VERSION ""

NS_ :

BS_:

BU_: PowertrainControlModule AtmosphericSensor SafetyRestraintSystem2 Aftertreatment_2_GasOutlet Aftertreatment_2_GasIntake DieselParticulateFilterControl Turbocharger SafetyRestraintSystem1 CabDisplay2 Aftertreatment_1_GasOutlet Aftertreatment_1_GasIntake OnBoardDataLogger OffBoardDiagnosticTool2 OffBoardDiagnosticTool1 FileServer ParkingBrakeController SeatController2 FanDriveController SteeringColumnUnit CommunicationUnitRadio CommunicationUnitSatellite CommunicationUnitCellular PropulsionBatteryCharger ChassisController2 ChassisController1 EngineValveControl AuxiliaryHeater2 AuxiliaryHeater1 ClutchUnit RampControl InformationSystem1 SuspensionSystemController2 OilSensor VehicleDynamicStability ExhaustEmissionController TransmissionDisplay2 TransmissionDisplay1 ClimateControl2 WaterPumpController RearAxleSteeringController LightingOperatorControl SeatController1 IgnitionController2 IgnitionController1 TirePressureController CabController2 CabController1 PneumaticSystemController SuspensionSystemController1 HydraulicPumpController EnduranceBrakingSystem RetarderExhaustEngine2 OnBoardDiagnosticUnit HeadwayController RetarderExhaustEngine1 CabDisplay1 ManagementComputer VirtualTerminal OffVehicleGateway PowerTakeOffFront HitchControl AuxiliaryValveControl BodyController TractorTrailerBridge1 StarterSystem ElectricalSystem VehicleSecurity VehicleNavigation AerodynamicControl ElectricalChargingSystem ClimateControl1 TripRecorder InstrumentCluster SuspensionDriveAxle2 SuspensionDriveAxle1 SuspensionSteerAxle SteeringController FuelSystem CruiseControl RetarderDriveline RetarderEngine BrakesDriveAxle2 BrakesDriveAxle1 BrakesSystemController BrakesSteerAxle AxleDrive2 AxleDrive1 AxleSteering PowerTakeOff ShiftConsoleSecondary ShiftConsolePrimary Transmission2 Transmission1 Engine2 Engine1

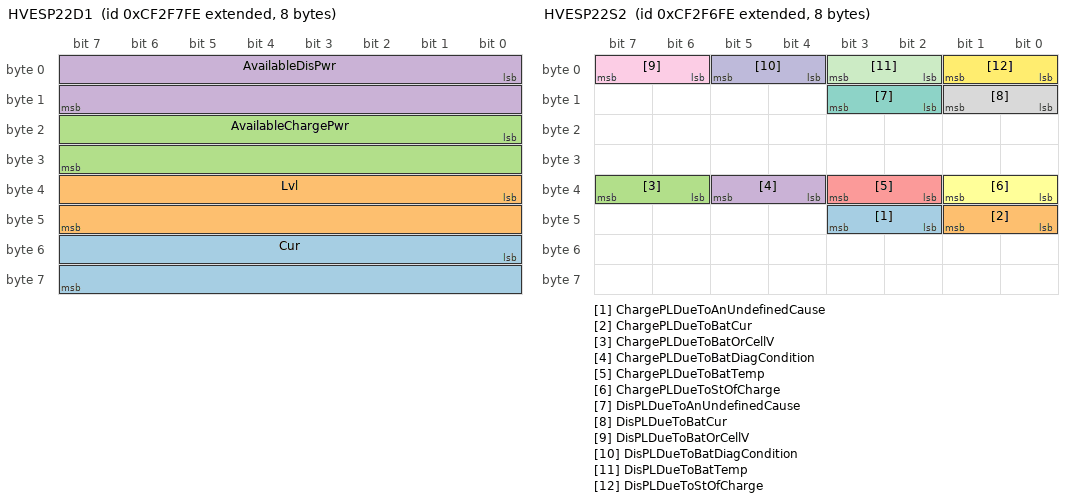
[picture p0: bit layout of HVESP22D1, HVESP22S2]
BO_ 2364733438 HVESP22D1: 8 Vector__XXX
 SG_ Cur : 48|16@1+ (0.05,-1600) [-1600|1612.75] "A" Vector__XXX
 SG_ Lvl : 32|16@1+ (0.05,0) [0|3212.75] "V" Vector__XXX
 SG_ AvailableChargePwr : 16|16@1+ (0.05,0) [0|3212.75] "kW" Vector__XXX
 SG_ AvailableDisPwr : 0|16@1+ (0.05,0) [0|3212.75] "kW" Vector__XXX

BO_ 2364733182 HVESP22S2: 8 Vector__XXX
 SG_ ChargePLDueToAnUndefinedCause : 42|2@1+ (1,0) [0|3] "" Vector__XXX
 SG_ ChargePLDueToBatCur : 40|2@1+ (1,0) [0|3] "" Vector__XXX
 SG_ ChargePLDueToBatOrCellV : 38|2@1+ (1,0) [0|3] "" Vector__XXX
 SG_ ChargePLDueToBatDiagCondition : 36|2@1+ (1,0) [0|3] "" Vector__XXX
 SG_ ChargePLDueToBatTemp : 34|2@1+ (1,0) [0|3] "" Vector__XXX
 SG_ ChargePLDueToStOfCharge : 32|2@1+ (1,0) [0|3] "" Vector__XXX
 SG_ DisPLDueToAnUndefinedCause : 10|2@1+ (1,0) [0|3] "" Vector__XXX
 SG_ DisPLDueToBatCur : 8|2@1+ (1,0) [0|3] "" Vector__XXX
 SG_ DisPLDueToBatOrCellV : 6|2@1+ (1,0) [0|3] "" Vector__XXX
 SG_ DisPLDueToBatDiagCondition : 4|2@1+ (1,0) [0|3] "" Vector__XXX
 SG_ DisPLDueToBatTemp : 2|2@1+ (1,0) [0|3] "" Vector__XXX
 SG_ DisPLDueToStOfCharge : 0|2@1+ (1,0) [0|3] "" Vector__XXX

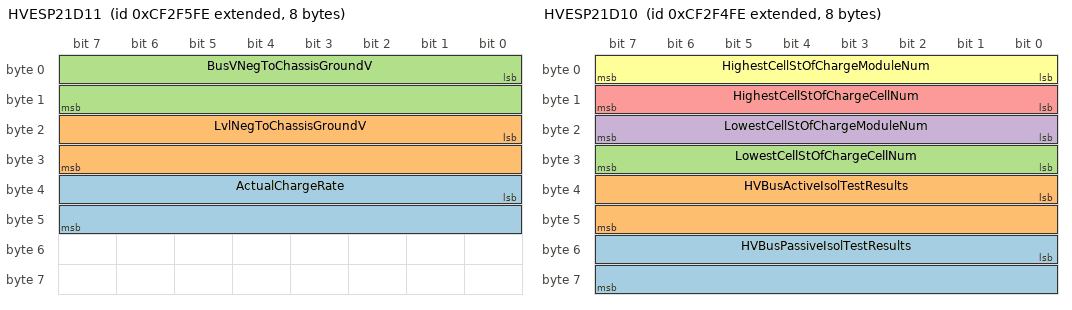
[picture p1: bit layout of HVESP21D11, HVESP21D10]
BO_ 2364732926 HVESP21D11: 8 Vector__XXX
 SG_ ActualChargeRate : 32|16@1+ (0.05,0) [0|3212.75] "kW" Vector__XXX
 SG_ LvlNegToChassisGroundV : 16|16@1+ (0.05,0) [0|3212.75] "V" Vector__XXX
 SG_ BusVNegToChassisGroundV : 0|16@1+ (0.05,0) [0|3212.75] "V" Vector__XXX

BO_ 2364732670 HVESP21D10: 8 Vector__XXX
 SG_ HVBusPassiveIsolTestResults : 48|16@1+ (0.1,0) [0|6425.5] "Ohm/V" Vector__XXX
 SG_ HVBusActiveIsolTestResults : 32|16@1+ (0.1,0) [0|6425.5] "Ohm/V" Vector__XXX
 SG_ LowestCellStOfChargeCellNum : 24|8@1+ (1,0) [0|250] "" Vector__XXX
 SG_ LowestCellStOfChargeModuleNum : 16|8@1+ (1,0) [0|250] "" Vector__XXX
 SG_ HighestCellStOfChargeCellNum : 8|8@1+ (1,0) [0|250] "" Vector__XXX
 SG_ HighestCellStOfChargeModuleNum : 0|8@1+ (1,0) [0|250] "" Vector__XXX

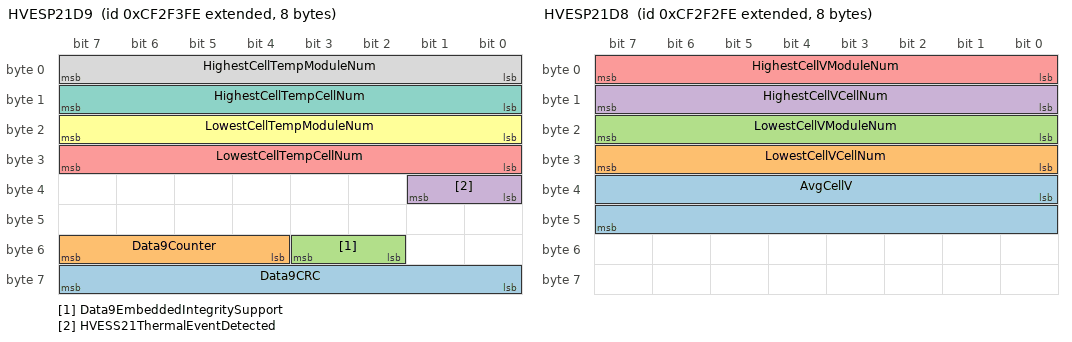
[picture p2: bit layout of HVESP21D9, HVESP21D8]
BO_ 2364732414 HVESP21D9: 8 Vector__XXX
 SG_ Data9CRC : 56|8@1+ (1,0) [0|255] "" Vector__XXX
 SG_ Data9Counter : 52|4@1+ (1,0) [0|15] "" Vector__XXX
 SG_ Data9EmbeddedIntegritySupport : 50|2@1+ (1,0) [0|3] "" Vector__XXX
 SG_ HVESS21ThermalEventDetected : 32|2@1+ (1,0) [0|3] "" Vector__XXX
 SG_ LowestCellTempCellNum : 24|8@1+ (1,0) [0|250] "" Vector__XXX
 SG_ LowestCellTempModuleNum : 16|8@1+ (1,0) [0|250] "" Vector__XXX
 SG_ HighestCellTempCellNum : 8|8@1+ (1,0) [0|250] "" Vector__XXX
 SG_ HighestCellTempModuleNum : 0|8@1+ (1,0) [0|250] "" Vector__XXX

BO_ 2364732158 HVESP21D8: 8 Vector__XXX
 SG_ AvgCellV : 32|16@1+ (0.001,0) [0|64.255] "V" Vector__XXX
 SG_ LowestCellVCellNum : 24|8@1+ (1,0) [0|250] "" Vector__XXX
 SG_ LowestCellVModuleNum : 16|8@1+ (1,0) [0|250] "" Vector__XXX
 SG_ HighestCellVCellNum : 8|8@1+ (1,0) [0|250] "" Vector__XXX
 SG_ HighestCellVModuleNum : 0|8@1+ (1,0) [0|250] "" Vector__XXX

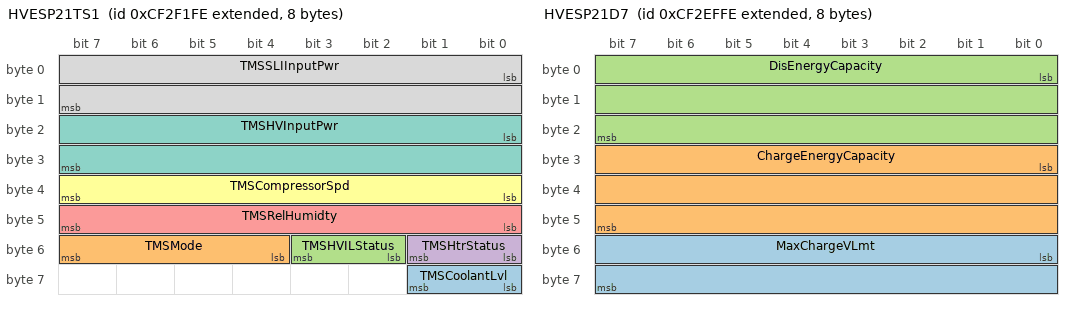
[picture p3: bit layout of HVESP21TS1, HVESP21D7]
BO_ 2364731902 HVESP21TS1: 8 Vector__XXX
 SG_ TMSCoolantLvl : 56|2@1+ (1,0) [0|3] "" Vector__XXX
 SG_ TMSMode : 52|4@1+ (1,0) [0|15] "" Vector__XXX
 SG_ TMSHVILStatus : 50|2@1+ (1,0) [0|3] "" Vector__XXX
 SG_ TMSHtrStatus : 48|2@1+ (1,0) [0|3] "" Vector__XXX
 SG_ TMSRelHumidty : 40|8@1+ (0.4,0) [0|100] "%" Vector__XXX
 SG_ TMSCompressorSpd : 32|8@1+ (32,0) [0|8000] "rpm" Vector__XXX
 SG_ TMSHVInputPwr : 16|16@1+ (0.5,0) [0|32127.5] "W" Vector__XXX
 SG_ TMSSLIInputPwr : 0|16@1+ (0.5,0) [0|32127.5] "W" Vector__XXX

BO_ 2364731646 HVESP21MS1: 8 Vector__XXX
 SG_ Module32OperationalStatus : 62|2@1+ (1,0) [0|3] "" Vector__XXX
 SG_ Module31OperationalStatus : 60|2@1+ (1,0) [0|3] "" Vector__XXX
 SG_ Module30OperationalStatus : 58|2@1+ (1,0) [0|3] "" Vector__XXX
 SG_ Module29OperationalStatus : 56|2@1+ (1,0) [0|3] "" Vector__XXX
 SG_ Module28OperationalStatus : 54|2@1+ (1,0) [0|3] "" Vector__XXX
 SG_ Module27OperationalStatus : 52|2@1+ (1,0) [0|3] "" Vector__XXX
 SG_ Module26OperationalStatus : 50|2@1+ (1,0) [0|3] "" Vector__XXX
 SG_ Module25OperationalStatus : 48|2@1+ (1,0) [0|3] "" Vector__XXX
 SG_ Module24OperationalStatus : 46|2@1+ (1,0) [0|3] "" Vector__XXX
 SG_ Module23OperationalStatus : 44|2@1+ (1,0) [0|3] "" Vector__XXX
 SG_ Module22OperationalStatus : 42|2@1+ (1,0) [0|3] "" Vector__XXX
 SG_ Module21OperationalStatus : 40|2@1+ (1,0) [0|3] "" Vector__XXX
 SG_ Module20OperationalStatus : 38|2@1+ (1,0) [0|3] "" Vector__XXX
 SG_ Module19OperationalStatus : 36|2@1+ (1,0) [0|3] "" Vector__XXX
 SG_ Module18OperationalStatus : 34|2@1+ (1,0) [0|3] "" Vector__XXX
 SG_ Module17OperationalStatus : 32|2@1+ (1,0) [0|3] "" Vector__XXX
 SG_ Module16OperationalStatus : 30|2@1+ (1,0) [0|3] "" Vector__XXX
 SG_ Module15OperationalStatus : 28|2@1+ (1,0) [0|3] "" Vector__XXX
 SG_ Module14OperationalStatus : 26|2@1+ (1,0) [0|3] "" Vector__XXX
 SG_ Module13OperationalStatus : 24|2@1+ (1,0) [0|3] "" Vector__XXX
 SG_ Module12OperationalStatus : 22|2@1+ (1,0) [0|3] "" Vector__XXX
 SG_ Module11OperationalStatus : 20|2@1+ (1,0) [0|3] "" Vector__XXX
 SG_ Module10OperationalStatus : 18|2@1+ (1,0) [0|3] "" Vector__XXX
 SG_ Module9OperationalStatus : 16|2@1+ (1,0) [0|3] "" Vector__XXX
 SG_ Module8OperationalStatus : 14|2@1+ (1,0) [0|3] "" Vector__XXX
 SG_ Module7OperationalStatus : 12|2@1+ (1,0) [0|3] "" Vector__XXX
 SG_ Module6OperationalStatus : 10|2@1+ (1,0) [0|3] "" Vector__XXX
 SG_ Module5OperationalStatus : 8|2@1+ (1,0) [0|3] "" Vector__XXX
 SG_ Module4OperationalStatus : 6|2@1+ (1,0) [0|3] "" Vector__XXX
 SG_ Module3OperationalStatus : 4|2@1+ (1,0) [0|3] "" Vector__XXX
 SG_ Module2OperationalStatus : 2|2@1+ (1,0) [0|3] "" Vector__XXX
 SG_ Module1OperationalStatus : 0|2@1+ (1,0) [0|3] "" Vector__XXX

BO_ 2364731390 HVESP21D7: 8 Vector__XXX
 SG_ MaxChargeVLmt : 48|16@1+ (0.05,0) [0|3212.75] "V" Vector__XXX
 SG_ ChargeEnergyCapacity : 24|24@1+ (0.001,0) [0|16449.535] "kWh" Vector__XXX
 SG_ DisEnergyCapacity : 0|24@1+ (0.001,0) [0|16449.535] "kWh" Vector__XXX

BO_ 2364731134 HVESP21S1: 8 Vector__XXX
 SG_ Status1CRC : 56|8@1+ (1,0) [0|255] "" Vector__XXX
 SG_ Status1Counter : 52|4@1+ (1,0) [0|15] "" Vector__XXX
 SG_ OperationalStatus : 44|4@1+ (1,0) [0|15] "" Vector__XXX
 SG_ HVBusConnectionStatus : 40|4@1+ (1,0) [0|15] "" Vector__XXX
 SG_ InternalChargerStatus : 32|2@1+ (1,0) [0|3] "" Vector__XXX
 SG_ CellBalancingActive : 30|2@1+ (1,0) [0|3] "" Vector__XXX
 SG_ CellBalanceStatus : 28|2@1+ (1,0) [0|3] "" Vector__XXX
 SG_ StOfChargeStatus : 24|4@1+ (1,0) [0|15] "" Vector__XXX
 SG_ InertiaSwStatus : 22|2@1+ (1,0) [0|3] "" Vector__XXX
 SG_ HVILStatus : 20|2@1+ (1,0) [0|3] "" Vector__XXX
 SG_ HVBusPassiveIsolTestStatus : 16|4@1+ (1,0) [0|15] "" Vector__XXX
 SG_ HVBusActiveIsolTestStatus : 12|4@1+ (1,0) [0|15] "" Vector__XXX
 SG_ CenterOfPackContactorSt : 10|2@1+ (1,0) [0|3] "" Vector__XXX
 SG_ HVBusPreChargeRelaySt : 8|2@1+ (1,0) [0|3] "" Vector__XXX
 SG_ HVBusDisconnectForewarning : 4|4@1+ (1,0) [0|15] "" Vector__XXX
 SG_ HVBusContactorSt16738 : 2|2@1+ (1,0) [0|3] "" Vector__XXX
 SG_ HVBusContactorSt : 0|2@1+ (1,0) [0|3] "" Vector__XXX

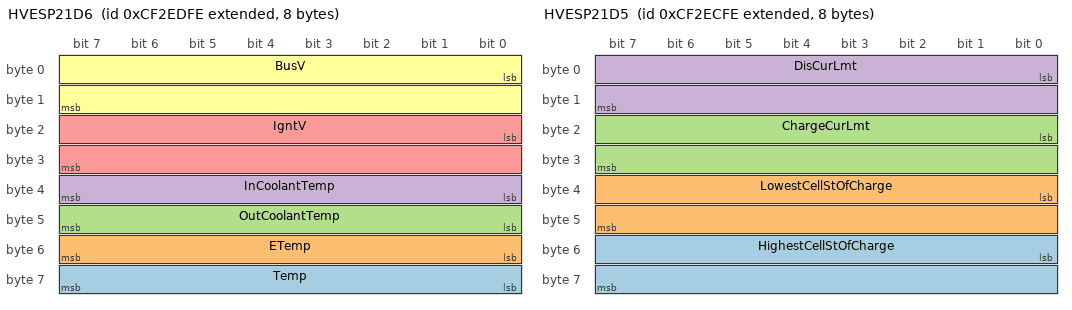
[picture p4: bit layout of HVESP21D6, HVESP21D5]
BO_ 2364730878 HVESP21D6: 8 Vector__XXX
 SG_ Temp : 56|8@1+ (1,-40) [-40|210] "°C" Vector__XXX
 SG_ ETemp : 48|8@1+ (1,-40) [-40|210] "°C" Vector__XXX
 SG_ OutCoolantTemp : 40|8@1+ (1,-40) [-40|210] "°C" Vector__XXX
 SG_ InCoolantTemp : 32|8@1+ (1,-40) [-40|210] "°C" Vector__XXX
 SG_ IgntV : 16|16@1+ (0.01,0) [0|642.55] "V" Vector__XXX
 SG_ BusV : 0|16@1+ (0.05,0) [0|3212.75] "V" Vector__XXX

BO_ 2364730622 HVESP21D5: 8 Vector__XXX
 SG_ HighestCellStOfCharge : 48|16@1+ (0.0015625,0) [0|100.3984375] "%" Vector__XXX
 SG_ LowestCellStOfCharge : 32|16@1+ (0.0015625,0) [0|100.3984375] "%" Vector__XXX
 SG_ ChargeCurLmt : 16|16@1+ (0.05,-1600) [0|1612.75] "A" Vector__XXX
 SG_ DisCurLmt : 0|16@1+ (0.05,-1600) [-1600|0] "A" Vector__XXX

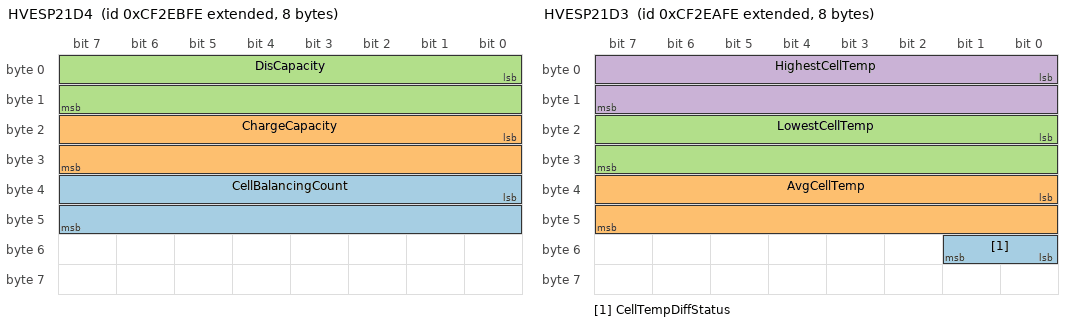
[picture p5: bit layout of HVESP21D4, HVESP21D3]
BO_ 2364730366 HVESP21D4: 8 Vector__XXX
 SG_ CellBalancingCount : 32|16@1+ (1,0) [0|64255] "" Vector__XXX
 SG_ ChargeCapacity : 16|16@1+ (0.01,0) [0|642.55] "Ah" Vector__XXX
 SG_ DisCapacity : 0|16@1+ (0.01,0) [0|642.55] "Ah" Vector__XXX

BO_ 2364730110 HVESP21D3: 8 Vector__XXX
 SG_ CellTempDiffStatus : 48|2@1+ (1,0) [0|3] "" Vector__XXX
 SG_ AvgCellTemp : 32|16@1+ (0.03125,-273) [-273|1734.96875] "°C" Vector__XXX
 SG_ LowestCellTemp : 16|16@1+ (0.03125,-273) [-273|1734.96875] "°C" Vector__XXX
 SG_ HighestCellTemp : 0|16@1+ (0.03125,-273) [-273|1734.96875] "°C" Vector__XXX

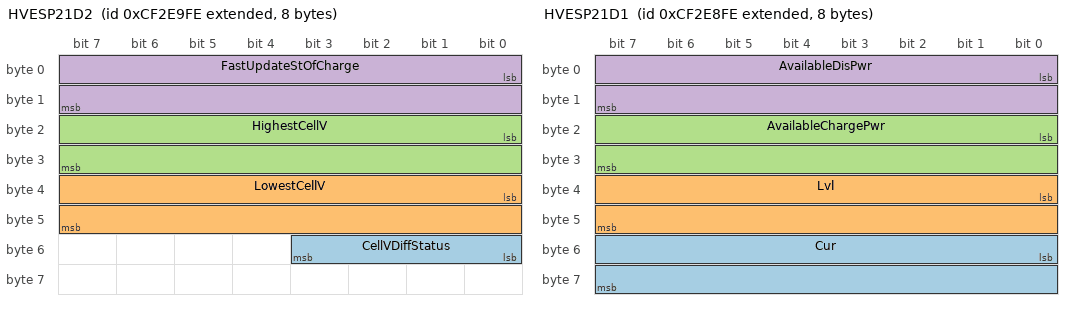
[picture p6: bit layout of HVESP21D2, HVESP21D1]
BO_ 2364729854 HVESP21D2: 8 Vector__XXX
 SG_ CellVDiffStatus : 48|4@1+ (1,0) [0|15] "" Vector__XXX
 SG_ LowestCellV : 32|16@1+ (0.001,0) [0|64.255] "V" Vector__XXX
 SG_ HighestCellV : 16|16@1+ (0.001,0) [0|64.255] "V" Vector__XXX
 SG_ FastUpdateStOfCharge : 0|16@1+ (0.0015625,0) [0|100.3984375] "%" Vector__XXX

BO_ 2364729598 HVESP21D1: 8 Vector__XXX
 SG_ Cur : 48|16@1+ (0.05,-1600) [-1600|1612.75] "A" Vector__XXX
 SG_ Lvl : 32|16@1+ (0.05,0) [0|3212.75] "V" Vector__XXX
 SG_ AvailableChargePwr : 16|16@1+ (0.05,0) [0|3212.75] "kW" Vector__XXX
 SG_ AvailableDisPwr : 0|16@1+ (0.05,0) [0|3212.75] "kW" Vector__XXX

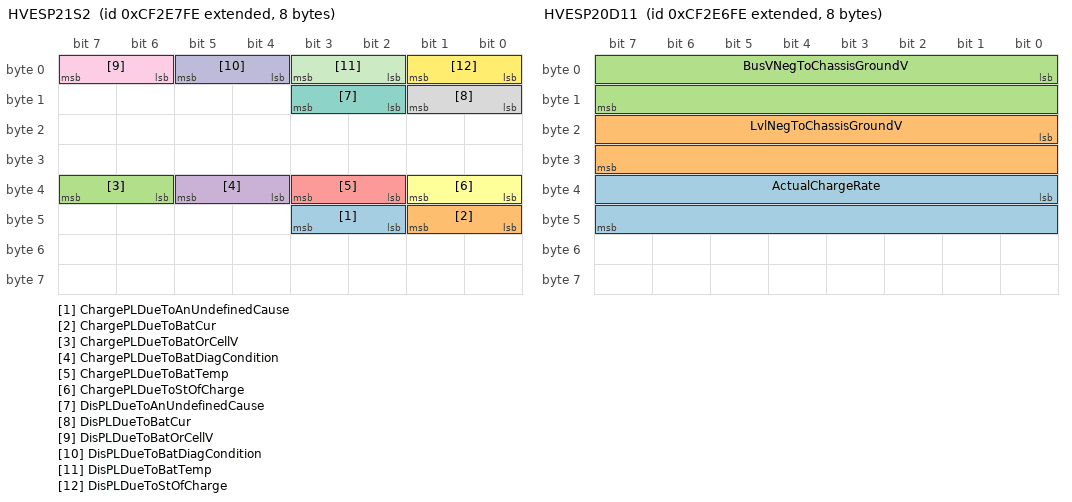
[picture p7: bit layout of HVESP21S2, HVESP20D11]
BO_ 2364729342 HVESP21S2: 8 Vector__XXX
 SG_ ChargePLDueToAnUndefinedCause : 42|2@1+ (1,0) [0|3] "" Vector__XXX
 SG_ ChargePLDueToBatCur : 40|2@1+ (1,0) [0|3] "" Vector__XXX
 SG_ ChargePLDueToBatOrCellV : 38|2@1+ (1,0) [0|3] "" Vector__XXX
 SG_ ChargePLDueToBatDiagCondition : 36|2@1+ (1,0) [0|3] "" Vector__XXX
 SG_ ChargePLDueToBatTemp : 34|2@1+ (1,0) [0|3] "" Vector__XXX
 SG_ ChargePLDueToStOfCharge : 32|2@1+ (1,0) [0|3] "" Vector__XXX
 SG_ DisPLDueToAnUndefinedCause : 10|2@1+ (1,0) [0|3] "" Vector__XXX
 SG_ DisPLDueToBatCur : 8|2@1+ (1,0) [0|3] "" Vector__XXX
 SG_ DisPLDueToBatOrCellV : 6|2@1+ (1,0) [0|3] "" Vector__XXX
 SG_ DisPLDueToBatDiagCondition : 4|2@1+ (1,0) [0|3] "" Vector__XXX
 SG_ DisPLDueToBatTemp : 2|2@1+ (1,0) [0|3] "" Vector__XXX
 SG_ DisPLDueToStOfCharge : 0|2@1+ (1,0) [0|3] "" Vector__XXX

BO_ 2364729086 HVESP20D11: 8 Vector__XXX
 SG_ ActualChargeRate : 32|16@1+ (0.05,0) [0|3212.75] "kW" Vector__XXX
 SG_ LvlNegToChassisGroundV : 16|16@1+ (0.05,0) [0|3212.75] "V" Vector__XXX
 SG_ BusVNegToChassisGroundV : 0|16@1+ (0.05,0) [0|3212.75] "V" Vector__XXX

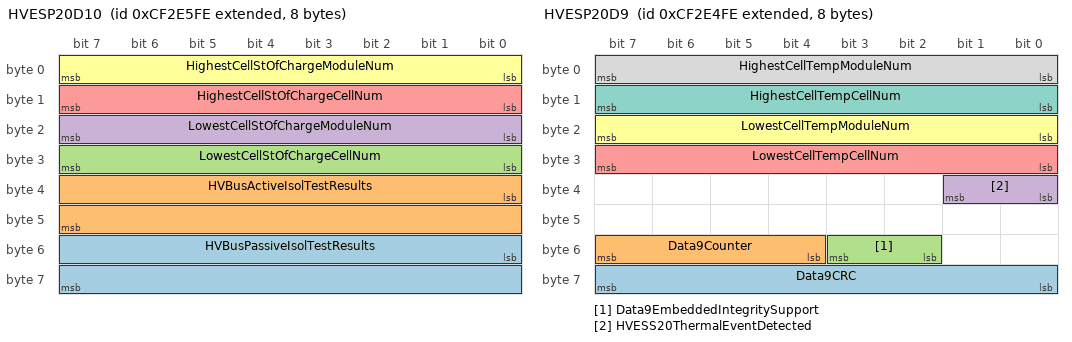
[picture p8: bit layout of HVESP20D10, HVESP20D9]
BO_ 2364728830 HVESP20D10: 8 Vector__XXX
 SG_ HVBusPassiveIsolTestResults : 48|16@1+ (0.1,0) [0|6425.5] "Ohm/V" Vector__XXX
 SG_ HVBusActiveIsolTestResults : 32|16@1+ (0.1,0) [0|6425.5] "Ohm/V" Vector__XXX
 SG_ LowestCellStOfChargeCellNum : 24|8@1+ (1,0) [0|250] "" Vector__XXX
 SG_ LowestCellStOfChargeModuleNum : 16|8@1+ (1,0) [0|250] "" Vector__XXX
 SG_ HighestCellStOfChargeCellNum : 8|8@1+ (1,0) [0|250] "" Vector__XXX
 SG_ HighestCellStOfChargeModuleNum : 0|8@1+ (1,0) [0|250] "" Vector__XXX

BO_ 2364728574 HVESP20D9: 8 Vector__XXX
 SG_ Data9CRC : 56|8@1+ (1,0) [0|255] "" Vector__XXX
 SG_ Data9Counter : 52|4@1+ (1,0) [0|15] "" Vector__XXX
 SG_ Data9EmbeddedIntegritySupport : 50|2@1+ (1,0) [0|3] "" Vector__XXX
 SG_ HVESS20ThermalEventDetected : 32|2@1+ (1,0) [0|3] "" Vector__XXX
 SG_ LowestCellTempCellNum : 24|8@1+ (1,0) [0|250] "" Vector__XXX
 SG_ LowestCellTempModuleNum : 16|8@1+ (1,0) [0|250] "" Vector__XXX
 SG_ HighestCellTempCellNum : 8|8@1+ (1,0) [0|250] "" Vector__XXX
 SG_ HighestCellTempModuleNum : 0|8@1+ (1,0) [0|250] "" Vector__XXX

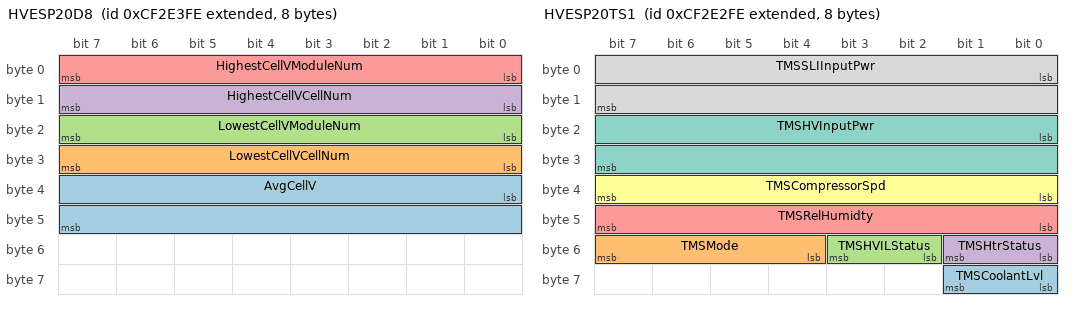
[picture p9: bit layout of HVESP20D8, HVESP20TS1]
BO_ 2364728318 HVESP20D8: 8 Vector__XXX
 SG_ AvgCellV : 32|16@1+ (0.001,0) [0|64.255] "V" Vector__XXX
 SG_ LowestCellVCellNum : 24|8@1+ (1,0) [0|250] "" Vector__XXX
 SG_ LowestCellVModuleNum : 16|8@1+ (1,0) [0|250] "" Vector__XXX
 SG_ HighestCellVCellNum : 8|8@1+ (1,0) [0|250] "" Vector__XXX
 SG_ HighestCellVModuleNum : 0|8@1+ (1,0) [0|250] "" Vector__XXX

BO_ 2364728062 HVESP20TS1: 8 Vector__XXX
 SG_ TMSCoolantLvl : 56|2@1+ (1,0) [0|3] "" Vector__XXX
 SG_ TMSMode : 52|4@1+ (1,0) [0|15] "" Vector__XXX
 SG_ TMSHVILStatus : 50|2@1+ (1,0) [0|3] "" Vector__XXX
 SG_ TMSHtrStatus : 48|2@1+ (1,0) [0|3] "" Vector__XXX
 SG_ TMSRelHumidty : 40|8@1+ (0.4,0) [0|100] "%" Vector__XXX
 SG_ TMSCompressorSpd : 32|8@1+ (32,0) [0|8000] "rpm" Vector__XXX
 SG_ TMSHVInputPwr : 16|16@1+ (0.5,0) [0|32127.5] "W" Vector__XXX
 SG_ TMSSLIInputPwr : 0|16@1+ (0.5,0) [0|32127.5] "W" Vector__XXX

BO_ 2364727806 HVESP20MS1: 8 Vector__XXX
 SG_ Module32OperationalStatus : 62|2@1+ (1,0) [0|3] "" Vector__XXX
 SG_ Module31OperationalStatus : 60|2@1+ (1,0) [0|3] "" Vector__XXX
 SG_ Module30OperationalStatus : 58|2@1+ (1,0) [0|3] "" Vector__XXX
 SG_ Module29OperationalStatus : 56|2@1+ (1,0) [0|3] "" Vector__XXX
 SG_ Module28OperationalStatus : 54|2@1+ (1,0) [0|3] "" Vector__XXX
 SG_ Module27OperationalStatus : 52|2@1+ (1,0) [0|3] "" Vector__XXX
 SG_ Module26OperationalStatus : 50|2@1+ (1,0) [0|3] "" Vector__XXX
 SG_ Module25OperationalStatus : 48|2@1+ (1,0) [0|3] "" Vector__XXX
 SG_ Module24OperationalStatus : 46|2@1+ (1,0) [0|3] "" Vector__XXX
 SG_ Module23OperationalStatus : 44|2@1+ (1,0) [0|3] "" Vector__XXX
 SG_ Module22OperationalStatus : 42|2@1+ (1,0) [0|3] "" Vector__XXX
 SG_ Module21OperationalStatus : 40|2@1+ (1,0) [0|3] "" Vector__XXX
 SG_ Module20OperationalStatus : 38|2@1+ (1,0) [0|3] "" Vector__XXX
 SG_ Module19OperationalStatus : 36|2@1+ (1,0) [0|3] "" Vector__XXX
 SG_ Module18OperationalStatus : 34|2@1+ (1,0) [0|3] "" Vector__XXX
 SG_ Module17OperationalStatus : 32|2@1+ (1,0) [0|3] "" Vector__XXX
 SG_ Module16OperationalStatus : 30|2@1+ (1,0) [0|3] "" Vector__XXX
 SG_ Module15OperationalStatus : 28|2@1+ (1,0) [0|3] "" Vector__XXX
 SG_ Module14OperationalStatus : 26|2@1+ (1,0) [0|3] "" Vector__XXX
 SG_ Module13OperationalStatus : 24|2@1+ (1,0) [0|3] "" Vector__XXX
 SG_ Module12OperationalStatus : 22|2@1+ (1,0) [0|3] "" Vector__XXX
 SG_ Module11OperationalStatus : 20|2@1+ (1,0) [0|3] "" Vector__XXX
 SG_ Module10OperationalStatus : 18|2@1+ (1,0) [0|3] "" Vector__XXX
 SG_ Module9OperationalStatus : 16|2@1+ (1,0) [0|3] "" Vector__XXX
 SG_ Module8OperationalStatus : 14|2@1+ (1,0) [0|3] "" Vector__XXX
 SG_ Module7OperationalStatus : 12|2@1+ (1,0) [0|3] "" Vector__XXX
 SG_ Module6OperationalStatus : 10|2@1+ (1,0) [0|3] "" Vector__XXX
 SG_ Module5OperationalStatus : 8|2@1+ (1,0) [0|3] "" Vector__XXX
 SG_ Module4OperationalStatus : 6|2@1+ (1,0) [0|3] "" Vector__XXX
 SG_ Module3OperationalStatus : 4|2@1+ (1,0) [0|3] "" Vector__XXX
 SG_ Module2OperationalStatus : 2|2@1+ (1,0) [0|3] "" Vector__XXX
 SG_ Module1OperationalStatus : 0|2@1+ (1,0) [0|3] "" Vector__XXX

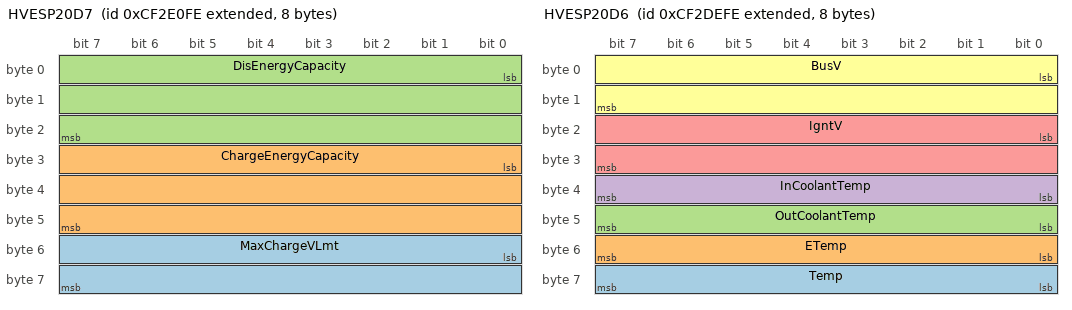
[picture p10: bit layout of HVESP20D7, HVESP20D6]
BO_ 2364727550 HVESP20D7: 8 Vector__XXX
 SG_ MaxChargeVLmt : 48|16@1+ (0.05,0) [0|3212.75] "V" Vector__XXX
 SG_ ChargeEnergyCapacity : 24|24@1+ (0.001,0) [0|16449.535] "kWh" Vector__XXX
 SG_ DisEnergyCapacity : 0|24@1+ (0.001,0) [0|16449.535] "kWh" Vector__XXX

BO_ 2364727294 HVESP20S1: 8 Vector__XXX
 SG_ Status1CRC : 56|8@1+ (1,0) [0|255] "" Vector__XXX
 SG_ Status1Counter : 52|4@1+ (1,0) [0|15] "" Vector__XXX
 SG_ OperationalStatus : 44|4@1+ (1,0) [0|15] "" Vector__XXX
 SG_ HVBusConnectionStatus : 40|4@1+ (1,0) [0|15] "" Vector__XXX
 SG_ InternalChargerStatus : 32|2@1+ (1,0) [0|3] "" Vector__XXX
 SG_ CellBalancingActive : 30|2@1+ (1,0) [0|3] "" Vector__XXX
 SG_ CellBalanceStatus : 28|2@1+ (1,0) [0|3] "" Vector__XXX
 SG_ StOfChargeStatus : 24|4@1+ (1,0) [0|15] "" Vector__XXX
 SG_ InertiaSwStatus : 22|2@1+ (1,0) [0|3] "" Vector__XXX
 SG_ HVILStatus : 20|2@1+ (1,0) [0|3] "" Vector__XXX
 SG_ HVBusPassiveIsolTestStatus : 16|4@1+ (1,0) [0|15] "" Vector__XXX
 SG_ HVBusActiveIsolTestStatus : 12|4@1+ (1,0) [0|15] "" Vector__XXX
 SG_ CenterOfPackContactorSt : 10|2@1+ (1,0) [0|3] "" Vector__XXX
 SG_ HVBusPreChargeRelaySt : 8|2@1+ (1,0) [0|3] "" Vector__XXX
 SG_ HVBusDisconnectForewarning : 4|4@1+ (1,0) [0|15] "" Vector__XXX
 SG_ HVBusContactorSt16596 : 2|2@1+ (1,0) [0|3] "" Vector__XXX
 SG_ HVBusContactorSt : 0|2@1+ (1,0) [0|3] "" Vector__XXX

BO_ 2364727038 HVESP20D6: 8 Vector__XXX
 SG_ Temp : 56|8@1+ (1,-40) [-40|210] "°C" Vector__XXX
 SG_ ETemp : 48|8@1+ (1,-40) [-40|210] "°C" Vector__XXX
 SG_ OutCoolantTemp : 40|8@1+ (1,-40) [-40|210] "°C" Vector__XXX
 SG_ InCoolantTemp : 32|8@1+ (1,-40) [-40|210] "°C" Vector__XXX
 SG_ IgntV : 16|16@1+ (0.01,0) [0|642.55] "V" Vector__XXX
 SG_ BusV : 0|16@1+ (0.05,0) [0|3212.75] "V" Vector__XXX

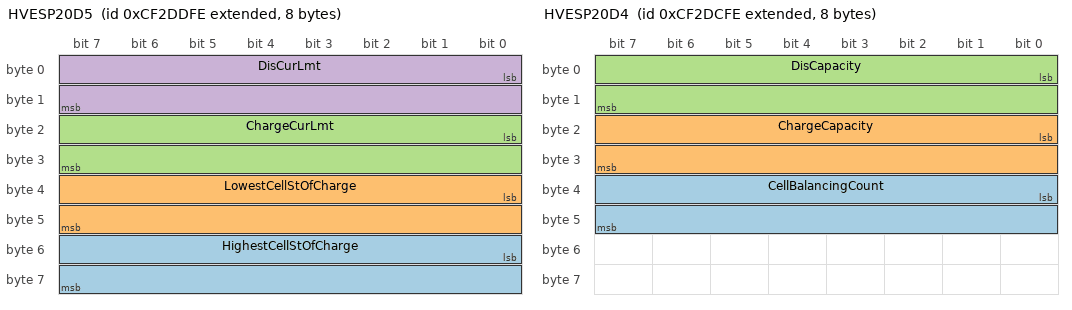
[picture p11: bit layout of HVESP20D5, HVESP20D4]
BO_ 2364726782 HVESP20D5: 8 Vector__XXX
 SG_ HighestCellStOfCharge : 48|16@1+ (0.0015625,0) [0|100.3984375] "%" Vector__XXX
 SG_ LowestCellStOfCharge : 32|16@1+ (0.0015625,0) [0|100.3984375] "%" Vector__XXX
 SG_ ChargeCurLmt : 16|16@1+ (0.05,-1600) [0|1612.75] "A" Vector__XXX
 SG_ DisCurLmt : 0|16@1+ (0.05,-1600) [-1600|0] "A" Vector__XXX

BO_ 2364726526 HVESP20D4: 8 Vector__XXX
 SG_ CellBalancingCount : 32|16@1+ (1,0) [0|64255] "" Vector__XXX
 SG_ ChargeCapacity : 16|16@1+ (0.01,0) [0|642.55] "Ah" Vector__XXX
 SG_ DisCapacity : 0|16@1+ (0.01,0) [0|642.55] "Ah" Vector__XXX

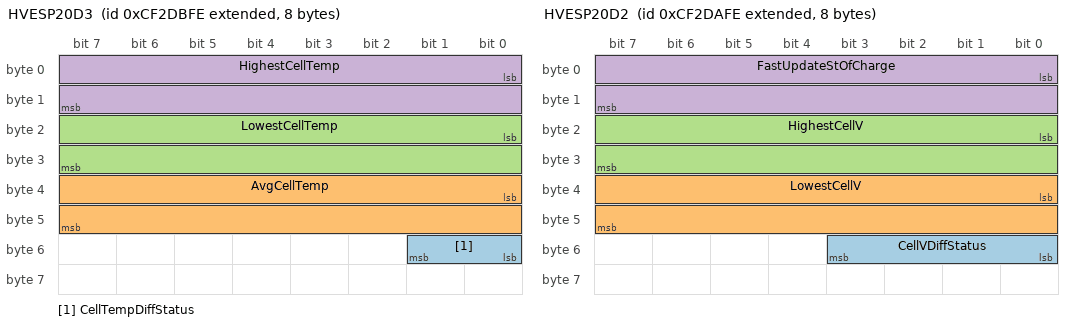
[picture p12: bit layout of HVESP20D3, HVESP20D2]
BO_ 2364726270 HVESP20D3: 8 Vector__XXX
 SG_ CellTempDiffStatus : 48|2@1+ (1,0) [0|3] "" Vector__XXX
 SG_ AvgCellTemp : 32|16@1+ (0.03125,-273) [-273|1734.96875] "°C" Vector__XXX
 SG_ LowestCellTemp : 16|16@1+ (0.03125,-273) [-273|1734.96875] "°C" Vector__XXX
 SG_ HighestCellTemp : 0|16@1+ (0.03125,-273) [-273|1734.96875] "°C" Vector__XXX

BO_ 2364726014 HVESP20D2: 8 Vector__XXX
 SG_ CellVDiffStatus : 48|4@1+ (1,0) [0|15] "" Vector__XXX
 SG_ LowestCellV : 32|16@1+ (0.001,0) [0|64.255] "V" Vector__XXX
 SG_ HighestCellV : 16|16@1+ (0.001,0) [0|64.255] "V" Vector__XXX
 SG_ FastUpdateStOfCharge : 0|16@1+ (0.0015625,0) [0|100.3984375] "%" Vector__XXX

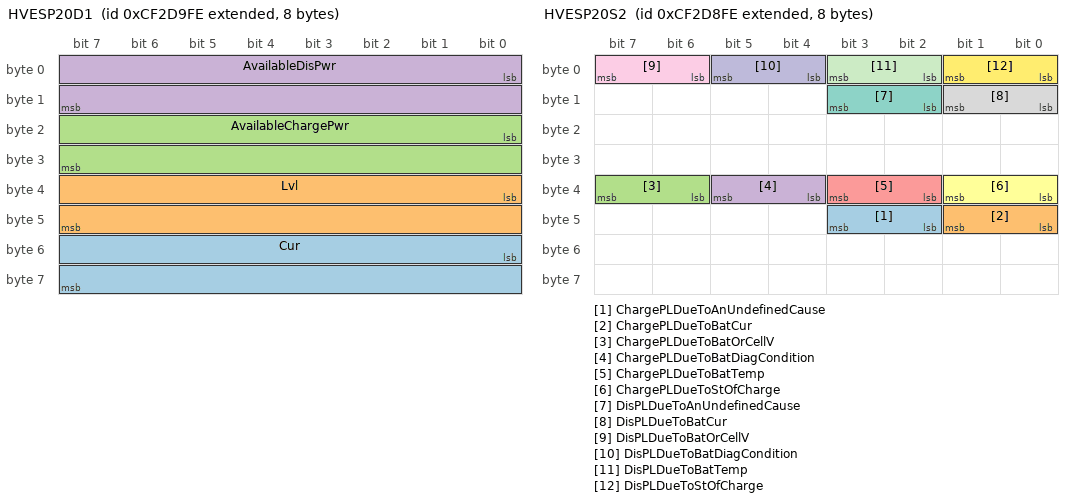
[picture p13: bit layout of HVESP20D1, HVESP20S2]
BO_ 2364725758 HVESP20D1: 8 Vector__XXX
 SG_ Cur : 48|16@1+ (0.05,-1600) [-1600|1612.75] "A" Vector__XXX
 SG_ Lvl : 32|16@1+ (0.05,0) [0|3212.75] "V" Vector__XXX
 SG_ AvailableChargePwr : 16|16@1+ (0.05,0) [0|3212.75] "kW" Vector__XXX
 SG_ AvailableDisPwr : 0|16@1+ (0.05,0) [0|3212.75] "kW" Vector__XXX

BO_ 2364725502 HVESP20S2: 8 Vector__XXX
 SG_ ChargePLDueToAnUndefinedCause : 42|2@1+ (1,0) [0|3] "" Vector__XXX
 SG_ ChargePLDueToBatCur : 40|2@1+ (1,0) [0|3] "" Vector__XXX
 SG_ ChargePLDueToBatOrCellV : 38|2@1+ (1,0) [0|3] "" Vector__XXX
 SG_ ChargePLDueToBatDiagCondition : 36|2@1+ (1,0) [0|3] "" Vector__XXX
 SG_ ChargePLDueToBatTemp : 34|2@1+ (1,0) [0|3] "" Vector__XXX
 SG_ ChargePLDueToStOfCharge : 32|2@1+ (1,0) [0|3] "" Vector__XXX
 SG_ DisPLDueToAnUndefinedCause : 10|2@1+ (1,0) [0|3] "" Vector__XXX
 SG_ DisPLDueToBatCur : 8|2@1+ (1,0) [0|3] "" Vector__XXX
 SG_ DisPLDueToBatOrCellV : 6|2@1+ (1,0) [0|3] "" Vector__XXX
 SG_ DisPLDueToBatDiagCondition : 4|2@1+ (1,0) [0|3] "" Vector__XXX
 SG_ DisPLDueToBatTemp : 2|2@1+ (1,0) [0|3] "" Vector__XXX
 SG_ DisPLDueToStOfCharge : 0|2@1+ (1,0) [0|3] "" Vector__XXX

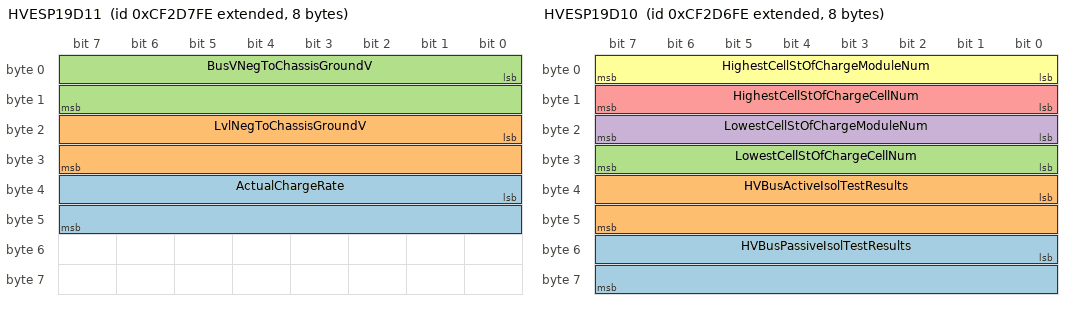
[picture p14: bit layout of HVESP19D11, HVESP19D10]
BO_ 2364725246 HVESP19D11: 8 Vector__XXX
 SG_ ActualChargeRate : 32|16@1+ (0.05,0) [0|3212.75] "kW" Vector__XXX
 SG_ LvlNegToChassisGroundV : 16|16@1+ (0.05,0) [0|3212.75] "V" Vector__XXX
 SG_ BusVNegToChassisGroundV : 0|16@1+ (0.05,0) [0|3212.75] "V" Vector__XXX

BO_ 2364724990 HVESP19D10: 8 Vector__XXX
 SG_ HVBusPassiveIsolTestResults : 48|16@1+ (0.1,0) [0|6425.5] "Ohm/V" Vector__XXX
 SG_ HVBusActiveIsolTestResults : 32|16@1+ (0.1,0) [0|6425.5] "Ohm/V" Vector__XXX
 SG_ LowestCellStOfChargeCellNum : 24|8@1+ (1,0) [0|250] "" Vector__XXX
 SG_ LowestCellStOfChargeModuleNum : 16|8@1+ (1,0) [0|250] "" Vector__XXX
 SG_ HighestCellStOfChargeCellNum : 8|8@1+ (1,0) [0|250] "" Vector__XXX
 SG_ HighestCellStOfChargeModuleNum : 0|8@1+ (1,0) [0|250] "" Vector__XXX

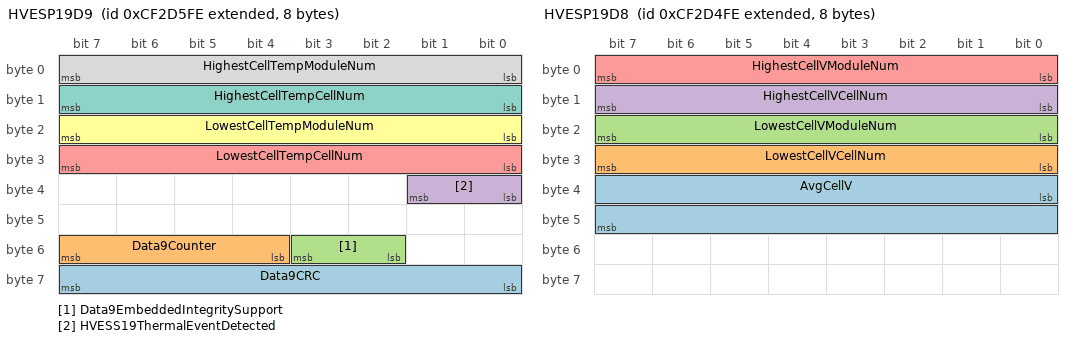
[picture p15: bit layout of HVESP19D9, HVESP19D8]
BO_ 2364724734 HVESP19D9: 8 Vector__XXX
 SG_ Data9CRC : 56|8@1+ (1,0) [0|255] "" Vector__XXX
 SG_ Data9Counter : 52|4@1+ (1,0) [0|15] "" Vector__XXX
 SG_ Data9EmbeddedIntegritySupport : 50|2@1+ (1,0) [0|3] "" Vector__XXX
 SG_ HVESS19ThermalEventDetected : 32|2@1+ (1,0) [0|3] "" Vector__XXX
 SG_ LowestCellTempCellNum : 24|8@1+ (1,0) [0|250] "" Vector__XXX
 SG_ LowestCellTempModuleNum : 16|8@1+ (1,0) [0|250] "" Vector__XXX
 SG_ HighestCellTempCellNum : 8|8@1+ (1,0) [0|250] "" Vector__XXX
 SG_ HighestCellTempModuleNum : 0|8@1+ (1,0) [0|250] "" Vector__XXX

BO_ 2364724478 HVESP19D8: 8 Vector__XXX
 SG_ AvgCellV : 32|16@1+ (0.001,0) [0|64.255] "V" Vector__XXX
 SG_ LowestCellVCellNum : 24|8@1+ (1,0) [0|250] "" Vector__XXX
 SG_ LowestCellVModuleNum : 16|8@1+ (1,0) [0|250] "" Vector__XXX
 SG_ HighestCellVCellNum : 8|8@1+ (1,0) [0|250] "" Vector__XXX
 SG_ HighestCellVModuleNum : 0|8@1+ (1,0) [0|250] "" Vector__XXX

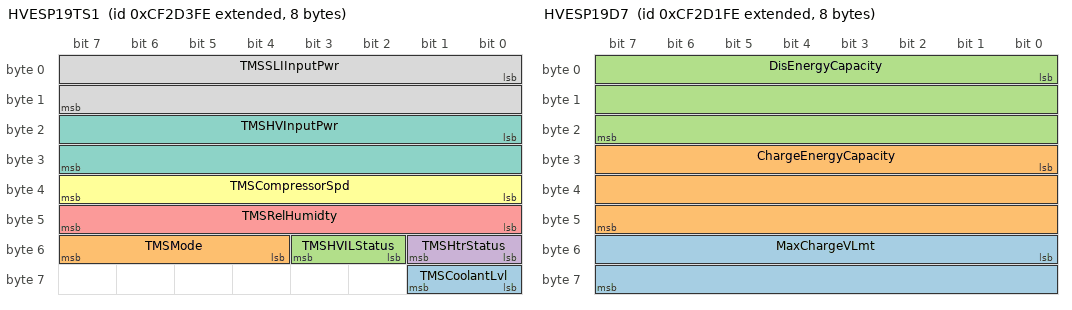
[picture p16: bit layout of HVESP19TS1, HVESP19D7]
BO_ 2364724222 HVESP19TS1: 8 Vector__XXX
 SG_ TMSCoolantLvl : 56|2@1+ (1,0) [0|3] "" Vector__XXX
 SG_ TMSMode : 52|4@1+ (1,0) [0|15] "" Vector__XXX
 SG_ TMSHVILStatus : 50|2@1+ (1,0) [0|3] "" Vector__XXX
 SG_ TMSHtrStatus : 48|2@1+ (1,0) [0|3] "" Vector__XXX
 SG_ TMSRelHumidty : 40|8@1+ (0.4,0) [0|100] "%" Vector__XXX
 SG_ TMSCompressorSpd : 32|8@1+ (32,0) [0|8000] "rpm" Vector__XXX
 SG_ TMSHVInputPwr : 16|16@1+ (0.5,0) [0|32127.5] "W" Vector__XXX
 SG_ TMSSLIInputPwr : 0|16@1+ (0.5,0) [0|32127.5] "W" Vector__XXX

BO_ 2364723966 HVESP19MS1: 8 Vector__XXX
 SG_ Module32OperationalStatus : 62|2@1+ (1,0) [0|3] "" Vector__XXX
 SG_ Module31OperationalStatus : 60|2@1+ (1,0) [0|3] "" Vector__XXX
 SG_ Module30OperationalStatus : 58|2@1+ (1,0) [0|3] "" Vector__XXX
 SG_ Module29OperationalStatus : 56|2@1+ (1,0) [0|3] "" Vector__XXX
 SG_ Module28OperationalStatus : 54|2@1+ (1,0) [0|3] "" Vector__XXX
 SG_ Module27OperationalStatus : 52|2@1+ (1,0) [0|3] "" Vector__XXX
 SG_ Module26OperationalStatus : 50|2@1+ (1,0) [0|3] "" Vector__XXX
 SG_ Module25OperationalStatus : 48|2@1+ (1,0) [0|3] "" Vector__XXX
 SG_ Module24OperationalStatus : 46|2@1+ (1,0) [0|3] "" Vector__XXX
 SG_ Module23OperationalStatus : 44|2@1+ (1,0) [0|3] "" Vector__XXX
 SG_ Module22OperationalStatus : 42|2@1+ (1,0) [0|3] "" Vector__XXX
 SG_ Module21OperationalStatus : 40|2@1+ (1,0) [0|3] "" Vector__XXX
 SG_ Module20OperationalStatus : 38|2@1+ (1,0) [0|3] "" Vector__XXX
 SG_ Module19OperationalStatus : 36|2@1+ (1,0) [0|3] "" Vector__XXX
 SG_ Module18OperationalStatus : 34|2@1+ (1,0) [0|3] "" Vector__XXX
 SG_ Module17OperationalStatus : 32|2@1+ (1,0) [0|3] "" Vector__XXX
 SG_ Module16OperationalStatus : 30|2@1+ (1,0) [0|3] "" Vector__XXX
 SG_ Module15OperationalStatus : 28|2@1+ (1,0) [0|3] "" Vector__XXX
 SG_ Module14OperationalStatus : 26|2@1+ (1,0) [0|3] "" Vector__XXX
 SG_ Module13OperationalStatus : 24|2@1+ (1,0) [0|3] "" Vector__XXX
 SG_ Module12OperationalStatus : 22|2@1+ (1,0) [0|3] "" Vector__XXX
 SG_ Module11OperationalStatus : 20|2@1+ (1,0) [0|3] "" Vector__XXX
 SG_ Module10OperationalStatus : 18|2@1+ (1,0) [0|3] "" Vector__XXX
 SG_ Module9OperationalStatus : 16|2@1+ (1,0) [0|3] "" Vector__XXX
 SG_ Module8OperationalStatus : 14|2@1+ (1,0) [0|3] "" Vector__XXX
 SG_ Module7OperationalStatus : 12|2@1+ (1,0) [0|3] "" Vector__XXX
 SG_ Module6OperationalStatus : 10|2@1+ (1,0) [0|3] "" Vector__XXX
 SG_ Module5OperationalStatus : 8|2@1+ (1,0) [0|3] "" Vector__XXX
 SG_ Module4OperationalStatus : 6|2@1+ (1,0) [0|3] "" Vector__XXX
 SG_ Module3OperationalStatus : 4|2@1+ (1,0) [0|3] "" Vector__XXX
 SG_ Module2OperationalStatus : 2|2@1+ (1,0) [0|3] "" Vector__XXX
 SG_ Module1OperationalStatus : 0|2@1+ (1,0) [0|3] "" Vector__XXX

BO_ 2364723710 HVESP19D7: 8 Vector__XXX
 SG_ MaxChargeVLmt : 48|16@1+ (0.05,0) [0|3212.75] "V" Vector__XXX
 SG_ ChargeEnergyCapacity : 24|24@1+ (0.001,0) [0|16449.535] "kWh" Vector__XXX
 SG_ DisEnergyCapacity : 0|24@1+ (0.001,0) [0|16449.535] "kWh" Vector__XXX

CM_ BO_ 2364733438 "High Voltage Energy Storage Pack 22 Data 1
Data set 1 (electrical data) for High Voltage Energy Storage Pack 22.";
CM_ SG_ 2364733438 Cur "The current in or out of this High Voltage Energy Storage Pack instance. This parameter should be synchronized with SPN 16856 (HVESP22 Voltage Level) such that a realized power value can be calculated. This parameter is defined from the high voltage ...";
CM_ SG_ 2364733438 Lvl "The voltage level of this High Voltage Energy Storage Pack instance. This parameter should be synchronized with SPN 16857 (HVESP22 Current) such that a realized power value can be calculated. If the HVES component physically contains the contactors ...";
CM_ SG_ 2364733438 AvailableChargePwr "The rate at which this High Voltage Energy Storage Pack instance can currently receive energy from a regenerative or recharging system.
This parameter is for one of multiple packs in an HVESS.  If there is only one pack in the system, the HVESS ...";
CM_ SG_ 2364733438 AvailableDisPwr "The rate at which this High Voltage Energy Storage Pack instance can currently provide energy for propulsion or other uses.
This parameter is for one of multiple packs in an HVESS.  If there is only one pack in the system, the HVESS parameters ...";
CM_ BO_ 2364733182 "High Voltage Energy Storage Pack 22 Status 2
Status data set 2 for High Voltage Energy Storage Pack 22.";
CM_ SG_ 2364733182 ChargePLDueToAnUndefinedCause "Indicates whether or not charge power of this HVES instance is being limited due to an undefined cause.
This parameter is for one of multiple packs in an HVESS.  If there is only one pack in the system, the HVESS parameters should be used. If there ...";
CM_ SG_ 2364733182 ChargePLDueToBatCur "Indicates whether or not charge power of this HVES instance is being limited due to battery current.
This parameter is for one of multiple packs in an HVESS.  If there is only one pack in the system, the HVESS parameters should be used. If there ...";
CM_ SG_ 2364733182 ChargePLDueToBatOrCellV "Indicates whether or not charge power of this HVES instance is being limited due to a battery or cell voltage level.
This parameter is for one of multiple packs in an HVESS.  If there is only one pack in the system, the HVESS parameters should be ...";
CM_ SG_ 2364733182 ChargePLDueToBatDiagCondition "Indicates whether or not charge power of this HVES instance is being limited due to a battery diagnostic condition.
This parameter is for one of multiple packs in an HVESS.  If there is only one pack in the system, the HVESS parameters should be ...";
CM_ SG_ 2364733182 ChargePLDueToBatTemp "Indicates whether or not charge power of this HVES instance is being limited due to battery temperature.
This parameter is for one of multiple packs in an HVESS.  If there is only one pack in the system, the HVESS parameters should be used. If ...";
CM_ SG_ 2364733182 ChargePLDueToStOfCharge "Indicates whether or not charge power of this HVES instance is being limited due to state of charge.
This parameter is for one of multiple packs in an HVESS.  If there is only one pack in the system, the HVESS parameters should be used. If there ...";
CM_ SG_ 2364733182 DisPLDueToAnUndefinedCause "Indicates whether or not discharge power of this HVES instance is being limited due to an undefined cause.
This parameter is for one of multiple packs in an HVESS.  If there is only one pack in the system, the HVESS parameters should be used. If ...";
CM_ SG_ 2364733182 DisPLDueToBatCur "Indicates whether or not discharge power of this HVES instance is being limited due to battery current.
This parameter is for one of multiple packs in an HVESS.  If there is only one pack in the system, the HVESS parameters should be used. If there ...";
CM_ SG_ 2364733182 DisPLDueToBatOrCellV "Indicates whether or not discharge power of this HVES instance is being limited due to a battery or cell voltage level.
This parameter is for one of multiple packs in an HVESS.  If there is only one pack in the system, the HVESS parameters should ...";
CM_ SG_ 2364733182 DisPLDueToBatDiagCondition "Indicates whether or not discharge power of this HVES instance is being limited due to a battery diagnostic condition.
This parameter is for one of multiple packs in an HVESS.  If there is only one pack in the system, the HVESS parameters should be ...";
CM_ SG_ 2364733182 DisPLDueToBatTemp "Indicates whether or not discharge power of this HVES instance is being limited due to battery temperature.
This parameter is for one of multiple packs in an HVESS.  If there is only one pack in the system, the HVESS parameters should be used. If ...";
CM_ SG_ 2364733182 DisPLDueToStOfCharge "Indicates whether or not discharge power of this HVES instance is being limited due to state of charge.
This parameter is for one of multiple packs in an HVESS.  If there is only one pack in the system, the HVESS parameters should be used. If there ...";
CM_ BO_ 2364732926 "High Voltage Energy Storage Pack 21 Data 11
Data set 11 (electrical data) for High Voltage Energy Storage Pack 21.";
CM_ SG_ 2364732926 ActualChargeRate "This signal represents the actual present charge rate of this High Voltage Energy Storage Pack instance.
This parameter is for one of multiple packs in an HVESS. If there is only one pack in the system, the HVESS parameters should be used. If there ...";
CM_ SG_ 2364732926 LvlNegToChassisGroundV "Voltage difference between the most negative terminal of the HVES battery and chassis measured at the battery side of any HVES contained output contactor.  This voltage may be used for system level monitoring of battery shorts to chassis within the ...";
CM_ SG_ 2364732926 BusVNegToChassisGroundV "Voltage difference between the most negative terminal of the HVES battery and chassis measured on the hybrid system bus side (not the battery side) of any HVES contained output contactor.  This voltage may be used for system level monitoring of ...";
CM_ BO_ 2364732670 "High Voltage Energy Storage Pack 21 Data 10
Data set 10 (electrical) for High Voltage Energy Storage Pack 21.";
CM_ SG_ 2364732670 HVBusPassiveIsolTestResults "The isolation resistance expressed in Ohms per Volt that resulted from the High-Voltage Bus Passive Isolation Test.
See SPN 16743 (HVESP21 High-Voltage Bus Passive Isolation Test Status) for test status and SPN 16692 (HVESP21 High-Voltage Bus ...";
CM_ SG_ 2364732670 HVBusActiveIsolTestResults "The isolation resistance expressed in Ohms per Volt that resulted from the High-Voltage Bus Active Isolation Test.
See SPN 16742 (HVESP21 High-Voltage Bus Active Isolation Test Status) for test status and SPN 16691 (HVESP21 High-Voltage Bus Active ...";
CM_ SG_ 2364732670 LowestCellStOfChargeCellNum "Identifies the location of SPN 16729 (HVESP21 Lowest Cell State of Charge) within SPN 16808 (HVESP21 Lowest Cell State of Charge Module Number).
This parameter is for one of multiple packs in an HVESS. If there is only one pack in the system, the ...";
CM_ SG_ 2364732670 LowestCellStOfChargeModuleNum "Identifies the location of the module containing SPN 16729 (HVESP21 Lowest Cell State of Charge).
This parameter is for one of multiple packs in an HVESS. If there is only one pack in the system, the HVESS parameters should be used. If there are ...";
CM_ SG_ 2364732670 HighestCellStOfChargeCellNum "Identifies the location of SPN 16730 (HVESP21 Highest Cell State of Charge) within SPN 16806 (HVESP21 Highest Cell State of Charge Module Number).
This parameter is for one of multiple packs in an HVESS. If there is only one pack in the system, the ...";
CM_ SG_ 2364732670 HighestCellStOfChargeModuleNum "Identifies the location of the module containing SPN 16730 (HVESP21 Highest Cell State of Charge).
This parameter is for one of multiple packs in an HVESS. If there is only one pack in the system, the HVESS parameters should be used. If there are ...";
CM_ BO_ 2364732414 "High Voltage Energy Storage Pack 21 Data 9
Data set 9 (thermal) for High Voltage Energy Storage Pack 21.";
CM_ SG_ 2364732414 Data9CRC "The CRC is defined as follows:
• Length: 8 bits
• Polynomial: x^8+x^5+x^3+x^2+x+1
• Initial Value: FFh
• Input Data Reflection: Not reflected
• Result Data Reflection: Not reflected
• XOR value: FFh
SAE makes no claim of the functional safety ...";
CM_ SG_ 2364732414 Data9Counter "The message counter is used to detect situations where the transmitting ECU malfunction repeats the same frame all the time. The receiver of the information may use the counter parameter to detect this situation. The transmitting device will ...";
CM_ SG_ 2364732414 Data9EmbeddedIntegritySupport "Indicates SPN 23036 (HVESP21 Data 9 CRC) and SPN 23035 (HVESP21 Data 9 Counter) are supported by the sender.
00b = Embedded CRC and Counter are supported by the sender
01b = Protection is supported using J1939-76 SHM
10b = Reserved
11b = CRC and ...";
CM_ SG_ 2364732414 HVESS21ThermalEventDetected "A sensor has detected the presence of a thermal event at or near High Voltage Energy Storage Pack instance.
00b = No Thermal Event Detected
01b = Thermal Event Detected
10b = Error
11b = Not available
This parameter is for one of multiple packs ...";
CM_ SG_ 2364732414 LowestCellTempCellNum "Identifies the location of SPN 16721 (HVESP21 Lowest Cell Temperature) within SPN 16804 (HVESP21 Lowest Cell Temperature Module Number).
This parameter is for one of multiple packs in an HVESS. If there is only one pack in the system, the HVESS ...";
CM_ SG_ 2364732414 LowestCellTempModuleNum "Identifies the location of the module containing SPN 16721 (HVESP21 Lowest Cell Temperature).
This parameter is for one of multiple packs in an HVESS. If there is only one pack in the system, the HVESS parameters should be used. If there are ...";
CM_ SG_ 2364732414 HighestCellTempCellNum "Identifies the location of SPN 16720 (HVESP21 Highest Cell Temperature) within SPN 16802 (HVESP21 Highest Cell Temperature Module Number).
This parameter is for one of multiple packs in an HVESS. If there is only one pack in the system, the HVESS ...";
CM_ SG_ 2364732414 HighestCellTempModuleNum "Identifies the location of the module containing SPN 16720 (HVESP21 Highest Cell Temperature).
This parameter is for one of multiple packs in an HVESS. If there is only one pack in the system, the HVESS parameters should be used. If there are ...";
CM_ BO_ 2364732158 "High Voltage Energy Storage Pack 21 Data 8
Data set 8 (electrical data) for High Voltage Energy Storage Pack 21.";
CM_ SG_ 2364732158 AvgCellV "The average cell voltage in this High Voltage Energy Storage Pack instance.
This parameter is for one of multiple packs in an HVESS.  If there is only one pack in the system, the HVESS parameters should be used. If there are multiple packs in the ...";
CM_ SG_ 2364732158 LowestCellVCellNum "Identifies the location of SPN 16718 (HVESP21 Lowest Cell Voltage) within SPN 16799 (HVESP21 Lowest Cell Voltage Module Number).
This parameter is for one of multiple packs in an HVESS. If there is only one pack in the system, the HVESS parameters ...";
CM_ SG_ 2364732158 LowestCellVModuleNum "Identifies the location of the module containing SPN 16718 (HVESP21 Lowest Cell Voltage).
This parameter is for one of multiple packs in an HVESS. If there is only one pack in the system, the HVESS parameters should be used. If there are multiple ...";
CM_ SG_ 2364732158 HighestCellVCellNum "Identifies the location of SPN 16717 (HVESP21 Highest Cell Voltage) within SPN 16797 (HVESP21 Highest Cell Voltage Module Number).
This parameter is for one of multiple packs in an HVESS. If there is only one pack in the system, the HVESS ...";
CM_ SG_ 2364732158 HighestCellVModuleNum "Identifies the location of the module containing SPN 16717 (HVESP21 Highest Cell Voltage).
This parameter is for one of multiple packs in an HVESS. If there is only one pack in the system, the HVESS parameters should be used. If there are multiple ...";
CM_ BO_ 2364731902 "High Voltage Energy Storage Pack 21 Thermal Management System Status 1
Collection of data the High Voltage Energy Storage Pack 21 Thermal Management System sends to the Hybrid Controller.";
CM_ SG_ 2364731902 TMSCoolantLvl "Indicates the coolant level in this HVES Thermal Management System (TMS).
This parameter is for one of multiple packs in an HVESS.  If there is only one pack in the system, the HVESS parameters should be used. If there are multiple packs in the ...";
CM_ SG_ 2364731902 TMSMode "Indicates the operating mode of the Thermal Management System.  The heat transfer medium may be (e.g. liquid or air).  The cooling system may be fans, liquid coolant, or a combination of mediums.  The system may include an air and/or liquid ...";
CM_ SG_ 2364731902 TMSHVILStatus "In multiple HVES configurations, this is the status of the High Voltage Interlock Loop from the viewpoint of this Thermal Management System.
00b = HVIL Closed
01b = HVIL Open
10b = Error
11b = Not Available
This parameter is for one of multiple ...";
CM_ SG_ 2364731902 TMSHtrStatus "The state of this High Voltage Energy Storage Pack heater
This parameter is for one of multiple packs in an HVESS.  If there is only one pack in the system, the HVESS parameters should be used. If there are multiple packs in the system, then both ...";
CM_ SG_ 2364731902 TMSRelHumidty "When this High Voltage Energy Storage Pack Thermal Management System is equipped with a relative humidity sensor, this is the  measured Relative Humidity.
This parameter is for one of multiple packs in an HVESS.  If there is only one pack in the ...";
CM_ SG_ 2364731902 TMSCompressorSpd "When this High Voltage Energy Storage Pack Thermal Management System is equipped with an active cooling system (e.g. air conditioner), this is the Compressor Speed.
This parameter is for one of multiple packs in an HVESS.  If there is only one pack ...";
CM_ SG_ 2364731902 TMSHVInputPwr "This is the high-voltage power consumed by this HVES Thermal Management System (TMS).
This parameter is for one of multiple packs in an HVESS.  If there is only one pack in the system, the HVESS parameters should be used. If there are multiple ...";
CM_ SG_ 2364731902 TMSSLIInputPwr "This is the low-voltage power consumed by this HVES Thermal Management System (TMS).
This parameter is for one of multiple packs in an HVESS.  If there is only one pack in the system, the HVESS parameters should be used.  If there are multiple ...";
CM_ BO_ 2364731646 "High Voltage Energy Storage Pack 21 Module Status 1
Module Status message 1 for High Voltage Energy Storage Pack 21.";
CM_ SG_ 2364731646 Module32OperationalStatus "Operational Status of Module 32 in this High Voltage Energy Storage Pack Instance.  Not Operational is used when the module is initializing or not able to function (e.g. internal module level monitors have failed).  Operational indicates that the ...";
CM_ SG_ 2364731646 Module31OperationalStatus "Operational Status of Module 31 in this High Voltage Energy Storage Pack Instance.  Not Operational is used when the module is initializing or not able to function (e.g. internal module level monitors have failed).  Operational indicates that the ...";
CM_ SG_ 2364731646 Module30OperationalStatus "Operational Status of Module 30 in this High Voltage Energy Storage Pack Instance.  Not Operational is used when the module is initializing or not able to function (e.g. internal module level monitors have failed).  Operational indicates that the ...";
CM_ SG_ 2364731646 Module29OperationalStatus "Operational Status of Module 29 in this High Voltage Energy Storage Pack Instance.  Not Operational is used when the module is initializing or not able to function (e.g. internal module level monitors have failed).  Operational indicates that the ...";
CM_ SG_ 2364731646 Module28OperationalStatus "Operational Status of Module 28 in this High Voltage Energy Storage Pack Instance.  Not Operational is used when the module is initializing or not able to function (e.g. internal module level monitors have failed).  Operational indicates that the ...";
CM_ SG_ 2364731646 Module27OperationalStatus "Operational Status of Module 27 in this High Voltage Energy Storage Pack Instance.  Not Operational is used when the module is initializing or not able to function (e.g. internal module level monitors have failed).  Operational indicates that the ...";
CM_ SG_ 2364731646 Module26OperationalStatus "Operational Status of Module 26 in this High Voltage Energy Storage Pack Instance.  Not Operational is used when the module is initializing or not able to function (e.g. internal module level monitors have failed).  Operational indicates that the ...";
CM_ SG_ 2364731646 Module25OperationalStatus "Operational Status of Module 25 in this High Voltage Energy Storage Pack Instance.  Not Operational is used when the module is initializing or not able to function (e.g. internal module level monitors have failed).  Operational indicates that the ...";
CM_ SG_ 2364731646 Module24OperationalStatus "Operational Status of Module 24 in this High Voltage Energy Storage Pack Instance.  Not Operational is used when the module is initializing or not able to function (e.g. internal module level monitors have failed).  Operational indicates that the ...";
CM_ SG_ 2364731646 Module23OperationalStatus "Operational Status of Module 23 in this High Voltage Energy Storage Pack Instance.  Not Operational is used when the module is initializing or not able to function (e.g. internal module level monitors have failed).  Operational indicates that the ...";
CM_ SG_ 2364731646 Module22OperationalStatus "Operational Status of Module 22 in this High Voltage Energy Storage Pack Instance.  Not Operational is used when the module is initializing or not able to function (e.g. internal module level monitors have failed).  Operational indicates that the ...";
CM_ SG_ 2364731646 Module21OperationalStatus "Operational Status of Module 21 in this High Voltage Energy Storage Pack Instance.  Not Operational is used when the module is initializing or not able to function (e.g. internal module level monitors have failed).  Operational indicates that the ...";
CM_ SG_ 2364731646 Module20OperationalStatus "Operational Status of Module 20 in this High Voltage Energy Storage Pack Instance.  Not Operational is used when the module is initializing or not able to function (e.g. internal module level monitors have failed).  Operational indicates that the ...";
CM_ SG_ 2364731646 Module19OperationalStatus "Operational Status of Module 19 in this High Voltage Energy Storage Pack Instance.  Not Operational is used when the module is initializing or not able to function (e.g. internal module level monitors have failed).  Operational indicates that the ...";
CM_ SG_ 2364731646 Module18OperationalStatus "Operational Status of Module 18 in this High Voltage Energy Storage Pack Instance.  Not Operational is used when the module is initializing or not able to function (e.g. internal module level monitors have failed).  Operational indicates that the ...";
CM_ SG_ 2364731646 Module17OperationalStatus "Operational Status of Module 17 in this High Voltage Energy Storage Pack Instance.  Not Operational is used when the module is initializing or not able to function (e.g. internal module level monitors have failed).  Operational indicates that the ...";
CM_ SG_ 2364731646 Module16OperationalStatus "Operational Status of Module 16 in this High Voltage Energy Storage Pack Instance.  Not Operational is used when the module is initializing or not able to function (e.g. internal module level monitors have failed).  Operational indicates that the ...";
CM_ SG_ 2364731646 Module15OperationalStatus "Operational Status of Module 15 in this High Voltage Energy Storage Pack Instance.  Not Operational is used when the module is initializing or not able to function (e.g. internal module level monitors have failed).  Operational indicates that the ...";
CM_ SG_ 2364731646 Module14OperationalStatus "Operational Status of Module 14 in this High Voltage Energy Storage Pack Instance.  Not Operational is used when the module is initializing or not able to function (e.g. internal module level monitors have failed).  Operational indicates that the ...";
CM_ SG_ 2364731646 Module13OperationalStatus "Operational Status of Module 13 in this High Voltage Energy Storage Pack Instance.  Not Operational is used when the module is initializing or not able to function (e.g. internal module level monitors have failed).  Operational indicates that the ...";
CM_ SG_ 2364731646 Module12OperationalStatus "Operational Status of Module 12 in this High Voltage Energy Storage Pack Instance.  Not Operational is used when the module is initializing or not able to function (e.g. internal module level monitors have failed).  Operational indicates that the ...";
CM_ SG_ 2364731646 Module11OperationalStatus "Operational Status of Module 11 in this High Voltage Energy Storage Pack Instance.  Not Operational is used when the module is initializing or not able to function (e.g. internal module level monitors have failed).  Operational indicates that the ...";
CM_ SG_ 2364731646 Module10OperationalStatus "Operational Status of Module 10 in this High Voltage Energy Storage Pack Instance.  Not Operational is used when the module is initializing or not able to function (e.g. internal module level monitors have failed).  Operational indicates that the ...";
CM_ SG_ 2364731646 Module9OperationalStatus "Operational Status of Module 9 in this High Voltage Energy Storage Pack Instance.  Not Operational is used when the module is initializing or not able to function (e.g. internal module level monitors have failed).  Operational indicates that the ...";
CM_ SG_ 2364731646 Module8OperationalStatus "Operational Status of Module 8 in this High Voltage Energy Storage Pack Instance.  Not Operational is used when the module is initializing or not able to function (e.g. internal module level monitors have failed).  Operational indicates that the ...";
CM_ SG_ 2364731646 Module7OperationalStatus "Operational Status of Module 7 in this High Voltage Energy Storage Pack Instance.  Not Operational is used when the module is initializing or not able to function (e.g. internal module level monitors have failed).  Operational indicates that the ...";
CM_ SG_ 2364731646 Module6OperationalStatus "Operational Status of Module 6 in this High Voltage Energy Storage Pack Instance.  Not Operational is used when the module is initializing or not able to function (e.g. internal module level monitors have failed).  Operational indicates that the ...";
CM_ SG_ 2364731646 Module5OperationalStatus "Operational Status of Module 5 in this High Voltage Energy Storage Pack Instance.  Not Operational is used when the module is initializing or not able to function (e.g. internal module level monitors have failed).  Operational indicates that the ...";
CM_ SG_ 2364731646 Module4OperationalStatus "Operational Status of Module 4 in this High Voltage Energy Storage Pack Instance.  Not Operational is used when the module is initializing or not able to function (e.g. internal module level monitors have failed).  Operational indicates that the ...";
CM_ SG_ 2364731646 Module3OperationalStatus "Operational Status of Module 3 in this High Voltage Energy Storage Pack Instance.  Not Operational is used when the module is initializing or not able to function (e.g. internal module level monitors have failed).  Operational indicates that the ...";
CM_ SG_ 2364731646 Module2OperationalStatus "Operational Status of Module 2 in this High Voltage Energy Storage Pack Instance.  Not Operational is used when the module is initializing or not able to function (e.g. internal module level monitors have failed).  Operational indicates that the ...";
CM_ SG_ 2364731646 Module1OperationalStatus "Operational Status of Module 1 in this High Voltage Energy Storage Pack Instance.  Not Operational is used when the module is initializing or not able to function (e.g. internal module level monitors have failed).  Operational indicates that the ...";
CM_ BO_ 2364731390 "High Voltage Energy Storage Pack 21 Data 7
Data set 7 (electrical) for High Voltage Energy Storage Pack 21.";
CM_ SG_ 2364731390 MaxChargeVLmt "The maximum voltage level not to be exceeded while charging this High Voltage Energy Storage Pack instance. If this parameter is not supported, the maximum charge voltage should be limited to SPN 16823 (HVESP21 Recommended Maximum Operating ...";
CM_ SG_ 2364731390 ChargeEnergyCapacity "The amount of unused electrical energy storage available to be filled by charging this High Voltage Energy Storage Pack instance, i.e. “how much empty space is remaining in the tank”. See SPN 16725 (HVESP21 Charge Capacity) for Ampere-hours (Ah).
 ...";
CM_ SG_ 2364731390 DisEnergyCapacity "The amount of stored electrical energy in this High Voltage Energy Storage Pack instance that is available for use by the hybrid system, i.e. “how full is the tank”. See SPN 16724 (HVESP21 Discharge Capacity) for Ampere-hours (Ah).
This parameter ...";
CM_ BO_ 2364731134 "High Voltage Energy Storage Pack 21 Status 1
Status data set 1 for High Voltage Energy Storage Pack 21.";
CM_ SG_ 2364731134 Status1CRC "The CRC is defined as follows:
• Length: 8 bits
• Polynomial: x^8+x^5+x^3+x^2+x+1
• Initial Value: FFh
• Input Data Reflection: Not reflected
• Result Data Reflection: Not reflected
• XOR value: FFh
SAE makes no claim of the functional safety ...";
CM_ SG_ 2364731134 Status1Counter "The message counter is used to detect situations where the transmitting ECU malfunction repeats the same frame all the time. The receiver of the information may use the counter parameter to detect this situation. The transmitting device will ...";
CM_ SG_ 2364731134 OperationalStatus "Provides feedback on where this High Voltage Energy Storage Pack instance is in its operating spectrum, and includes feedback in response to the Operation Consent [i.e. SPN 16695 (HVESP21 Operation Consent)] and Power Down Command [i.e. SPN 16690 ...";
CM_ SG_ 2364731134 HVBusConnectionStatus "This parameter provides high level feedback on this High Voltage Energy Storage Pack instance high voltage bus connection. For specific contactor information, see SPN 16737 (HVESP21 High-Voltage Bus (Positive) Contactor State), SPN 16738 (HVESP21 ...";
CM_ SG_ 2364731134 InternalChargerStatus "Indicates that the charger in this HVES instance is on.  External chargers may use the External Energy Source Connection Status (SPN 7898) and related SPs.
This parameter is for one of multiple packs in an HVESS. If there is only one pack in the ...";
CM_ SG_ 2364731134 CellBalancingActive "Indicates whether or not the cells in this High Voltage Energy Storage Pack instance are currently being balanced.
This parameter is for one of multiple packs in an HVESS.  If there is only one pack in the system, the HVESS parameters should be ...";
CM_ SG_ 2364731134 CellBalanceStatus "Indicates whether or not the cells in this High Voltage Energy Storage Pack instance are balanced.
This parameter is for one of multiple packs in an HVESS.  If there is only one pack in the system, the HVESS parameters should be used. If there are ...";
CM_ SG_ 2364731134 StOfChargeStatus "Status of this High Voltage Energy Storage Pack instance State of Charge (SOC).  Note:  A given HVES controller may not support all of the states.
This parameter is for one of multiple packs in an HVESS.  If there is only one pack in the system, ...";
CM_ SG_ 2364731134 InertiaSwStatus "Switch indicating that an impact has been sensed by this High Voltage Energy Storage Pack instance. The impact indication may require action by another controller, or by this HVES instance itself.  For example, a controller may elect to take this ...";
CM_ SG_ 2364731134 HVILStatus "Status of the High Voltage Interlock Loop from the viewpoint of this High Voltage Energy Storage Pack instance.
This parameter is for one of multiple packs in an HVESS. If there is only one pack in the system, the HVESS parameters should be used ...";
CM_ SG_ 2364731134 HVBusPassiveIsolTestStatus "Status of the high-voltage bus electrical passive isolation test as performed by this High Voltage Energy Storage Pack instance.
This parameter is for one of multiple packs in an HVESS. If there is only one pack in the system, the HVESS parameters ...";
CM_ SG_ 2364731134 HVBusActiveIsolTestStatus "Status of the high-voltage bus electrical active isolation test as performed by this High Voltage Energy Storage Pack instance.
This parameter is for one of multiple packs in an HVESS. If there is only one pack in the system, the HVESS parameters ...";
CM_ SG_ 2364731134 CenterOfPackContactorSt "Position of the center high-voltage contactor. When this contactor is closed, the positive half of this High Voltage Energy Storage Pack instance is connected to the negative half. If a system controls the positive, negative, and center contactors ...";
CM_ SG_ 2364731134 HVBusPreChargeRelaySt "Position of the high-voltage bus contactor pre-charge relay.  When this relay is closed, this High Voltage Energy Storage Pack instance is bringing the high-voltage bus up to its operating level.
This parameter is for one of multiple packs in an ...";
CM_ SG_ 2364731134 HVBusDisconnectForewarning "Indicates that this High Voltage Energy Storage Pack instance is about to disconnect from the high voltage bus due to unacceptable conditions.
This parameter is for one of multiple packs in an HVESS. If there is only one pack in the system, the ...";
CM_ SG_ 2364731134 HVBusContactorSt16738 "Position of this High Voltage Energy Storage Pack instance negative side bus contactor. When this contactor is closed, the negative side of this HVES instance is connected to the negative side of the high-voltage bus. If a system controls the ...";
CM_ SG_ 2364731134 HVBusContactorSt "Position of this High Voltage Energy Storage Pack instance positive side bus contactor.  When this contactor is closed, the positive side of this HVES instance is connected to the positive side of the high-voltage bus.  In systems where all ...";
CM_ BO_ 2364730878 "High Voltage Energy Storage Pack 21 Data 6
Data set 6 (external or interface data) for High Voltage Energy Storage Pack 21.";
CM_ SG_ 2364730878 Temp "The temperature of this High Voltage Energy Storage Pack instance. The value may be determined from a unique sensor specifically for this purpose, or by aggregating various temperature sensor readings within the pack.
This parameter is for one of ...";
CM_ SG_ 2364730878 ETemp "The temperature of the electronics or control modules in this High Voltage Energy Storage Pack instance.  If there are multiple temperature sensors then this parameter would be set to the maximum sensor reading.
This parameter is for one of ...";
CM_ SG_ 2364730878 OutCoolantTemp "The temperature of liquid coolant as it exits this High Voltage Energy Storage Pack instance.
This parameter is for one of multiple packs in an HVESS.  If there is only one pack in the system, the HVESS parameters should be used. If there are ...";
CM_ SG_ 2364730878 InCoolantTemp "The temperature of liquid coolant as it enters this High Voltage Energy Storage Pack instance.
This parameter is for one of multiple packs in an HVESS.  If there is only one pack in the system, the HVESS parameters should be used. If there are ...";
CM_ SG_ 2364730878 IgntV "The voltage level at the ignition input of this High Voltage Energy Storage Pack controller.
This parameter is for one of multiple packs in an HVESS.  If there is only one pack in the system, the HVESS parameters should be used.  If there are ...";
CM_ SG_ 2364730878 BusV "The voltage level of the high voltage bus, as measured by this High Voltage Energy Storage Pack instance on the bus side (not the battery side) of its contactors.
This parameter is for one of multiple packs in an HVESS.  If there is only one pack ...";
CM_ BO_ 2364730622 "High Voltage Energy Storage Pack 21 Data 5
Data set 5 (electrical data) for High Voltage Energy Storage Pack 21.";
CM_ SG_ 2364730622 HighestCellStOfCharge "Indicates the state of charge of the highest-charged cell in this High Voltage Energy Storage Pack instance. 0% means no charge remaining, 100% means the cell is fully charged. If a single state of charge value covers more than one cell, the value ...";
CM_ SG_ 2364730622 LowestCellStOfCharge "Indicates the state of charge of the lowest-charged cell in this High Voltage Energy Storage Pack instance. 0% means no charge remaining, 100% means the cell is fully charged. If a single state of charge value covers more than one cell, the value in ...";
CM_ SG_ 2364730622 ChargeCurLmt "The maximum instantaneous current flow limit into this High Voltage Energy Storage Pack instance. This parameter is defined from the high voltage energy storage pack's point of view and should reflect the instantaneous capability of the pack.  The ...";
CM_ SG_ 2364730622 DisCurLmt "The maximum instantaneous current flow limit out of this High Voltage Energy Storage Pack instance. This parameter is defined from the high voltage energy storage pack's point of view and should reflect the instantaneous capability of the pack.  The ...";
CM_ BO_ 2364730366 "High Voltage Energy Storage Pack 21 Data 4
Data set 4 (electrical data) for High Voltage Energy Storage Pack 21.";
CM_ SG_ 2364730366 CellBalancingCount "The number of cells that are currently being balanced in this High Voltage Energy Storage Pack instance.
This parameter is for one of multiple packs in an HVESS.  If there is only one pack in the system, the HVESS parameters should be used.  If ...";
CM_ SG_ 2364730366 ChargeCapacity "The amount of unused electrical charge storage in this High Voltage Energy Storage Pack instance that is available to be filled by charging, i.e. “how much empty space is remaining in the tank”. See SPN 16755 (HVESP21 Charge Energy Capacity) for ...";
CM_ SG_ 2364730366 DisCapacity "The amount of stored electrical charge in this High Voltage Energy Storage Pack instance that is available for use by the hybrid system, i.e. “how full is the tank”. See SPN 16754 (HVESP21 Discharge Energy Capacity) for kilowatt-hours (kWh).
This ...";
CM_ BO_ 2364730110 "High Voltage Energy Storage Pack 21 Data 3
Data set 3 (thermal data) for High Voltage Energy Storage Pack 21.";
CM_ SG_ 2364730110 CellTempDiffStatus "Indicates whether or not the differential between the highest and lowest cell temperatures are within acceptable limits per this High Voltage Energy Storage Pack instance. The actual temperature differential can be calculated by subtracting SPN ...";
CM_ SG_ 2364730110 AvgCellTemp "The average temperature level of all cells in this High Voltage Energy Storage Pack instance.
This parameter is for one of multiple packs in an HVESS.  If there is only one pack in the system, the HVESS parameters should be used.  If there are ...";
CM_ SG_ 2364730110 LowestCellTemp "The lowest temperature level reported by any cell in this High Voltage Energy Storage Pack instance. If a single temperature sensor covers more than one cell, the value in this parameter is for the smallest group of cells measured. See SPN 16804 ...";
CM_ SG_ 2364730110 HighestCellTemp "The highest temperature level reported by any cell in this High Voltage Energy Storage Pack instance. If a single temperature sensor covers more than one cell, the value in this parameter is for the smallest group of cells measured. See SPN 16802 ...";
CM_ BO_ 2364729854 "High Voltage Energy Storage Pack 21 Data 2
Data set 2 (electrical data) for High Voltage Energy Storage Pack 21.";
CM_ SG_ 2364729854 CellVDiffStatus "Indicates whether or not the differential between the highest and lowest cell voltages are within acceptable limits, according to this High Voltage Energy Storage Pack instance. The actual voltage differential can be calculated by subtracting SPN ...";
CM_ SG_ 2364729854 LowestCellV "The lowest voltage level reported by any cell in this High Voltage Energy Storage Pack instance. If a single voltage sensor covers more than one cell, the value in this parameter is for the smallest group of cells measured. See SPN 16799 (HVESP21 ...";
CM_ SG_ 2364729854 HighestCellV "The highest voltage level reported by any cell in this High Voltage Energy Storage Pack instance. If a single voltage sensor covers more than one cell, the value in this parameter is for the smallest group of cells measured. See SPN 16797 (HVESP21 ...";
CM_ SG_ 2364729854 FastUpdateStOfCharge "Indicates this High Voltage Energy Storage Pack instance state of charge. 0% means no charge remaining, 100% means the system is fully charged in terms of physical limits of this energy storage pack instance. Acceptable state of charge upper and ...";
CM_ BO_ 2364729598 "High Voltage Energy Storage Pack 21 Data 1
Data set 1 (electrical data) for High Voltage Energy Storage Pack 21.";
CM_ SG_ 2364729598 Cur "The current in or out of this High Voltage Energy Storage Pack instance. This parameter should be synchronized with SPN 16714 (HVESP21 Voltage Level) such that a realized power value can be calculated. This parameter is defined from the high voltage ...";
CM_ SG_ 2364729598 Lvl "The voltage level of this High Voltage Energy Storage Pack instance. This parameter should be synchronized with SPN 16715 (HVESP21 Current) such that a realized power value can be calculated. If the HVES component physically contains the contactors ...";
CM_ SG_ 2364729598 AvailableChargePwr "The rate at which this High Voltage Energy Storage Pack instance can currently receive energy from a regenerative or recharging system.
This parameter is for one of multiple packs in an HVESS.  If there is only one pack in the system, the HVESS ...";
CM_ SG_ 2364729598 AvailableDisPwr "The rate at which this High Voltage Energy Storage Pack instance can currently provide energy for propulsion or other uses.
This parameter is for one of multiple packs in an HVESS.  If there is only one pack in the system, the HVESS parameters ...";
CM_ BO_ 2364729342 "High Voltage Energy Storage Pack 21 Status 2
Status data set 2 for High Voltage Energy Storage Pack 21.";
CM_ SG_ 2364729342 ChargePLDueToAnUndefinedCause "Indicates whether or not charge power of this HVES instance is being limited due to an undefined cause.
This parameter is for one of multiple packs in an HVESS.  If there is only one pack in the system, the HVESS parameters should be used. If there ...";
CM_ SG_ 2364729342 ChargePLDueToBatCur "Indicates whether or not charge power of this HVES instance is being limited due to battery current.
This parameter is for one of multiple packs in an HVESS.  If there is only one pack in the system, the HVESS parameters should be used. If there ...";
CM_ SG_ 2364729342 ChargePLDueToBatOrCellV "Indicates whether or not charge power of this HVES instance is being limited due to a battery or cell voltage level.
This parameter is for one of multiple packs in an HVESS.  If there is only one pack in the system, the HVESS parameters should be ...";
CM_ SG_ 2364729342 ChargePLDueToBatDiagCondition "Indicates whether or not charge power of this HVES instance is being limited due to a battery diagnostic condition.
This parameter is for one of multiple packs in an HVESS.  If there is only one pack in the system, the HVESS parameters should be ...";
CM_ SG_ 2364729342 ChargePLDueToBatTemp "Indicates whether or not charge power of this HVES instance is being limited due to battery temperature.
This parameter is for one of multiple packs in an HVESS.  If there is only one pack in the system, the HVESS parameters should be used. If ...";
CM_ SG_ 2364729342 ChargePLDueToStOfCharge "Indicates whether or not charge power of this HVES instance is being limited due to state of charge.
This parameter is for one of multiple packs in an HVESS.  If there is only one pack in the system, the HVESS parameters should be used. If there ...";
CM_ SG_ 2364729342 DisPLDueToAnUndefinedCause "Indicates whether or not discharge power of this HVES instance is being limited due to an undefined cause.
This parameter is for one of multiple packs in an HVESS.  If there is only one pack in the system, the HVESS parameters should be used. If ...";
CM_ SG_ 2364729342 DisPLDueToBatCur "Indicates whether or not discharge power of this HVES instance is being limited due to battery current.
This parameter is for one of multiple packs in an HVESS.  If there is only one pack in the system, the HVESS parameters should be used. If there ...";
CM_ SG_ 2364729342 DisPLDueToBatOrCellV "Indicates whether or not discharge power of this HVES instance is being limited due to a battery or cell voltage level.
This parameter is for one of multiple packs in an HVESS.  If there is only one pack in the system, the HVESS parameters should ...";
CM_ SG_ 2364729342 DisPLDueToBatDiagCondition "Indicates whether or not discharge power of this HVES instance is being limited due to a battery diagnostic condition.
This parameter is for one of multiple packs in an HVESS.  If there is only one pack in the system, the HVESS parameters should be ...";
CM_ SG_ 2364729342 DisPLDueToBatTemp "Indicates whether or not discharge power of this HVES instance is being limited due to battery temperature.
This parameter is for one of multiple packs in an HVESS.  If there is only one pack in the system, the HVESS parameters should be used. If ...";
CM_ SG_ 2364729342 DisPLDueToStOfCharge "Indicates whether or not discharge power of this HVES instance is being limited due to state of charge.
This parameter is for one of multiple packs in an HVESS.  If there is only one pack in the system, the HVESS parameters should be used. If there ...";
CM_ BO_ 2364729086 "High Voltage Energy Storage Pack 20 Data 11
Data set 11 (electrical data) for High Voltage Energy Storage Pack 20.";
CM_ SG_ 2364729086 ActualChargeRate "This signal represents the actual present charge rate of this High Voltage Energy Storage Pack instance.
This parameter is for one of multiple packs in an HVESS. If there is only one pack in the system, the HVESS parameters should be used. If there ...";
CM_ SG_ 2364729086 LvlNegToChassisGroundV "Voltage difference between the most negative terminal of the HVES battery and chassis measured at the battery side of any HVES contained output contactor.  This voltage may be used for system level monitoring of battery shorts to chassis within the ...";
CM_ SG_ 2364729086 BusVNegToChassisGroundV "Voltage difference between the most negative terminal of the HVES battery and chassis measured on the hybrid system bus side (not the battery side) of any HVES contained output contactor.  This voltage may be used for system level monitoring of ...";
CM_ BO_ 2364728830 "High Voltage Energy Storage Pack 20 Data 10
Data set 10 (electrical) for High Voltage Energy Storage Pack 20.";
CM_ SG_ 2364728830 HVBusPassiveIsolTestResults "The isolation resistance expressed in Ohms per Volt that resulted from the High-Voltage Bus Passive Isolation Test.
See SPN 16601 (HVESP20 High-Voltage Bus Passive Isolation Test Status) for test status and SPN 16550 (HVESP20 High-Voltage Bus ...";
CM_ SG_ 2364728830 HVBusActiveIsolTestResults "The isolation resistance expressed in Ohms per Volt that resulted from the High-Voltage Bus Active Isolation Test.
See SPN 16600 (HVESP20 High-Voltage Bus Active Isolation Test Status) for test status and SPN 16549 (HVESP20 High-Voltage Bus Active ...";
CM_ SG_ 2364728830 LowestCellStOfChargeCellNum "Identifies the location of SPN 16587 (HVESP20 Lowest Cell State of Charge) within SPN 16666 (HVESP20 Lowest Cell State of Charge Module Number).
This parameter is for one of multiple packs in an HVESS. If there is only one pack in the system, the ...";
CM_ SG_ 2364728830 LowestCellStOfChargeModuleNum "Identifies the location of the module containing SPN 16587 (HVESP20 Lowest Cell State of Charge).
This parameter is for one of multiple packs in an HVESS. If there is only one pack in the system, the HVESS parameters should be used. If there are ...";
CM_ SG_ 2364728830 HighestCellStOfChargeCellNum "Identifies the location of SPN 16588 (HVESP20 Highest Cell State of Charge) within SPN 16664 (HVESP20 Highest Cell State of Charge Module Number).
This parameter is for one of multiple packs in an HVESS. If there is only one pack in the system, the ...";
CM_ SG_ 2364728830 HighestCellStOfChargeModuleNum "Identifies the location of the module containing SPN 16588 (HVESP20 Highest Cell State of Charge).
This parameter is for one of multiple packs in an HVESS. If there is only one pack in the system, the HVESS parameters should be used. If there are ...";
CM_ BO_ 2364728574 "High Voltage Energy Storage Pack 20 Data 9
Data set 9 (thermal) for High Voltage Energy Storage Pack 20.";
CM_ SG_ 2364728574 Data9CRC "The CRC is defined as follows:
• Length: 8 bits
• Polynomial: x^8+x^5+x^3+x^2+x+1
• Initial Value: FFh
• Input Data Reflection: Not reflected
• Result Data Reflection: Not reflected
• XOR value: FFh
SAE makes no claim of the functional safety ...";
CM_ SG_ 2364728574 Data9Counter "The message counter is used to detect situations where the transmitting ECU malfunction repeats the same frame all the time. The receiver of the information may use the counter parameter to detect this situation. The transmitting device will ...";
CM_ SG_ 2364728574 Data9EmbeddedIntegritySupport "Indicates SPN 23033 (HVESP20 Data 9 CRC) and SPN 23032 (HVESP20 Data 9 Counter) are supported by the sender.
00b = Embedded CRC and Counter are supported by the sender
01b = Protection is supported using J1939-76 SHM
10b = Reserved
11b = CRC and ...";
CM_ SG_ 2364728574 HVESS20ThermalEventDetected "A sensor has detected the presence of a thermal event at or near High Voltage Energy Storage Pack instance.
00b = No Thermal Event Detected
01b = Thermal Event Detected
10b = Error
11b = Not available
This parameter is for one of multiple packs ...";
CM_ SG_ 2364728574 LowestCellTempCellNum "Identifies the location of SPN 16579 (HVESP20 Lowest Cell Temperature) within SPN 16662 (HVESP20 Lowest Cell Temperature Module Number).
This parameter is for one of multiple packs in an HVESS. If there is only one pack in the system, the HVESS ...";
CM_ SG_ 2364728574 LowestCellTempModuleNum "Identifies the location of the module containing SPN 16579 (HVESP20 Lowest Cell Temperature).
This parameter is for one of multiple packs in an HVESS. If there is only one pack in the system, the HVESS parameters should be used. If there are ...";
CM_ SG_ 2364728574 HighestCellTempCellNum "Identifies the location of SPN 16578 (HVESP20 Highest Cell Temperature) within SPN 16660 (HVESP20 Highest Cell Temperature Module Number).
This parameter is for one of multiple packs in an HVESS. If there is only one pack in the system, the HVESS ...";
CM_ SG_ 2364728574 HighestCellTempModuleNum "Identifies the location of the module containing SPN 16578 (HVESP20 Highest Cell Temperature).
This parameter is for one of multiple packs in an HVESS. If there is only one pack in the system, the HVESS parameters should be used. If there are ...";
CM_ BO_ 2364728318 "High Voltage Energy Storage Pack 20 Data 8
Data set 8 (electrical data) for High Voltage Energy Storage Pack 20.";
CM_ SG_ 2364728318 AvgCellV "The average cell voltage in this High Voltage Energy Storage Pack instance.
This parameter is for one of multiple packs in an HVESS.  If there is only one pack in the system, the HVESS parameters should be used. If there are multiple packs in the ...";
CM_ SG_ 2364728318 LowestCellVCellNum "Identifies the location of SPN 16576 (HVESP20 Lowest Cell Voltage) within SPN 16657 (HVESP20 Lowest Cell Voltage Module Number).
This parameter is for one of multiple packs in an HVESS. If there is only one pack in the system, the HVESS parameters ...";
CM_ SG_ 2364728318 LowestCellVModuleNum "Identifies the location of the module containing SPN 16576 (HVESP20 Lowest Cell Voltage).
This parameter is for one of multiple packs in an HVESS. If there is only one pack in the system, the HVESS parameters should be used. If there are multiple ...";
CM_ SG_ 2364728318 HighestCellVCellNum "Identifies the location of SPN 16575 (HVESP20 Highest Cell Voltage) within SPN 16655 (HVESP20 Highest Cell Voltage Module Number).
This parameter is for one of multiple packs in an HVESS. If there is only one pack in the system, the HVESS ...";
CM_ SG_ 2364728318 HighestCellVModuleNum "Identifies the location of the module containing SPN 16575 (HVESP20 Highest Cell Voltage).
This parameter is for one of multiple packs in an HVESS. If there is only one pack in the system, the HVESS parameters should be used. If there are multiple ...";
CM_ BO_ 2364728062 "High Voltage Energy Storage Pack 20 Thermal Management System Status 1
Collection of data the High Voltage Energy Storage Pack 20 Thermal Management System sends to the Hybrid Controller.";
CM_ SG_ 2364728062 TMSCoolantLvl "Indicates the coolant level in this HVES Thermal Management System (TMS).
This parameter is for one of multiple packs in an HVESS.  If there is only one pack in the system, the HVESS parameters should be used. If there are multiple packs in the ...";
CM_ SG_ 2364728062 TMSMode "Indicates the operating mode of the Thermal Management System.  The heat transfer medium may be (e.g. liquid or air).  The cooling system may be fans, liquid coolant, or a combination of mediums.  The system may include an air and/or liquid ...";
CM_ SG_ 2364728062 TMSHVILStatus "In multiple HVES configurations, this is the status of the High Voltage Interlock Loop from the viewpoint of this Thermal Management System.
00b = HVIL Closed
01b = HVIL Open
10b = Error
11b = Not Available
This parameter is for one of multiple ...";
CM_ SG_ 2364728062 TMSHtrStatus "The state of this High Voltage Energy Storage Pack heater
This parameter is for one of multiple packs in an HVESS.  If there is only one pack in the system, the HVESS parameters should be used. If there are multiple packs in the system, then both ...";
CM_ SG_ 2364728062 TMSRelHumidty "When this High Voltage Energy Storage Pack Thermal Management System is equipped with a relative humidity sensor, this is the  measured Relative Humidity.
This parameter is for one of multiple packs in an HVESS.  If there is only one pack in the ...";
CM_ SG_ 2364728062 TMSCompressorSpd "When this High Voltage Energy Storage Pack Thermal Management System is equipped with an active cooling system (e.g. air conditioner), this is the Compressor Speed.
This parameter is for one of multiple packs in an HVESS.  If there is only one pack ...";
CM_ SG_ 2364728062 TMSHVInputPwr "This is the high-voltage power consumed by this HVES Thermal Management System (TMS).
This parameter is for one of multiple packs in an HVESS.  If there is only one pack in the system, the HVESS parameters should be used. If there are multiple ...";
CM_ SG_ 2364728062 TMSSLIInputPwr "This is the low-voltage power consumed by this HVES Thermal Management System (TMS).
This parameter is for one of multiple packs in an HVESS.  If there is only one pack in the system, the HVESS parameters should be used.  If there are multiple ...";
CM_ BO_ 2364727806 "High Voltage Energy Storage Pack 20 Module Status 1
Module Status message 1 for High Voltage Energy Storage Pack 20.";
CM_ SG_ 2364727806 Module32OperationalStatus "Operational Status of Module 32 in this High Voltage Energy Storage Pack Instance.  Not Operational is used when the module is initializing or not able to function (e.g. internal module level monitors have failed).  Operational indicates that the ...";
CM_ SG_ 2364727806 Module31OperationalStatus "Operational Status of Module 31 in this High Voltage Energy Storage Pack Instance.  Not Operational is used when the module is initializing or not able to function (e.g. internal module level monitors have failed).  Operational indicates that the ...";
CM_ SG_ 2364727806 Module30OperationalStatus "Operational Status of Module 30 in this High Voltage Energy Storage Pack Instance.  Not Operational is used when the module is initializing or not able to function (e.g. internal module level monitors have failed).  Operational indicates that the ...";
CM_ SG_ 2364727806 Module29OperationalStatus "Operational Status of Module 29 in this High Voltage Energy Storage Pack Instance.  Not Operational is used when the module is initializing or not able to function (e.g. internal module level monitors have failed).  Operational indicates that the ...";
CM_ SG_ 2364727806 Module28OperationalStatus "Operational Status of Module 28 in this High Voltage Energy Storage Pack Instance.  Not Operational is used when the module is initializing or not able to function (e.g. internal module level monitors have failed).  Operational indicates that the ...";
CM_ SG_ 2364727806 Module27OperationalStatus "Operational Status of Module 27 in this High Voltage Energy Storage Pack Instance.  Not Operational is used when the module is initializing or not able to function (e.g. internal module level monitors have failed).  Operational indicates that the ...";
CM_ SG_ 2364727806 Module26OperationalStatus "Operational Status of Module 26 in this High Voltage Energy Storage Pack Instance.  Not Operational is used when the module is initializing or not able to function (e.g. internal module level monitors have failed).  Operational indicates that the ...";
CM_ SG_ 2364727806 Module25OperationalStatus "Operational Status of Module 25 in this High Voltage Energy Storage Pack Instance.  Not Operational is used when the module is initializing or not able to function (e.g. internal module level monitors have failed).  Operational indicates that the ...";
CM_ SG_ 2364727806 Module24OperationalStatus "Operational Status of Module 24 in this High Voltage Energy Storage Pack Instance.  Not Operational is used when the module is initializing or not able to function (e.g. internal module level monitors have failed).  Operational indicates that the ...";
CM_ SG_ 2364727806 Module23OperationalStatus "Operational Status of Module 23 in this High Voltage Energy Storage Pack Instance.  Not Operational is used when the module is initializing or not able to function (e.g. internal module level monitors have failed).  Operational indicates that the ...";
CM_ SG_ 2364727806 Module22OperationalStatus "Operational Status of Module 22 in this High Voltage Energy Storage Pack Instance.  Not Operational is used when the module is initializing or not able to function (e.g. internal module level monitors have failed).  Operational indicates that the ...";
CM_ SG_ 2364727806 Module21OperationalStatus "Operational Status of Module 21 in this High Voltage Energy Storage Pack Instance.  Not Operational is used when the module is initializing or not able to function (e.g. internal module level monitors have failed).  Operational indicates that the ...";
CM_ SG_ 2364727806 Module20OperationalStatus "Operational Status of Module 20 in this High Voltage Energy Storage Pack Instance.  Not Operational is used when the module is initializing or not able to function (e.g. internal module level monitors have failed).  Operational indicates that the ...";
CM_ SG_ 2364727806 Module19OperationalStatus "Operational Status of Module 19 in this High Voltage Energy Storage Pack Instance.  Not Operational is used when the module is initializing or not able to function (e.g. internal module level monitors have failed).  Operational indicates that the ...";
CM_ SG_ 2364727806 Module18OperationalStatus "Operational Status of Module 18 in this High Voltage Energy Storage Pack Instance.  Not Operational is used when the module is initializing or not able to function (e.g. internal module level monitors have failed).  Operational indicates that the ...";
CM_ SG_ 2364727806 Module17OperationalStatus "Operational Status of Module 17 in this High Voltage Energy Storage Pack Instance.  Not Operational is used when the module is initializing or not able to function (e.g. internal module level monitors have failed).  Operational indicates that the ...";
CM_ SG_ 2364727806 Module16OperationalStatus "Operational Status of Module 16 in this High Voltage Energy Storage Pack Instance.  Not Operational is used when the module is initializing or not able to function (e.g. internal module level monitors have failed).  Operational indicates that the ...";
CM_ SG_ 2364727806 Module15OperationalStatus "Operational Status of Module 15 in this High Voltage Energy Storage Pack Instance.  Not Operational is used when the module is initializing or not able to function (e.g. internal module level monitors have failed).  Operational indicates that the ...";
CM_ SG_ 2364727806 Module14OperationalStatus "Operational Status of Module 14 in this High Voltage Energy Storage Pack Instance.  Not Operational is used when the module is initializing or not able to function (e.g. internal module level monitors have failed).  Operational indicates that the ...";
CM_ SG_ 2364727806 Module13OperationalStatus "Operational Status of Module 13 in this High Voltage Energy Storage Pack Instance.  Not Operational is used when the module is initializing or not able to function (e.g. internal module level monitors have failed).  Operational indicates that the ...";
CM_ SG_ 2364727806 Module12OperationalStatus "Operational Status of Module 12 in this High Voltage Energy Storage Pack Instance.  Not Operational is used when the module is initializing or not able to function (e.g. internal module level monitors have failed).  Operational indicates that the ...";
CM_ SG_ 2364727806 Module11OperationalStatus "Operational Status of Module 11 in this High Voltage Energy Storage Pack Instance.  Not Operational is used when the module is initializing or not able to function (e.g. internal module level monitors have failed).  Operational indicates that the ...";
CM_ SG_ 2364727806 Module10OperationalStatus "Operational Status of Module 10 in this High Voltage Energy Storage Pack Instance.  Not Operational is used when the module is initializing or not able to function (e.g. internal module level monitors have failed).  Operational indicates that the ...";
CM_ SG_ 2364727806 Module9OperationalStatus "Operational Status of Module 9 in this High Voltage Energy Storage Pack Instance.  Not Operational is used when the module is initializing or not able to function (e.g. internal module level monitors have failed).  Operational indicates that the ...";
CM_ SG_ 2364727806 Module8OperationalStatus "Operational Status of Module 8 in this High Voltage Energy Storage Pack Instance.  Not Operational is used when the module is initializing or not able to function (e.g. internal module level monitors have failed).  Operational indicates that the ...";
CM_ SG_ 2364727806 Module7OperationalStatus "Operational Status of Module 7 in this High Voltage Energy Storage Pack Instance.  Not Operational is used when the module is initializing or not able to function (e.g. internal module level monitors have failed).  Operational indicates that the ...";
CM_ SG_ 2364727806 Module6OperationalStatus "Operational Status of Module 6 in this High Voltage Energy Storage Pack Instance.  Not Operational is used when the module is initializing or not able to function (e.g. internal module level monitors have failed).  Operational indicates that the ...";
CM_ SG_ 2364727806 Module5OperationalStatus "Operational Status of Module 5 in this High Voltage Energy Storage Pack Instance.  Not Operational is used when the module is initializing or not able to function (e.g. internal module level monitors have failed).  Operational indicates that the ...";
CM_ SG_ 2364727806 Module4OperationalStatus "Operational Status of Module 4 in this High Voltage Energy Storage Pack Instance.  Not Operational is used when the module is initializing or not able to function (e.g. internal module level monitors have failed).  Operational indicates that the ...";
CM_ SG_ 2364727806 Module3OperationalStatus "Operational Status of Module 3 in this High Voltage Energy Storage Pack Instance.  Not Operational is used when the module is initializing or not able to function (e.g. internal module level monitors have failed).  Operational indicates that the ...";
CM_ SG_ 2364727806 Module2OperationalStatus "Operational Status of Module 2 in this High Voltage Energy Storage Pack Instance.  Not Operational is used when the module is initializing or not able to function (e.g. internal module level monitors have failed).  Operational indicates that the ...";
CM_ SG_ 2364727806 Module1OperationalStatus "Operational Status of Module 1 in this High Voltage Energy Storage Pack Instance.  Not Operational is used when the module is initializing or not able to function (e.g. internal module level monitors have failed).  Operational indicates that the ...";
CM_ BO_ 2364727550 "High Voltage Energy Storage Pack 20 Data 7
Data set 7 (electrical) for High Voltage Energy Storage Pack 20.";
CM_ SG_ 2364727550 MaxChargeVLmt "The maximum voltage level not to be exceeded while charging this High Voltage Energy Storage Pack instance. If this parameter is not supported, the maximum charge voltage should be limited to SPN 16681 (HVESP20 Recommended Maximum Operating ...";
CM_ SG_ 2364727550 ChargeEnergyCapacity "The amount of unused electrical energy storage available to be filled by charging this High Voltage Energy Storage Pack instance, i.e. “how much empty space is remaining in the tank”. See SPN 16583 (HVESP20 Charge Capacity) for Ampere-hours (Ah).
 ...";
CM_ SG_ 2364727550 DisEnergyCapacity "The amount of stored electrical energy in this High Voltage Energy Storage Pack instance that is available for use by the hybrid system, i.e. “how full is the tank”. See SPN 16582 (HVESP20 Discharge Capacity) for Ampere-hours (Ah).
This parameter ...";
CM_ BO_ 2364727294 "High Voltage Energy Storage Pack 20 Status 1
Status data set 1 for High Voltage Energy Storage Pack 20.";
CM_ SG_ 2364727294 Status1CRC "The CRC is defined as follows:
• Length: 8 bits
• Polynomial: x^8+x^5+x^3+x^2+x+1
• Initial Value: FFh
• Input Data Reflection: Not reflected
• Result Data Reflection: Not reflected
• XOR value: FFh
SAE makes no claim of the functional safety ...";
CM_ SG_ 2364727294 Status1Counter "The message counter is used to detect situations where the transmitting ECU malfunction repeats the same frame all the time. The receiver of the information may use the counter parameter to detect this situation. The transmitting device will ...";
CM_ SG_ 2364727294 OperationalStatus "Provides feedback on where this High Voltage Energy Storage Pack instance is in its operating spectrum, and includes feedback in response to the Operation Consent [i.e. SPN 16553 (HVESP20 Operation Consent)] and Power Down Command [i.e. SPN 16548 ...";
CM_ SG_ 2364727294 HVBusConnectionStatus "This parameter provides high level feedback on this High Voltage Energy Storage Pack instance high voltage bus connection. For specific contactor information, see SPN 16595 (HVESP20 High-Voltage Bus (Positive) Contactor State), SPN 16596 (HVESP20 ...";
CM_ SG_ 2364727294 InternalChargerStatus "Indicates that the charger in this HVES instance is on.  External chargers may use the External Energy Source Connection Status (SPN 7898) and related SPs.
This parameter is for one of multiple packs in an HVESS. If there is only one pack in the ...";
CM_ SG_ 2364727294 CellBalancingActive "Indicates whether or not the cells in this High Voltage Energy Storage Pack instance are currently being balanced.
This parameter is for one of multiple packs in an HVESS.  If there is only one pack in the system, the HVESS parameters should be ...";
CM_ SG_ 2364727294 CellBalanceStatus "Indicates whether or not the cells in this High Voltage Energy Storage Pack instance are balanced.
This parameter is for one of multiple packs in an HVESS.  If there is only one pack in the system, the HVESS parameters should be used. If there are ...";
CM_ SG_ 2364727294 StOfChargeStatus "Status of this High Voltage Energy Storage Pack instance State of Charge (SOC).  Note:  A given HVES controller may not support all of the states.
This parameter is for one of multiple packs in an HVESS.  If there is only one pack in the system, ...";
CM_ SG_ 2364727294 InertiaSwStatus "Switch indicating that an impact has been sensed by this High Voltage Energy Storage Pack instance. The impact indication may require action by another controller, or by this HVES instance itself.  For example, a controller may elect to take this ...";
CM_ SG_ 2364727294 HVILStatus "Status of the High Voltage Interlock Loop from the viewpoint of this High Voltage Energy Storage Pack instance.
This parameter is for one of multiple packs in an HVESS. If there is only one pack in the system, the HVESS parameters should be used ...";
CM_ SG_ 2364727294 HVBusPassiveIsolTestStatus "Status of the high-voltage bus electrical passive isolation test as performed by this High Voltage Energy Storage Pack instance.
This parameter is for one of multiple packs in an HVESS. If there is only one pack in the system, the HVESS parameters ...";
CM_ SG_ 2364727294 HVBusActiveIsolTestStatus "Status of the high-voltage bus electrical active isolation test as performed by this High Voltage Energy Storage Pack instance.
This parameter is for one of multiple packs in an HVESS. If there is only one pack in the system, the HVESS parameters ...";
CM_ SG_ 2364727294 CenterOfPackContactorSt "Position of the center high-voltage contactor. When this contactor is closed, the positive half of this High Voltage Energy Storage Pack instance is connected to the negative half. If a system controls the positive, negative, and center contactors ...";
CM_ SG_ 2364727294 HVBusPreChargeRelaySt "Position of the high-voltage bus contactor pre-charge relay.  When this relay is closed, this High Voltage Energy Storage Pack instance is bringing the high-voltage bus up to its operating level.
This parameter is for one of multiple packs in an ...";
CM_ SG_ 2364727294 HVBusDisconnectForewarning "Indicates that this High Voltage Energy Storage Pack instance is about to disconnect from the high voltage bus due to unacceptable conditions.
This parameter is for one of multiple packs in an HVESS. If there is only one pack in the system, the ...";
CM_ SG_ 2364727294 HVBusContactorSt16596 "Position of this High Voltage Energy Storage Pack instance negative side bus contactor. When this contactor is closed, the negative side of this HVES instance is connected to the negative side of the high-voltage bus. If a system controls the ...";
CM_ SG_ 2364727294 HVBusContactorSt "Position of this High Voltage Energy Storage Pack instance positive side bus contactor.  When this contactor is closed, the positive side of this HVES instance is connected to the positive side of the high-voltage bus.  In systems where all ...";
CM_ BO_ 2364727038 "High Voltage Energy Storage Pack 20 Data 6
Data set 6 (external or interface data) for High Voltage Energy Storage Pack 20.";
CM_ SG_ 2364727038 Temp "The temperature of this High Voltage Energy Storage Pack instance. The value may be determined from a unique sensor specifically for this purpose, or by aggregating various temperature sensor readings within the pack.
This parameter is for one of ...";
CM_ SG_ 2364727038 ETemp "The temperature of the electronics or control modules in this High Voltage Energy Storage Pack instance.  If there are multiple temperature sensors then this parameter would be set to the maximum sensor reading.
This parameter is for one of ...";
CM_ SG_ 2364727038 OutCoolantTemp "The temperature of liquid coolant as it exits this High Voltage Energy Storage Pack instance.
This parameter is for one of multiple packs in an HVESS.  If there is only one pack in the system, the HVESS parameters should be used. If there are ...";
CM_ SG_ 2364727038 InCoolantTemp "The temperature of liquid coolant as it enters this High Voltage Energy Storage Pack instance.
This parameter is for one of multiple packs in an HVESS.  If there is only one pack in the system, the HVESS parameters should be used. If there are ...";
CM_ SG_ 2364727038 IgntV "The voltage level at the ignition input of this High Voltage Energy Storage Pack controller.
This parameter is for one of multiple packs in an HVESS.  If there is only one pack in the system, the HVESS parameters should be used.  If there are ...";
CM_ SG_ 2364727038 BusV "The voltage level of the high voltage bus, as measured by this High Voltage Energy Storage Pack instance on the bus side (not the battery side) of its contactors.
This parameter is for one of multiple packs in an HVESS.  If there is only one pack ...";
CM_ BO_ 2364726782 "High Voltage Energy Storage Pack 20 Data 5
Data set 5 (electrical data) for High Voltage Energy Storage Pack 20.";
CM_ SG_ 2364726782 HighestCellStOfCharge "Indicates the state of charge of the highest-charged cell in this High Voltage Energy Storage Pack instance. 0% means no charge remaining, 100% means the cell is fully charged. If a single state of charge value covers more than one cell, the value ...";
CM_ SG_ 2364726782 LowestCellStOfCharge "Indicates the state of charge of the lowest-charged cell in this High Voltage Energy Storage Pack instance. 0% means no charge remaining, 100% means the cell is fully charged. If a single state of charge value covers more than one cell, the value in ...";
CM_ SG_ 2364726782 ChargeCurLmt "The maximum instantaneous current flow limit into this High Voltage Energy Storage Pack instance. This parameter is defined from the high voltage energy storage pack's point of view and should reflect the instantaneous capability of the pack.  The ...";
CM_ SG_ 2364726782 DisCurLmt "The maximum instantaneous current flow limit out of this High Voltage Energy Storage Pack instance. This parameter is defined from the high voltage energy storage pack's point of view and should reflect the instantaneous capability of the pack.  The ...";
CM_ BO_ 2364726526 "High Voltage Energy Storage Pack 20 Data 4
Data set 4 (electrical data) for High Voltage Energy Storage Pack 20.";
CM_ SG_ 2364726526 CellBalancingCount "The number of cells that are currently being balanced in this High Voltage Energy Storage Pack instance.
This parameter is for one of multiple packs in an HVESS.  If there is only one pack in the system, the HVESS parameters should be used.  If ...";
CM_ SG_ 2364726526 ChargeCapacity "The amount of unused electrical charge storage in this High Voltage Energy Storage Pack instance that is available to be filled by charging, i.e. “how much empty space is remaining in the tank”. See SPN 16613 (HVESP20 Charge Energy Capacity) for ...";
CM_ SG_ 2364726526 DisCapacity "The amount of stored electrical charge in this High Voltage Energy Storage Pack instance that is available for use by the hybrid system, i.e. “how full is the tank”. See SPN 16612 (HVESP20 Discharge Energy Capacity) for kilowatt-hours (kWh).
This ...";
CM_ BO_ 2364726270 "High Voltage Energy Storage Pack 20 Data 3
Data set 3 (thermal data) for High Voltage Energy Storage Pack 20.";
CM_ SG_ 2364726270 CellTempDiffStatus "Indicates whether or not the differential between the highest and lowest cell temperatures are within acceptable limits per this High Voltage Energy Storage Pack instance. The actual temperature differential can be calculated by subtracting SPN ...";
CM_ SG_ 2364726270 AvgCellTemp "The average temperature level of all cells in this High Voltage Energy Storage Pack instance.
This parameter is for one of multiple packs in an HVESS.  If there is only one pack in the system, the HVESS parameters should be used.  If there are ...";
CM_ SG_ 2364726270 LowestCellTemp "The lowest temperature level reported by any cell in this High Voltage Energy Storage Pack instance. If a single temperature sensor covers more than one cell, the value in this parameter is for the smallest group of cells measured. See SPN 16662 ...";
CM_ SG_ 2364726270 HighestCellTemp "The highest temperature level reported by any cell in this High Voltage Energy Storage Pack instance. If a single temperature sensor covers more than one cell, the value in this parameter is for the smallest group of cells measured. See SPN 16660 ...";
CM_ BO_ 2364726014 "High Voltage Energy Storage Pack 20 Data 2
Data set 2 (electrical data) for High Voltage Energy Storage Pack 20.";
CM_ SG_ 2364726014 CellVDiffStatus "Indicates whether or not the differential between the highest and lowest cell voltages are within acceptable limits, according to this High Voltage Energy Storage Pack instance. The actual voltage differential can be calculated by subtracting SPN ...";
CM_ SG_ 2364726014 LowestCellV "The lowest voltage level reported by any cell in this High Voltage Energy Storage Pack instance. If a single voltage sensor covers more than one cell, the value in this parameter is for the smallest group of cells measured. See SPN 16657 (HVESP20 ...";
CM_ SG_ 2364726014 HighestCellV "The highest voltage level reported by any cell in this High Voltage Energy Storage Pack instance. If a single voltage sensor covers more than one cell, the value in this parameter is for the smallest group of cells measured. See SPN 16655 (HVESP20 ...";
CM_ SG_ 2364726014 FastUpdateStOfCharge "Indicates this High Voltage Energy Storage Pack instance state of charge. 0% means no charge remaining, 100% means the system is fully charged in terms of physical limits of this energy storage pack instance. Acceptable state of charge upper and ...";
CM_ BO_ 2364725758 "High Voltage Energy Storage Pack 20 Data 1
Data set 1 (electrical data) for High Voltage Energy Storage Pack 20.";
CM_ SG_ 2364725758 Cur "The current in or out of this High Voltage Energy Storage Pack instance. This parameter should be synchronized with SPN 16572 (HVESP20 Voltage Level) such that a realized power value can be calculated. This parameter is defined from the high voltage ...";
CM_ SG_ 2364725758 Lvl "The voltage level of this High Voltage Energy Storage Pack instance. This parameter should be synchronized with SPN 16573 (HVESP20 Current) such that a realized power value can be calculated. If the HVES component physically contains the contactors ...";
CM_ SG_ 2364725758 AvailableChargePwr "The rate at which this High Voltage Energy Storage Pack instance can currently receive energy from a regenerative or recharging system.
This parameter is for one of multiple packs in an HVESS.  If there is only one pack in the system, the HVESS ...";
CM_ SG_ 2364725758 AvailableDisPwr "The rate at which this High Voltage Energy Storage Pack instance can currently provide energy for propulsion or other uses.
This parameter is for one of multiple packs in an HVESS.  If there is only one pack in the system, the HVESS parameters ...";
CM_ BO_ 2364725502 "High Voltage Energy Storage Pack 20 Status 2
Status data set 2 for High Voltage Energy Storage Pack 20.";
CM_ SG_ 2364725502 ChargePLDueToAnUndefinedCause "Indicates whether or not charge power of this HVES instance is being limited due to an undefined cause.
This parameter is for one of multiple packs in an HVESS.  If there is only one pack in the system, the HVESS parameters should be used. If there ...";
CM_ SG_ 2364725502 ChargePLDueToBatCur "Indicates whether or not charge power of this HVES instance is being limited due to battery current.
This parameter is for one of multiple packs in an HVESS.  If there is only one pack in the system, the HVESS parameters should be used. If there ...";
CM_ SG_ 2364725502 ChargePLDueToBatOrCellV "Indicates whether or not charge power of this HVES instance is being limited due to a battery or cell voltage level.
This parameter is for one of multiple packs in an HVESS.  If there is only one pack in the system, the HVESS parameters should be ...";
CM_ SG_ 2364725502 ChargePLDueToBatDiagCondition "Indicates whether or not charge power of this HVES instance is being limited due to a battery diagnostic condition.
This parameter is for one of multiple packs in an HVESS.  If there is only one pack in the system, the HVESS parameters should be ...";
CM_ SG_ 2364725502 ChargePLDueToBatTemp "Indicates whether or not charge power of this HVES instance is being limited due to battery temperature.
This parameter is for one of multiple packs in an HVESS.  If there is only one pack in the system, the HVESS parameters should be used. If ...";
CM_ SG_ 2364725502 ChargePLDueToStOfCharge "Indicates whether or not charge power of this HVES instance is being limited due to state of charge.
This parameter is for one of multiple packs in an HVESS.  If there is only one pack in the system, the HVESS parameters should be used. If there ...";
CM_ SG_ 2364725502 DisPLDueToAnUndefinedCause "Indicates whether or not discharge power of this HVES instance is being limited due to an undefined cause.
This parameter is for one of multiple packs in an HVESS.  If there is only one pack in the system, the HVESS parameters should be used. If ...";
CM_ SG_ 2364725502 DisPLDueToBatCur "Indicates whether or not discharge power of this HVES instance is being limited due to battery current.
This parameter is for one of multiple packs in an HVESS.  If there is only one pack in the system, the HVESS parameters should be used. If there ...";
CM_ SG_ 2364725502 DisPLDueToBatOrCellV "Indicates whether or not discharge power of this HVES instance is being limited due to a battery or cell voltage level.
This parameter is for one of multiple packs in an HVESS.  If there is only one pack in the system, the HVESS parameters should ...";
CM_ SG_ 2364725502 DisPLDueToBatDiagCondition "Indicates whether or not discharge power of this HVES instance is being limited due to a battery diagnostic condition.
This parameter is for one of multiple packs in an HVESS.  If there is only one pack in the system, the HVESS parameters should be ...";
CM_ SG_ 2364725502 DisPLDueToBatTemp "Indicates whether or not discharge power of this HVES instance is being limited due to battery temperature.
This parameter is for one of multiple packs in an HVESS.  If there is only one pack in the system, the HVESS parameters should be used. If ...";
CM_ SG_ 2364725502 DisPLDueToStOfCharge "Indicates whether or not discharge power of this HVES instance is being limited due to state of charge.
This parameter is for one of multiple packs in an HVESS.  If there is only one pack in the system, the HVESS parameters should be used. If there ...";
CM_ BO_ 2364725246 "High Voltage Energy Storage Pack 19 Data 11
Data set 11 (electrical data) for High Voltage Energy Storage Pack 19.";
CM_ SG_ 2364725246 ActualChargeRate "This signal represents the actual present charge rate of this High Voltage Energy Storage Pack instance.
This parameter is for one of multiple packs in an HVESS. If there is only one pack in the system, the HVESS parameters should be used. If there ...";
CM_ SG_ 2364725246 LvlNegToChassisGroundV "Voltage difference between the most negative terminal of the HVES battery and chassis measured at the battery side of any HVES contained output contactor.  This voltage may be used for system level monitoring of battery shorts to chassis within the ...";
CM_ SG_ 2364725246 BusVNegToChassisGroundV "Voltage difference between the most negative terminal of the HVES battery and chassis measured on the hybrid system bus side (not the battery side) of any HVES contained output contactor.  This voltage may be used for system level monitoring of ...";
CM_ BO_ 2364724990 "High Voltage Energy Storage Pack 19 Data 10
Data set 10 (electrical) for High Voltage Energy Storage Pack 19.";
CM_ SG_ 2364724990 HVBusPassiveIsolTestResults "The isolation resistance expressed in Ohms per Volt that resulted from the High-Voltage Bus Passive Isolation Test.
See SPN 16459 (HVESP19 High-Voltage Bus Passive Isolation Test Status) for test status and SPN 16408 (HVESP19 High-Voltage Bus ...";
CM_ SG_ 2364724990 HVBusActiveIsolTestResults "The isolation resistance expressed in Ohms per Volt that resulted from the High-Voltage Bus Active Isolation Test.
See SPN 16458 (HVESP19 High-Voltage Bus Active Isolation Test Status) for test status and SPN 16407 (HVESP19 High-Voltage Bus Active ...";
CM_ SG_ 2364724990 LowestCellStOfChargeCellNum "Identifies the location of SPN 16445 (HVESP19 Lowest Cell State of Charge) within SPN 16524 (HVESP19 Lowest Cell State of Charge Module Number).
This parameter is for one of multiple packs in an HVESS. If there is only one pack in the system, the ...";
CM_ SG_ 2364724990 LowestCellStOfChargeModuleNum "Identifies the location of the module containing SPN 16445 (HVESP19 Lowest Cell State of Charge).
This parameter is for one of multiple packs in an HVESS. If there is only one pack in the system, the HVESS parameters should be used. If there are ...";
CM_ SG_ 2364724990 HighestCellStOfChargeCellNum "Identifies the location of SPN 16446 (HVESP19 Highest Cell State of Charge) within SPN 16522 (HVESP19 Highest Cell State of Charge Module Number).
This parameter is for one of multiple packs in an HVESS. If there is only one pack in the system, the ...";
CM_ SG_ 2364724990 HighestCellStOfChargeModuleNum "Identifies the location of the module containing SPN 16446 (HVESP19 Highest Cell State of Charge).
This parameter is for one of multiple packs in an HVESS. If there is only one pack in the system, the HVESS parameters should be used. If there are ...";
CM_ BO_ 2364724734 "High Voltage Energy Storage Pack 19 Data 9
Data set 9 (thermal) for High Voltage Energy Storage Pack 19.";
CM_ SG_ 2364724734 Data9CRC "The CRC is defined as follows:
• Length: 8 bits
• Polynomial: x^8+x^5+x^3+x^2+x+1
• Initial Value: FFh
• Input Data Reflection: Not reflected
• Result Data Reflection: Not reflected
• XOR value: FFh
SAE makes no claim of the functional safety ...";
CM_ SG_ 2364724734 Data9Counter "The message counter is used to detect situations where the transmitting ECU malfunction repeats the same frame all the time. The receiver of the information may use the counter parameter to detect this situation. The transmitting device will ...";
CM_ SG_ 2364724734 Data9EmbeddedIntegritySupport "Indicates SPN 23030 (HVESP19 Data 9 CRC) and SPN 23029 (HVESP19 Data 9 Counter) are supported by the sender.
00b = Embedded CRC and Counter are supported by the sender
01b = Protection is supported using J1939-76 SHM
10b = Reserved
11b = CRC and ...";
CM_ SG_ 2364724734 HVESS19ThermalEventDetected "A sensor has detected the presence of a thermal event at or near High Voltage Energy Storage Pack instance.
00b = No Thermal Event Detected
01b = Thermal Event Detected
10b = Error
11b = Not available
This parameter is for one of multiple packs ...";
CM_ SG_ 2364724734 LowestCellTempCellNum "Identifies the location of SPN 16437 (HVESP19 Lowest Cell Temperature) within SPN 16520 (HVESP19 Lowest Cell Temperature Module Number).
This parameter is for one of multiple packs in an HVESS. If there is only one pack in the system, the HVESS ...";
CM_ SG_ 2364724734 LowestCellTempModuleNum "Identifies the location of the module containing SPN 16437 (HVESP19 Lowest Cell Temperature).
This parameter is for one of multiple packs in an HVESS. If there is only one pack in the system, the HVESS parameters should be used. If there are ...";
CM_ SG_ 2364724734 HighestCellTempCellNum "Identifies the location of SPN 16436 (HVESP19 Highest Cell Temperature) within SPN 16518 (HVESP19 Highest Cell Temperature Module Number).
This parameter is for one of multiple packs in an HVESS. If there is only one pack in the system, the HVESS ...";
CM_ SG_ 2364724734 HighestCellTempModuleNum "Identifies the location of the module containing SPN 16436 (HVESP19 Highest Cell Temperature).
This parameter is for one of multiple packs in an HVESS. If there is only one pack in the system, the HVESS parameters should be used. If there are ...";
CM_ BO_ 2364724478 "High Voltage Energy Storage Pack 19 Data 8
Data set 8 (electrical data) for High Voltage Energy Storage Pack 19.";
CM_ SG_ 2364724478 AvgCellV "The average cell voltage in this High Voltage Energy Storage Pack instance.
This parameter is for one of multiple packs in an HVESS.  If there is only one pack in the system, the HVESS parameters should be used. If there are multiple packs in the ...";
CM_ SG_ 2364724478 LowestCellVCellNum "Identifies the location of SPN 16434 (HVESP19 Lowest Cell Voltage) within SPN 16515 (HVESP19 Lowest Cell Voltage Module Number).
This parameter is for one of multiple packs in an HVESS. If there is only one pack in the system, the HVESS parameters ...";
CM_ SG_ 2364724478 LowestCellVModuleNum "Identifies the location of the module containing SPN 16434 (HVESP19 Lowest Cell Voltage).
This parameter is for one of multiple packs in an HVESS. If there is only one pack in the system, the HVESS parameters should be used. If there are multiple ...";
CM_ SG_ 2364724478 HighestCellVCellNum "Identifies the location of SPN 16433 (HVESP19 Highest Cell Voltage) within SPN 16513 (HVESP19 Highest Cell Voltage Module Number).
This parameter is for one of multiple packs in an HVESS. If there is only one pack in the system, the HVESS ...";
CM_ SG_ 2364724478 HighestCellVModuleNum "Identifies the location of the module containing SPN 16433 (HVESP19 Highest Cell Voltage).
This parameter is for one of multiple packs in an HVESS. If there is only one pack in the system, the HVESS parameters should be used. If there are multiple ...";
CM_ BO_ 2364724222 "High Voltage Energy Storage Pack 19 Thermal Management System Status 1
Collection of data the High Voltage Energy Storage Pack 19 Thermal Management System sends to the Hybrid Controller.";
CM_ SG_ 2364724222 TMSCoolantLvl "Indicates the coolant level in this HVES Thermal Management System (TMS).
This parameter is for one of multiple packs in an HVESS.  If there is only one pack in the system, the HVESS parameters should be used. If there are multiple packs in the ...";
CM_ SG_ 2364724222 TMSMode "Indicates the operating mode of the Thermal Management System.  The heat transfer medium may be (e.g. liquid or air).  The cooling system may be fans, liquid coolant, or a combination of mediums.  The system may include an air and/or liquid ...";
CM_ SG_ 2364724222 TMSHVILStatus "In multiple HVES configurations, this is the status of the High Voltage Interlock Loop from the viewpoint of this Thermal Management System.
00b = HVIL Closed
01b = HVIL Open
10b = Error
11b = Not Available
This parameter is for one of multiple ...";
CM_ SG_ 2364724222 TMSHtrStatus "The state of this High Voltage Energy Storage Pack heater
This parameter is for one of multiple packs in an HVESS.  If there is only one pack in the system, the HVESS parameters should be used. If there are multiple packs in the system, then both ...";
CM_ SG_ 2364724222 TMSRelHumidty "When this High Voltage Energy Storage Pack Thermal Management System is equipped with a relative humidity sensor, this is the  measured Relative Humidity.
This parameter is for one of multiple packs in an HVESS.  If there is only one pack in the ...";
CM_ SG_ 2364724222 TMSCompressorSpd "When this High Voltage Energy Storage Pack Thermal Management System is equipped with an active cooling system (e.g. air conditioner), this is the Compressor Speed.
This parameter is for one of multiple packs in an HVESS.  If there is only one pack ...";
CM_ SG_ 2364724222 TMSHVInputPwr "This is the high-voltage power consumed by this HVES Thermal Management System (TMS).
This parameter is for one of multiple packs in an HVESS.  If there is only one pack in the system, the HVESS parameters should be used. If there are multiple ...";
CM_ SG_ 2364724222 TMSSLIInputPwr "This is the low-voltage power consumed by this HVES Thermal Management System (TMS).
This parameter is for one of multiple packs in an HVESS.  If there is only one pack in the system, the HVESS parameters should be used.  If there are multiple ...";
CM_ BO_ 2364723966 "High Voltage Energy Storage Pack 19 Module Status 1
Module Status message 1 for High Voltage Energy Storage Pack 19.";
CM_ SG_ 2364723966 Module32OperationalStatus "Operational Status of Module 32 in this High Voltage Energy Storage Pack Instance.  Not Operational is used when the module is initializing or not able to function (e.g. internal module level monitors have failed).  Operational indicates that the ...";
CM_ SG_ 2364723966 Module31OperationalStatus "Operational Status of Module 31 in this High Voltage Energy Storage Pack Instance.  Not Operational is used when the module is initializing or not able to function (e.g. internal module level monitors have failed).  Operational indicates that the ...";
CM_ SG_ 2364723966 Module30OperationalStatus "Operational Status of Module 30 in this High Voltage Energy Storage Pack Instance.  Not Operational is used when the module is initializing or not able to function (e.g. internal module level monitors have failed).  Operational indicates that the ...";
CM_ SG_ 2364723966 Module29OperationalStatus "Operational Status of Module 29 in this High Voltage Energy Storage Pack Instance.  Not Operational is used when the module is initializing or not able to function (e.g. internal module level monitors have failed).  Operational indicates that the ...";
CM_ SG_ 2364723966 Module28OperationalStatus "Operational Status of Module 28 in this High Voltage Energy Storage Pack Instance.  Not Operational is used when the module is initializing or not able to function (e.g. internal module level monitors have failed).  Operational indicates that the ...";
CM_ SG_ 2364723966 Module27OperationalStatus "Operational Status of Module 27 in this High Voltage Energy Storage Pack Instance.  Not Operational is used when the module is initializing or not able to function (e.g. internal module level monitors have failed).  Operational indicates that the ...";
CM_ SG_ 2364723966 Module26OperationalStatus "Operational Status of Module 26 in this High Voltage Energy Storage Pack Instance.  Not Operational is used when the module is initializing or not able to function (e.g. internal module level monitors have failed).  Operational indicates that the ...";
CM_ SG_ 2364723966 Module25OperationalStatus "Operational Status of Module 25 in this High Voltage Energy Storage Pack Instance.  Not Operational is used when the module is initializing or not able to function (e.g. internal module level monitors have failed).  Operational indicates that the ...";
CM_ SG_ 2364723966 Module24OperationalStatus "Operational Status of Module 24 in this High Voltage Energy Storage Pack Instance.  Not Operational is used when the module is initializing or not able to function (e.g. internal module level monitors have failed).  Operational indicates that the ...";
CM_ SG_ 2364723966 Module23OperationalStatus "Operational Status of Module 23 in this High Voltage Energy Storage Pack Instance.  Not Operational is used when the module is initializing or not able to function (e.g. internal module level monitors have failed).  Operational indicates that the ...";
CM_ SG_ 2364723966 Module22OperationalStatus "Operational Status of Module 22 in this High Voltage Energy Storage Pack Instance.  Not Operational is used when the module is initializing or not able to function (e.g. internal module level monitors have failed).  Operational indicates that the ...";
CM_ SG_ 2364723966 Module21OperationalStatus "Operational Status of Module 21 in this High Voltage Energy Storage Pack Instance.  Not Operational is used when the module is initializing or not able to function (e.g. internal module level monitors have failed).  Operational indicates that the ...";
CM_ SG_ 2364723966 Module20OperationalStatus "Operational Status of Module 20 in this High Voltage Energy Storage Pack Instance.  Not Operational is used when the module is initializing or not able to function (e.g. internal module level monitors have failed).  Operational indicates that the ...";
CM_ SG_ 2364723966 Module19OperationalStatus "Operational Status of Module 19 in this High Voltage Energy Storage Pack Instance.  Not Operational is used when the module is initializing or not able to function (e.g. internal module level monitors have failed).  Operational indicates that the ...";
CM_ SG_ 2364723966 Module18OperationalStatus "Operational Status of Module 18 in this High Voltage Energy Storage Pack Instance.  Not Operational is used when the module is initializing or not able to function (e.g. internal module level monitors have failed).  Operational indicates that the ...";
CM_ SG_ 2364723966 Module17OperationalStatus "Operational Status of Module 17 in this High Voltage Energy Storage Pack Instance.  Not Operational is used when the module is initializing or not able to function (e.g. internal module level monitors have failed).  Operational indicates that the ...";
CM_ SG_ 2364723966 Module16OperationalStatus "Operational Status of Module 16 in this High Voltage Energy Storage Pack Instance.  Not Operational is used when the module is initializing or not able to function (e.g. internal module level monitors have failed).  Operational indicates that the ...";
CM_ SG_ 2364723966 Module15OperationalStatus "Operational Status of Module 15 in this High Voltage Energy Storage Pack Instance.  Not Operational is used when the module is initializing or not able to function (e.g. internal module level monitors have failed).  Operational indicates that the ...";
CM_ SG_ 2364723966 Module14OperationalStatus "Operational Status of Module 14 in this High Voltage Energy Storage Pack Instance.  Not Operational is used when the module is initializing or not able to function (e.g. internal module level monitors have failed).  Operational indicates that the ...";
CM_ SG_ 2364723966 Module13OperationalStatus "Operational Status of Module 13 in this High Voltage Energy Storage Pack Instance.  Not Operational is used when the module is initializing or not able to function (e.g. internal module level monitors have failed).  Operational indicates that the ...";
CM_ SG_ 2364723966 Module12OperationalStatus "Operational Status of Module 12 in this High Voltage Energy Storage Pack Instance.  Not Operational is used when the module is initializing or not able to function (e.g. internal module level monitors have failed).  Operational indicates that the ...";
CM_ SG_ 2364723966 Module11OperationalStatus "Operational Status of Module 11 in this High Voltage Energy Storage Pack Instance.  Not Operational is used when the module is initializing or not able to function (e.g. internal module level monitors have failed).  Operational indicates that the ...";
CM_ SG_ 2364723966 Module10OperationalStatus "Operational Status of Module 10 in this High Voltage Energy Storage Pack Instance.  Not Operational is used when the module is initializing or not able to function (e.g. internal module level monitors have failed).  Operational indicates that the ...";
CM_ SG_ 2364723966 Module9OperationalStatus "Operational Status of Module 9 in this High Voltage Energy Storage Pack Instance.  Not Operational is used when the module is initializing or not able to function (e.g. internal module level monitors have failed).  Operational indicates that the ...";
CM_ SG_ 2364723966 Module8OperationalStatus "Operational Status of Module 8 in this High Voltage Energy Storage Pack Instance.  Not Operational is used when the module is initializing or not able to function (e.g. internal module level monitors have failed).  Operational indicates that the ...";
CM_ SG_ 2364723966 Module7OperationalStatus "Operational Status of Module 7 in this High Voltage Energy Storage Pack Instance.  Not Operational is used when the module is initializing or not able to function (e.g. internal module level monitors have failed).  Operational indicates that the ...";
CM_ SG_ 2364723966 Module6OperationalStatus "Operational Status of Module 6 in this High Voltage Energy Storage Pack Instance.  Not Operational is used when the module is initializing or not able to function (e.g. internal module level monitors have failed).  Operational indicates that the ...";
CM_ SG_ 2364723966 Module5OperationalStatus "Operational Status of Module 5 in this High Voltage Energy Storage Pack Instance.  Not Operational is used when the module is initializing or not able to function (e.g. internal module level monitors have failed).  Operational indicates that the ...";
CM_ SG_ 2364723966 Module4OperationalStatus "Operational Status of Module 4 in this High Voltage Energy Storage Pack Instance.  Not Operational is used when the module is initializing or not able to function (e.g. internal module level monitors have failed).  Operational indicates that the ...";
CM_ SG_ 2364723966 Module3OperationalStatus "Operational Status of Module 3 in this High Voltage Energy Storage Pack Instance.  Not Operational is used when the module is initializing or not able to function (e.g. internal module level monitors have failed).  Operational indicates that the ...";
CM_ SG_ 2364723966 Module2OperationalStatus "Operational Status of Module 2 in this High Voltage Energy Storage Pack Instance.  Not Operational is used when the module is initializing or not able to function (e.g. internal module level monitors have failed).  Operational indicates that the ...";
CM_ SG_ 2364723966 Module1OperationalStatus "Operational Status of Module 1 in this High Voltage Energy Storage Pack Instance.  Not Operational is used when the module is initializing or not able to function (e.g. internal module level monitors have failed).  Operational indicates that the ...";
CM_ BO_ 2364723710 "High Voltage Energy Storage Pack 19 Data 7
Data set 7 (electrical) for High Voltage Energy Storage Pack 19.";
CM_ SG_ 2364723710 MaxChargeVLmt "The maximum voltage level not to be exceeded while charging this High Voltage Energy Storage Pack instance. If this parameter is not supported, the maximum charge voltage should be limited to SPN 16539 (HVESP19 Recommended Maximum Operating ...";
CM_ SG_ 2364723710 ChargeEnergyCapacity "The amount of unused electrical energy storage available to be filled by charging this High Voltage Energy Storage Pack instance, i.e. “how much empty space is remaining in the tank”. See SPN 16441 (HVESP19 Charge Capacity) for Ampere-hours (Ah).
 ...";
CM_ SG_ 2364723710 DisEnergyCapacity "The amount of stored electrical energy in this High Voltage Energy Storage Pack instance that is available for use by the hybrid system, i.e. “how full is the tank”. See SPN 16440 (HVESP19 Discharge Capacity) for Ampere-hours (Ah).
This parameter ...";
BA_DEF_ SG_  "GenSigInactiveValue" INT 0 0;
BA_DEF_ SG_  "SigType" ENUM  "Default","Range","RangeSigned","ASCII","Discrete","Control","ReferencePGN","DTC","StringDelimiter","StringLength","StringLengthControl","MessageCounter","MessageChecksum";
BA_DEF_ SG_  "GenSigStartValue" INT 0 2147483647;
BA_DEF_ SG_  "GenSigSendType" ENUM  "Cyclic","OnWrite","OnWriteWithRepetition","OnChange","OnChangeWithRepetition","IfActive","IfActiveWithRepetition","NoSigSendType";
BA_DEF_ SG_  "GenSigILSupport" ENUM  "No","Yes";
BA_DEF_ SG_  "SPN" INT 0 524287;
BA_DEF_ BO_  "J1939CPgSendTimeout" INT -1 3600000;
BA_DEF_ BO_  "J1939CPgTOS" INT 0 7;
BA_DEF_ BO_  "J1939PgAppearanceOnBus" ENUM  "Default","CAN_Extended","CANFD_Extended";
BA_DEF_ BO_  "FsJ1939UseCrcAndCounter" STRING ;
BA_DEF_ BO_  "TpJ1939VarDlc" ENUM  "No","Yes";
BA_DEF_ BO_  "GenMsgNrOfRepetition" INT 0 1000000;
BA_DEF_ BO_  "GenMsgCycleTimeFast" INT 0 3600000;
BA_DEF_ BO_  "GenMsgFastOnStart" INT 0 100000;
BA_DEF_ BO_  "GenMsgStartDelayTime" INT 0 100000;
BA_DEF_ BO_  "GenMsgILSupport" ENUM  "No","Yes";
BA_DEF_ BO_  "GenMsgDelayTime" INT 0 1000;
BA_DEF_ BO_  "GenMsgRequestable" INT 0 1;
BA_DEF_ BO_  "GenMsgSendType" ENUM  "cyclic","NotUsed","NotUsed","NotUsed","NotUsed","NotUsed","NotUsed","IfActive","noMsgSendType";
BA_DEF_ BO_  "VFrameFormat" ENUM  "StandardCAN","ExtendedCAN","reserved","J1939PG","reserved","reserved","reserved","reserved","reserved","reserved","reserved","reserved","reserved","reserved","StandardCAN_FD","ExtendedCAN_FD";
BA_DEF_ BO_  "SingleFrame" INT 0 1;
BA_DEF_ BO_  "GenMsgCycleTime" INT 0 3600000;
BA_DEF_ SG_  "SystemSignalLongSymbol" STRING ;
BA_DEF_DEF_  "GenSigInactiveValue" 0;
BA_DEF_DEF_  "SigType" "Default";
BA_DEF_DEF_  "GenSigStartValue" 0;
BA_DEF_DEF_  "GenSigSendType" "NoSigSendType";
BA_DEF_DEF_  "GenSigILSupport" "Yes";
BA_DEF_DEF_  "SPN" 0;
BA_DEF_DEF_  "J1939CPgSendTimeout" -1;
BA_DEF_DEF_  "J1939CPgTOS" 2;
BA_DEF_DEF_  "J1939PgAppearanceOnBus" "Default";
BA_DEF_DEF_  "FsJ1939UseCrcAndCounter" "";
BA_DEF_DEF_  "TpJ1939VarDlc" "No";
BA_DEF_DEF_  "GenMsgNrOfRepetition" 0;
BA_DEF_DEF_  "GenMsgCycleTimeFast" 0;
BA_DEF_DEF_  "GenMsgFastOnStart" 0;
BA_DEF_DEF_  "GenMsgStartDelayTime" 0;
BA_DEF_DEF_  "GenMsgILSupport" "Yes";
BA_DEF_DEF_  "GenMsgDelayTime" 0;
BA_DEF_DEF_  "GenMsgRequestable" 1;
BA_DEF_DEF_  "GenMsgSendType" "noMsgSendType";
BA_DEF_DEF_  "VFrameFormat" "J1939PG";
BA_DEF_DEF_  "SingleFrame" 1;
BA_DEF_DEF_  "GenMsgCycleTime" 0;
BA_DEF_DEF_  "SystemSignalLongSymbol" "";
BA_ "GenMsgSendType" BO_ 2364733438 0;
BA_ "GenMsgCycleTime" BO_ 2364733438 20;
BA_ "GenMsgSendType" BO_ 2364733182 0;
BA_ "GenMsgCycleTime" BO_ 2364733182 100;
BA_ "GenMsgSendType" BO_ 2364732926 0;
BA_ "GenMsgCycleTime" BO_ 2364732926 100;
BA_ "GenMsgSendType" BO_ 2364732670 0;
BA_ "GenMsgCycleTime" BO_ 2364732670 100;
BA_ "FsJ1939UseCrcAndCounter" BO_ 2364732414 "Aa";
BA_ "GenMsgSendType" BO_ 2364732414 0;
BA_ "GenMsgCycleTime" BO_ 2364732414 100;
BA_ "GenMsgSendType" BO_ 2364732158 0;
BA_ "GenMsgCycleTime" BO_ 2364732158 100;
BA_ "GenMsgSendType" BO_ 2364731902 0;
BA_ "GenMsgCycleTime" BO_ 2364731902 100;
BA_ "GenMsgSendType" BO_ 2364731646 0;
BA_ "GenMsgCycleTime" BO_ 2364731646 100;
BA_ "GenMsgSendType" BO_ 2364731390 0;
BA_ "GenMsgCycleTime" BO_ 2364731390 100;
BA_ "FsJ1939UseCrcAndCounter" BO_ 2364731134 "Aa";
BA_ "GenMsgDelayTime" BO_ 2364731134 20;
BA_ "GenMsgSendType" BO_ 2364731134 0;
BA_ "GenMsgCycleTime" BO_ 2364731134 100;
BA_ "GenMsgSendType" BO_ 2364730878 0;
BA_ "GenMsgCycleTime" BO_ 2364730878 100;
BA_ "GenMsgSendType" BO_ 2364730622 0;
BA_ "GenMsgCycleTime" BO_ 2364730622 20;
BA_ "GenMsgSendType" BO_ 2364730366 0;
BA_ "GenMsgCycleTime" BO_ 2364730366 100;
BA_ "GenMsgSendType" BO_ 2364730110 0;
BA_ "GenMsgCycleTime" BO_ 2364730110 20;
BA_ "GenMsgSendType" BO_ 2364729854 0;
BA_ "GenMsgCycleTime" BO_ 2364729854 20;
BA_ "GenMsgSendType" BO_ 2364729598 0;
BA_ "GenMsgCycleTime" BO_ 2364729598 20;
BA_ "GenMsgSendType" BO_ 2364729342 0;
BA_ "GenMsgCycleTime" BO_ 2364729342 100;
BA_ "GenMsgSendType" BO_ 2364729086 0;
BA_ "GenMsgCycleTime" BO_ 2364729086 100;
BA_ "GenMsgSendType" BO_ 2364728830 0;
BA_ "GenMsgCycleTime" BO_ 2364728830 100;
BA_ "FsJ1939UseCrcAndCounter" BO_ 2364728574 "Aa";
BA_ "GenMsgSendType" BO_ 2364728574 0;
BA_ "GenMsgCycleTime" BO_ 2364728574 100;
BA_ "GenMsgSendType" BO_ 2364728318 0;
BA_ "GenMsgCycleTime" BO_ 2364728318 100;
BA_ "GenMsgSendType" BO_ 2364728062 0;
BA_ "GenMsgCycleTime" BO_ 2364728062 100;
BA_ "GenMsgSendType" BO_ 2364727806 0;
BA_ "GenMsgCycleTime" BO_ 2364727806 100;
BA_ "GenMsgSendType" BO_ 2364727550 0;
BA_ "GenMsgCycleTime" BO_ 2364727550 100;
BA_ "FsJ1939UseCrcAndCounter" BO_ 2364727294 "Aa";
BA_ "GenMsgDelayTime" BO_ 2364727294 20;
BA_ "GenMsgSendType" BO_ 2364727294 0;
BA_ "GenMsgCycleTime" BO_ 2364727294 100;
BA_ "GenMsgSendType" BO_ 2364727038 0;
BA_ "GenMsgCycleTime" BO_ 2364727038 100;
BA_ "GenMsgSendType" BO_ 2364726782 0;
BA_ "GenMsgCycleTime" BO_ 2364726782 20;
BA_ "GenMsgSendType" BO_ 2364726526 0;
BA_ "GenMsgCycleTime" BO_ 2364726526 100;
BA_ "GenMsgSendType" BO_ 2364726270 0;
BA_ "GenMsgCycleTime" BO_ 2364726270 20;
BA_ "GenMsgSendType" BO_ 2364726014 0;
BA_ "GenMsgCycleTime" BO_ 2364726014 20;
BA_ "GenMsgSendType" BO_ 2364725758 0;
BA_ "GenMsgCycleTime" BO_ 2364725758 20;
BA_ "GenMsgSendType" BO_ 2364725502 0;
BA_ "GenMsgCycleTime" BO_ 2364725502 100;
BA_ "GenMsgSendType" BO_ 2364725246 0;
BA_ "GenMsgCycleTime" BO_ 2364725246 100;
BA_ "GenMsgSendType" BO_ 2364724990 0;
BA_ "GenMsgCycleTime" BO_ 2364724990 100;
BA_ "FsJ1939UseCrcAndCounter" BO_ 2364724734 "Aa";
BA_ "GenMsgSendType" BO_ 2364724734 0;
BA_ "GenMsgCycleTime" BO_ 2364724734 100;
BA_ "GenMsgSendType" BO_ 2364724478 0;
BA_ "GenMsgCycleTime" BO_ 2364724478 100;
BA_ "GenMsgSendType" BO_ 2364724222 0;
BA_ "GenMsgCycleTime" BO_ 2364724222 100;
BA_ "GenMsgSendType" BO_ 2364723966 0;
BA_ "GenMsgCycleTime" BO_ 2364723966 100;
BA_ "GenMsgSendType" BO_ 2364723710 0;
BA_ "GenMsgCycleTime" BO_ 2364723710 100;
BA_ "SigType" SG_ 2364733438 Cur 1;
BA_ "SPN" SG_ 2364733438 Cur 16857;
BA_ "SigType" SG_ 2364733438 Lvl 1;
BA_ "SPN" SG_ 2364733438 Lvl 16856;
BA_ "SigType" SG_ 2364733438 AvailableChargePwr 1;
BA_ "SPN" SG_ 2364733438 AvailableChargePwr 16855;
BA_ "SigType" SG_ 2364733438 AvailableDisPwr 1;
BA_ "SPN" SG_ 2364733438 AvailableDisPwr 16854;
BA_ "SigType" SG_ 2364733182 ChargePLDueToAnUndefinedCause 4;
BA_ "SPN" SG_ 2364733182 ChargePLDueToAnUndefinedCause 16853;
BA_ "SigType" SG_ 2364733182 ChargePLDueToBatCur 4;
BA_ "SPN" SG_ 2364733182 ChargePLDueToBatCur 16852;
BA_ "SigType" SG_ 2364733182 ChargePLDueToBatOrCellV 4;
BA_ "SPN" SG_ 2364733182 ChargePLDueToBatOrCellV 16851;
BA_ "SigType" SG_ 2364733182 ChargePLDueToBatDiagCondition 4;
BA_ "SPN" SG_ 2364733182 ChargePLDueToBatDiagCondition 16850;
BA_ "SigType" SG_ 2364733182 ChargePLDueToBatTemp 4;
BA_ "SPN" SG_ 2364733182 ChargePLDueToBatTemp 16849;
BA_ "SigType" SG_ 2364733182 ChargePLDueToStOfCharge 4;
BA_ "SPN" SG_ 2364733182 ChargePLDueToStOfCharge 16848;
BA_ "SigType" SG_ 2364733182 DisPLDueToAnUndefinedCause 4;
BA_ "SPN" SG_ 2364733182 DisPLDueToAnUndefinedCause 16847;
BA_ "SigType" SG_ 2364733182 DisPLDueToBatCur 4;
BA_ "SPN" SG_ 2364733182 DisPLDueToBatCur 16846;
BA_ "SigType" SG_ 2364733182 DisPLDueToBatOrCellV 4;
BA_ "SPN" SG_ 2364733182 DisPLDueToBatOrCellV 16845;
BA_ "SigType" SG_ 2364733182 DisPLDueToBatDiagCondition 4;
BA_ "SPN" SG_ 2364733182 DisPLDueToBatDiagCondition 16844;
BA_ "SigType" SG_ 2364733182 DisPLDueToBatTemp 4;
BA_ "SPN" SG_ 2364733182 DisPLDueToBatTemp 16843;
BA_ "SigType" SG_ 2364733182 DisPLDueToStOfCharge 4;
BA_ "SPN" SG_ 2364733182 DisPLDueToStOfCharge 16842;
BA_ "SigType" SG_ 2364732926 ActualChargeRate 1;
BA_ "SPN" SG_ 2364732926 ActualChargeRate 16814;
BA_ "SigType" SG_ 2364732926 LvlNegToChassisGroundV 1;
BA_ "SPN" SG_ 2364732926 LvlNegToChassisGroundV 16813;
BA_ "SigType" SG_ 2364732926 BusVNegToChassisGroundV 1;
BA_ "SPN" SG_ 2364732926 BusVNegToChassisGroundV 16812;
BA_ "SigType" SG_ 2364732670 HVBusPassiveIsolTestResults 1;
BA_ "SPN" SG_ 2364732670 HVBusPassiveIsolTestResults 16811;
BA_ "SigType" SG_ 2364732670 HVBusActiveIsolTestResults 1;
BA_ "SPN" SG_ 2364732670 HVBusActiveIsolTestResults 16810;
BA_ "SigType" SG_ 2364732670 LowestCellStOfChargeCellNum 1;
BA_ "SPN" SG_ 2364732670 LowestCellStOfChargeCellNum 16809;
BA_ "SigType" SG_ 2364732670 LowestCellStOfChargeModuleNum 1;
BA_ "SPN" SG_ 2364732670 LowestCellStOfChargeModuleNum 16808;
BA_ "SigType" SG_ 2364732670 HighestCellStOfChargeCellNum 1;
BA_ "SPN" SG_ 2364732670 HighestCellStOfChargeCellNum 16807;
BA_ "SigType" SG_ 2364732670 HighestCellStOfChargeModuleNum 1;
BA_ "SPN" SG_ 2364732670 HighestCellStOfChargeModuleNum 16806;
BA_ "SigType" SG_ 2364732414 Data9CRC 12;
BA_ "SPN" SG_ 2364732414 Data9CRC 23036;
BA_ "SigType" SG_ 2364732414 Data9Counter 11;
BA_ "SPN" SG_ 2364732414 Data9Counter 23035;
BA_ "SigType" SG_ 2364732414 Data9EmbeddedIntegritySupport 5;
BA_ "SPN" SG_ 2364732414 Data9EmbeddedIntegritySupport 23034;
BA_ "SigType" SG_ 2364732414 HVESS21ThermalEventDetected 4;
BA_ "SPN" SG_ 2364732414 HVESS21ThermalEventDetected 21308;
BA_ "SigType" SG_ 2364732414 LowestCellTempCellNum 1;
BA_ "SPN" SG_ 2364732414 LowestCellTempCellNum 16805;
BA_ "SigType" SG_ 2364732414 LowestCellTempModuleNum 1;
BA_ "SPN" SG_ 2364732414 LowestCellTempModuleNum 16804;
BA_ "SigType" SG_ 2364732414 HighestCellTempCellNum 1;
BA_ "SPN" SG_ 2364732414 HighestCellTempCellNum 16803;
BA_ "SigType" SG_ 2364732414 HighestCellTempModuleNum 1;
BA_ "SPN" SG_ 2364732414 HighestCellTempModuleNum 16802;
BA_ "SigType" SG_ 2364732158 AvgCellV 1;
BA_ "SPN" SG_ 2364732158 AvgCellV 16801;
BA_ "SigType" SG_ 2364732158 LowestCellVCellNum 1;
BA_ "SPN" SG_ 2364732158 LowestCellVCellNum 16800;
BA_ "SigType" SG_ 2364732158 LowestCellVModuleNum 1;
BA_ "SPN" SG_ 2364732158 LowestCellVModuleNum 16799;
BA_ "SigType" SG_ 2364732158 HighestCellVCellNum 1;
BA_ "SPN" SG_ 2364732158 HighestCellVCellNum 16798;
BA_ "SigType" SG_ 2364732158 HighestCellVModuleNum 1;
BA_ "SPN" SG_ 2364732158 HighestCellVModuleNum 16797;
BA_ "SigType" SG_ 2364731902 TMSCoolantLvl 4;
BA_ "SPN" SG_ 2364731902 TMSCoolantLvl 16796;
BA_ "SPN" SG_ 2364731902 TMSMode 16795;
BA_ "SigType" SG_ 2364731902 TMSHVILStatus 4;
BA_ "SPN" SG_ 2364731902 TMSHVILStatus 16794;
BA_ "SigType" SG_ 2364731902 TMSHtrStatus 5;
BA_ "SPN" SG_ 2364731902 TMSHtrStatus 16793;
BA_ "SigType" SG_ 2364731902 TMSRelHumidty 1;
BA_ "SPN" SG_ 2364731902 TMSRelHumidty 16792;
BA_ "SigType" SG_ 2364731902 TMSCompressorSpd 1;
BA_ "SPN" SG_ 2364731902 TMSCompressorSpd 16791;
BA_ "SigType" SG_ 2364731902 TMSHVInputPwr 1;
BA_ "SPN" SG_ 2364731902 TMSHVInputPwr 16790;
BA_ "SigType" SG_ 2364731902 TMSSLIInputPwr 1;
BA_ "SPN" SG_ 2364731902 TMSSLIInputPwr 16789;
BA_ "SigType" SG_ 2364731646 Module32OperationalStatus 5;
BA_ "SPN" SG_ 2364731646 Module32OperationalStatus 16788;
BA_ "SigType" SG_ 2364731646 Module31OperationalStatus 5;
BA_ "SPN" SG_ 2364731646 Module31OperationalStatus 16787;
BA_ "SigType" SG_ 2364731646 Module30OperationalStatus 5;
BA_ "SPN" SG_ 2364731646 Module30OperationalStatus 16786;
BA_ "SigType" SG_ 2364731646 Module29OperationalStatus 5;
BA_ "SPN" SG_ 2364731646 Module29OperationalStatus 16785;
BA_ "SigType" SG_ 2364731646 Module28OperationalStatus 5;
BA_ "SPN" SG_ 2364731646 Module28OperationalStatus 16784;
BA_ "SigType" SG_ 2364731646 Module27OperationalStatus 5;
BA_ "SPN" SG_ 2364731646 Module27OperationalStatus 16783;
BA_ "SigType" SG_ 2364731646 Module26OperationalStatus 5;
BA_ "SPN" SG_ 2364731646 Module26OperationalStatus 16782;
BA_ "SigType" SG_ 2364731646 Module25OperationalStatus 5;
BA_ "SPN" SG_ 2364731646 Module25OperationalStatus 16781;
BA_ "SigType" SG_ 2364731646 Module24OperationalStatus 5;
BA_ "SPN" SG_ 2364731646 Module24OperationalStatus 16780;
BA_ "SigType" SG_ 2364731646 Module23OperationalStatus 5;
BA_ "SPN" SG_ 2364731646 Module23OperationalStatus 16779;
BA_ "SigType" SG_ 2364731646 Module22OperationalStatus 5;
BA_ "SPN" SG_ 2364731646 Module22OperationalStatus 16778;
BA_ "SigType" SG_ 2364731646 Module21OperationalStatus 5;
BA_ "SPN" SG_ 2364731646 Module21OperationalStatus 16777;
BA_ "SigType" SG_ 2364731646 Module20OperationalStatus 5;
BA_ "SPN" SG_ 2364731646 Module20OperationalStatus 16776;
BA_ "SigType" SG_ 2364731646 Module19OperationalStatus 5;
BA_ "SPN" SG_ 2364731646 Module19OperationalStatus 16775;
BA_ "SigType" SG_ 2364731646 Module18OperationalStatus 5;
BA_ "SPN" SG_ 2364731646 Module18OperationalStatus 16774;
BA_ "SigType" SG_ 2364731646 Module17OperationalStatus 5;
BA_ "SPN" SG_ 2364731646 Module17OperationalStatus 16773;
BA_ "SigType" SG_ 2364731646 Module16OperationalStatus 5;
BA_ "SPN" SG_ 2364731646 Module16OperationalStatus 16772;
BA_ "SigType" SG_ 2364731646 Module15OperationalStatus 5;
BA_ "SPN" SG_ 2364731646 Module15OperationalStatus 16771;
BA_ "SigType" SG_ 2364731646 Module14OperationalStatus 5;
BA_ "SPN" SG_ 2364731646 Module14OperationalStatus 16770;
BA_ "SigType" SG_ 2364731646 Module13OperationalStatus 5;
BA_ "SPN" SG_ 2364731646 Module13OperationalStatus 16769;
BA_ "SigType" SG_ 2364731646 Module12OperationalStatus 5;
BA_ "SPN" SG_ 2364731646 Module12OperationalStatus 16768;
BA_ "SigType" SG_ 2364731646 Module11OperationalStatus 5;
BA_ "SPN" SG_ 2364731646 Module11OperationalStatus 16767;
BA_ "SigType" SG_ 2364731646 Module10OperationalStatus 5;
BA_ "SPN" SG_ 2364731646 Module10OperationalStatus 16766;
BA_ "SigType" SG_ 2364731646 Module9OperationalStatus 5;
BA_ "SPN" SG_ 2364731646 Module9OperationalStatus 16765;
BA_ "SigType" SG_ 2364731646 Module8OperationalStatus 5;
BA_ "SPN" SG_ 2364731646 Module8OperationalStatus 16764;
BA_ "SigType" SG_ 2364731646 Module7OperationalStatus 5;
BA_ "SPN" SG_ 2364731646 Module7OperationalStatus 16763;
BA_ "SigType" SG_ 2364731646 Module6OperationalStatus 5;
BA_ "SPN" SG_ 2364731646 Module6OperationalStatus 16762;
BA_ "SigType" SG_ 2364731646 Module5OperationalStatus 5;
BA_ "SPN" SG_ 2364731646 Module5OperationalStatus 16761;
BA_ "SigType" SG_ 2364731646 Module4OperationalStatus 5;
BA_ "SPN" SG_ 2364731646 Module4OperationalStatus 16760;
BA_ "SigType" SG_ 2364731646 Module3OperationalStatus 5;
BA_ "SPN" SG_ 2364731646 Module3OperationalStatus 16759;
BA_ "SigType" SG_ 2364731646 Module2OperationalStatus 5;
BA_ "SPN" SG_ 2364731646 Module2OperationalStatus 16758;
BA_ "SigType" SG_ 2364731646 Module1OperationalStatus 5;
BA_ "SPN" SG_ 2364731646 Module1OperationalStatus 16757;
BA_ "SigType" SG_ 2364731390 MaxChargeVLmt 1;
BA_ "SPN" SG_ 2364731390 MaxChargeVLmt 16756;
BA_ "SPN" SG_ 2364731390 ChargeEnergyCapacity 16755;
BA_ "SPN" SG_ 2364731390 DisEnergyCapacity 16754;
BA_ "SigType" SG_ 2364731134 Status1CRC 12;
BA_ "SPN" SG_ 2364731134 Status1CRC 16753;
BA_ "SigType" SG_ 2364731134 Status1Counter 11;
BA_ "SPN" SG_ 2364731134 Status1Counter 16752;
BA_ "SPN" SG_ 2364731134 OperationalStatus 16751;
BA_ "SPN" SG_ 2364731134 HVBusConnectionStatus 16750;
BA_ "SigType" SG_ 2364731134 InternalChargerStatus 5;
BA_ "SPN" SG_ 2364731134 InternalChargerStatus 16749;
BA_ "SigType" SG_ 2364731134 CellBalancingActive 4;
BA_ "SPN" SG_ 2364731134 CellBalancingActive 16748;
BA_ "SigType" SG_ 2364731134 CellBalanceStatus 4;
BA_ "SPN" SG_ 2364731134 CellBalanceStatus 16747;
BA_ "SPN" SG_ 2364731134 StOfChargeStatus 16746;
BA_ "SigType" SG_ 2364731134 InertiaSwStatus 4;
BA_ "SPN" SG_ 2364731134 InertiaSwStatus 16745;
BA_ "SigType" SG_ 2364731134 HVILStatus 4;
BA_ "SPN" SG_ 2364731134 HVILStatus 16744;
BA_ "SPN" SG_ 2364731134 HVBusPassiveIsolTestStatus 16743;
BA_ "SPN" SG_ 2364731134 HVBusActiveIsolTestStatus 16742;
BA_ "SigType" SG_ 2364731134 CenterOfPackContactorSt 4;
BA_ "SPN" SG_ 2364731134 CenterOfPackContactorSt 16741;
BA_ "SigType" SG_ 2364731134 HVBusPreChargeRelaySt 4;
BA_ "SPN" SG_ 2364731134 HVBusPreChargeRelaySt 16740;
BA_ "SPN" SG_ 2364731134 HVBusDisconnectForewarning 16739;
BA_ "SigType" SG_ 2364731134 HVBusContactorSt16738 4;
BA_ "SPN" SG_ 2364731134 HVBusContactorSt16738 16738;
BA_ "SigType" SG_ 2364731134 HVBusContactorSt 4;
BA_ "SPN" SG_ 2364731134 HVBusContactorSt 16737;
BA_ "SigType" SG_ 2364730878 Temp 1;
BA_ "SPN" SG_ 2364730878 Temp 16736;
BA_ "SigType" SG_ 2364730878 ETemp 1;
BA_ "SPN" SG_ 2364730878 ETemp 16735;
BA_ "SigType" SG_ 2364730878 OutCoolantTemp 1;
BA_ "SPN" SG_ 2364730878 OutCoolantTemp 16734;
BA_ "SigType" SG_ 2364730878 InCoolantTemp 1;
BA_ "SPN" SG_ 2364730878 InCoolantTemp 16733;
BA_ "SigType" SG_ 2364730878 IgntV 1;
BA_ "SPN" SG_ 2364730878 IgntV 16732;
BA_ "SigType" SG_ 2364730878 BusV 1;
BA_ "SPN" SG_ 2364730878 BusV 16731;
BA_ "SigType" SG_ 2364730622 HighestCellStOfCharge 1;
BA_ "SPN" SG_ 2364730622 HighestCellStOfCharge 16730;
BA_ "SigType" SG_ 2364730622 LowestCellStOfCharge 1;
BA_ "SPN" SG_ 2364730622 LowestCellStOfCharge 16729;
BA_ "SigType" SG_ 2364730622 ChargeCurLmt 1;
BA_ "GenSigStartValue" SG_ 2364730622 ChargeCurLmt 32000;
BA_ "SPN" SG_ 2364730622 ChargeCurLmt 16728;
BA_ "SigType" SG_ 2364730622 DisCurLmt 1;
BA_ "SPN" SG_ 2364730622 DisCurLmt 16727;
BA_ "SigType" SG_ 2364730366 CellBalancingCount 1;
BA_ "SPN" SG_ 2364730366 CellBalancingCount 16726;
BA_ "SigType" SG_ 2364730366 ChargeCapacity 1;
BA_ "SPN" SG_ 2364730366 ChargeCapacity 16725;
BA_ "SigType" SG_ 2364730366 DisCapacity 1;
BA_ "SPN" SG_ 2364730366 DisCapacity 16724;
BA_ "SigType" SG_ 2364730110 CellTempDiffStatus 4;
BA_ "SPN" SG_ 2364730110 CellTempDiffStatus 16723;
BA_ "SigType" SG_ 2364730110 AvgCellTemp 1;
BA_ "SPN" SG_ 2364730110 AvgCellTemp 16722;
BA_ "SigType" SG_ 2364730110 LowestCellTemp 1;
BA_ "SPN" SG_ 2364730110 LowestCellTemp 16721;
BA_ "SigType" SG_ 2364730110 HighestCellTemp 1;
BA_ "SPN" SG_ 2364730110 HighestCellTemp 16720;
BA_ "SPN" SG_ 2364729854 CellVDiffStatus 16719;
BA_ "SigType" SG_ 2364729854 LowestCellV 1;
BA_ "SPN" SG_ 2364729854 LowestCellV 16718;
BA_ "SigType" SG_ 2364729854 HighestCellV 1;
BA_ "SPN" SG_ 2364729854 HighestCellV 16717;
BA_ "SigType" SG_ 2364729854 FastUpdateStOfCharge 1;
BA_ "SPN" SG_ 2364729854 FastUpdateStOfCharge 16716;
BA_ "SigType" SG_ 2364729598 Cur 1;
BA_ "SPN" SG_ 2364729598 Cur 16715;
BA_ "SigType" SG_ 2364729598 Lvl 1;
BA_ "SPN" SG_ 2364729598 Lvl 16714;
BA_ "SigType" SG_ 2364729598 AvailableChargePwr 1;
BA_ "SPN" SG_ 2364729598 AvailableChargePwr 16713;
BA_ "SigType" SG_ 2364729598 AvailableDisPwr 1;
BA_ "SPN" SG_ 2364729598 AvailableDisPwr 16712;
BA_ "SigType" SG_ 2364729342 ChargePLDueToAnUndefinedCause 4;
BA_ "SPN" SG_ 2364729342 ChargePLDueToAnUndefinedCause 16711;
BA_ "SigType" SG_ 2364729342 ChargePLDueToBatCur 4;
BA_ "SPN" SG_ 2364729342 ChargePLDueToBatCur 16710;
BA_ "SigType" SG_ 2364729342 ChargePLDueToBatOrCellV 4;
BA_ "SPN" SG_ 2364729342 ChargePLDueToBatOrCellV 16709;
BA_ "SigType" SG_ 2364729342 ChargePLDueToBatDiagCondition 4;
BA_ "SPN" SG_ 2364729342 ChargePLDueToBatDiagCondition 16708;
BA_ "SigType" SG_ 2364729342 ChargePLDueToBatTemp 4;
BA_ "SPN" SG_ 2364729342 ChargePLDueToBatTemp 16707;
BA_ "SigType" SG_ 2364729342 ChargePLDueToStOfCharge 4;
BA_ "SPN" SG_ 2364729342 ChargePLDueToStOfCharge 16706;
BA_ "SigType" SG_ 2364729342 DisPLDueToAnUndefinedCause 4;
BA_ "SPN" SG_ 2364729342 DisPLDueToAnUndefinedCause 16705;
BA_ "SigType" SG_ 2364729342 DisPLDueToBatCur 4;
BA_ "SPN" SG_ 2364729342 DisPLDueToBatCur 16704;
BA_ "SigType" SG_ 2364729342 DisPLDueToBatOrCellV 4;
BA_ "SPN" SG_ 2364729342 DisPLDueToBatOrCellV 16703;
BA_ "SigType" SG_ 2364729342 DisPLDueToBatDiagCondition 4;
BA_ "SPN" SG_ 2364729342 DisPLDueToBatDiagCondition 16702;
BA_ "SigType" SG_ 2364729342 DisPLDueToBatTemp 4;
BA_ "SPN" SG_ 2364729342 DisPLDueToBatTemp 16701;
BA_ "SigType" SG_ 2364729342 DisPLDueToStOfCharge 4;
BA_ "SPN" SG_ 2364729342 DisPLDueToStOfCharge 16700;
BA_ "SigType" SG_ 2364729086 ActualChargeRate 1;
BA_ "SPN" SG_ 2364729086 ActualChargeRate 16672;
BA_ "SigType" SG_ 2364729086 LvlNegToChassisGroundV 1;
BA_ "SPN" SG_ 2364729086 LvlNegToChassisGroundV 16671;
BA_ "SigType" SG_ 2364729086 BusVNegToChassisGroundV 1;
BA_ "SPN" SG_ 2364729086 BusVNegToChassisGroundV 16670;
BA_ "SigType" SG_ 2364728830 HVBusPassiveIsolTestResults 1;
BA_ "SPN" SG_ 2364728830 HVBusPassiveIsolTestResults 16669;
BA_ "SigType" SG_ 2364728830 HVBusActiveIsolTestResults 1;
BA_ "SPN" SG_ 2364728830 HVBusActiveIsolTestResults 16668;
BA_ "SigType" SG_ 2364728830 LowestCellStOfChargeCellNum 1;
BA_ "SPN" SG_ 2364728830 LowestCellStOfChargeCellNum 16667;
BA_ "SigType" SG_ 2364728830 LowestCellStOfChargeModuleNum 1;
BA_ "SPN" SG_ 2364728830 LowestCellStOfChargeModuleNum 16666;
BA_ "SigType" SG_ 2364728830 HighestCellStOfChargeCellNum 1;
BA_ "SPN" SG_ 2364728830 HighestCellStOfChargeCellNum 16665;
BA_ "SigType" SG_ 2364728830 HighestCellStOfChargeModuleNum 1;
BA_ "SPN" SG_ 2364728830 HighestCellStOfChargeModuleNum 16664;
BA_ "SigType" SG_ 2364728574 Data9CRC 12;
BA_ "SPN" SG_ 2364728574 Data9CRC 23033;
BA_ "SigType" SG_ 2364728574 Data9Counter 11;
BA_ "SPN" SG_ 2364728574 Data9Counter 23032;
BA_ "SigType" SG_ 2364728574 Data9EmbeddedIntegritySupport 5;
BA_ "SPN" SG_ 2364728574 Data9EmbeddedIntegritySupport 23031;
BA_ "SigType" SG_ 2364728574 HVESS20ThermalEventDetected 4;
BA_ "SPN" SG_ 2364728574 HVESS20ThermalEventDetected 21307;
BA_ "SigType" SG_ 2364728574 LowestCellTempCellNum 1;
BA_ "SPN" SG_ 2364728574 LowestCellTempCellNum 16663;
BA_ "SigType" SG_ 2364728574 LowestCellTempModuleNum 1;
BA_ "SPN" SG_ 2364728574 LowestCellTempModuleNum 16662;
BA_ "SigType" SG_ 2364728574 HighestCellTempCellNum 1;
BA_ "SPN" SG_ 2364728574 HighestCellTempCellNum 16661;
BA_ "SigType" SG_ 2364728574 HighestCellTempModuleNum 1;
BA_ "SPN" SG_ 2364728574 HighestCellTempModuleNum 16660;
BA_ "SigType" SG_ 2364728318 AvgCellV 1;
BA_ "SPN" SG_ 2364728318 AvgCellV 16659;
BA_ "SigType" SG_ 2364728318 LowestCellVCellNum 1;
BA_ "SPN" SG_ 2364728318 LowestCellVCellNum 16658;
BA_ "SigType" SG_ 2364728318 LowestCellVModuleNum 1;
BA_ "SPN" SG_ 2364728318 LowestCellVModuleNum 16657;
BA_ "SigType" SG_ 2364728318 HighestCellVCellNum 1;
BA_ "SPN" SG_ 2364728318 HighestCellVCellNum 16656;
BA_ "SigType" SG_ 2364728318 HighestCellVModuleNum 1;
BA_ "SPN" SG_ 2364728318 HighestCellVModuleNum 16655;
BA_ "SigType" SG_ 2364728062 TMSCoolantLvl 4;
BA_ "SPN" SG_ 2364728062 TMSCoolantLvl 16654;
BA_ "SPN" SG_ 2364728062 TMSMode 16653;
BA_ "SigType" SG_ 2364728062 TMSHVILStatus 4;
BA_ "SPN" SG_ 2364728062 TMSHVILStatus 16652;
BA_ "SigType" SG_ 2364728062 TMSHtrStatus 5;
BA_ "SPN" SG_ 2364728062 TMSHtrStatus 16651;
BA_ "SigType" SG_ 2364728062 TMSRelHumidty 1;
BA_ "SPN" SG_ 2364728062 TMSRelHumidty 16650;
BA_ "SigType" SG_ 2364728062 TMSCompressorSpd 1;
BA_ "SPN" SG_ 2364728062 TMSCompressorSpd 16649;
BA_ "SigType" SG_ 2364728062 TMSHVInputPwr 1;
BA_ "SPN" SG_ 2364728062 TMSHVInputPwr 16648;
BA_ "SigType" SG_ 2364728062 TMSSLIInputPwr 1;
BA_ "SPN" SG_ 2364728062 TMSSLIInputPwr 16647;
BA_ "SigType" SG_ 2364727806 Module32OperationalStatus 5;
BA_ "SPN" SG_ 2364727806 Module32OperationalStatus 16646;
BA_ "SigType" SG_ 2364727806 Module31OperationalStatus 5;
BA_ "SPN" SG_ 2364727806 Module31OperationalStatus 16645;
BA_ "SigType" SG_ 2364727806 Module30OperationalStatus 5;
BA_ "SPN" SG_ 2364727806 Module30OperationalStatus 16644;
BA_ "SigType" SG_ 2364727806 Module29OperationalStatus 5;
BA_ "SPN" SG_ 2364727806 Module29OperationalStatus 16643;
BA_ "SigType" SG_ 2364727806 Module28OperationalStatus 5;
BA_ "SPN" SG_ 2364727806 Module28OperationalStatus 16642;
BA_ "SigType" SG_ 2364727806 Module27OperationalStatus 5;
BA_ "SPN" SG_ 2364727806 Module27OperationalStatus 16641;
BA_ "SigType" SG_ 2364727806 Module26OperationalStatus 5;
BA_ "SPN" SG_ 2364727806 Module26OperationalStatus 16640;
BA_ "SigType" SG_ 2364727806 Module25OperationalStatus 5;
BA_ "SPN" SG_ 2364727806 Module25OperationalStatus 16639;
BA_ "SigType" SG_ 2364727806 Module24OperationalStatus 5;
BA_ "SPN" SG_ 2364727806 Module24OperationalStatus 16638;
BA_ "SigType" SG_ 2364727806 Module23OperationalStatus 5;
BA_ "SPN" SG_ 2364727806 Module23OperationalStatus 16637;
BA_ "SigType" SG_ 2364727806 Module22OperationalStatus 5;
BA_ "SPN" SG_ 2364727806 Module22OperationalStatus 16636;
BA_ "SigType" SG_ 2364727806 Module21OperationalStatus 5;
BA_ "SPN" SG_ 2364727806 Module21OperationalStatus 16635;
BA_ "SigType" SG_ 2364727806 Module20OperationalStatus 5;
BA_ "SPN" SG_ 2364727806 Module20OperationalStatus 16634;
BA_ "SigType" SG_ 2364727806 Module19OperationalStatus 5;
BA_ "SPN" SG_ 2364727806 Module19OperationalStatus 16633;
BA_ "SigType" SG_ 2364727806 Module18OperationalStatus 5;
BA_ "SPN" SG_ 2364727806 Module18OperationalStatus 16632;
BA_ "SigType" SG_ 2364727806 Module17OperationalStatus 5;
BA_ "SPN" SG_ 2364727806 Module17OperationalStatus 16631;
BA_ "SigType" SG_ 2364727806 Module16OperationalStatus 5;
BA_ "SPN" SG_ 2364727806 Module16OperationalStatus 16630;
BA_ "SigType" SG_ 2364727806 Module15OperationalStatus 5;
BA_ "SPN" SG_ 2364727806 Module15OperationalStatus 16629;
BA_ "SigType" SG_ 2364727806 Module14OperationalStatus 5;
BA_ "SPN" SG_ 2364727806 Module14OperationalStatus 16628;
BA_ "SigType" SG_ 2364727806 Module13OperationalStatus 5;
BA_ "SPN" SG_ 2364727806 Module13OperationalStatus 16627;
BA_ "SigType" SG_ 2364727806 Module12OperationalStatus 5;
BA_ "SPN" SG_ 2364727806 Module12OperationalStatus 16626;
BA_ "SigType" SG_ 2364727806 Module11OperationalStatus 5;
BA_ "SPN" SG_ 2364727806 Module11OperationalStatus 16625;
BA_ "SigType" SG_ 2364727806 Module10OperationalStatus 5;
BA_ "SPN" SG_ 2364727806 Module10OperationalStatus 16624;
BA_ "SigType" SG_ 2364727806 Module9OperationalStatus 5;
BA_ "SPN" SG_ 2364727806 Module9OperationalStatus 16623;
BA_ "SigType" SG_ 2364727806 Module8OperationalStatus 5;
BA_ "SPN" SG_ 2364727806 Module8OperationalStatus 16622;
BA_ "SigType" SG_ 2364727806 Module7OperationalStatus 5;
BA_ "SPN" SG_ 2364727806 Module7OperationalStatus 16621;
BA_ "SigType" SG_ 2364727806 Module6OperationalStatus 5;
BA_ "SPN" SG_ 2364727806 Module6OperationalStatus 16620;
BA_ "SigType" SG_ 2364727806 Module5OperationalStatus 5;
BA_ "SPN" SG_ 2364727806 Module5OperationalStatus 16619;
BA_ "SigType" SG_ 2364727806 Module4OperationalStatus 5;
BA_ "SPN" SG_ 2364727806 Module4OperationalStatus 16618;
BA_ "SigType" SG_ 2364727806 Module3OperationalStatus 5;
BA_ "SPN" SG_ 2364727806 Module3OperationalStatus 16617;
BA_ "SigType" SG_ 2364727806 Module2OperationalStatus 5;
BA_ "SPN" SG_ 2364727806 Module2OperationalStatus 16616;
BA_ "SigType" SG_ 2364727806 Module1OperationalStatus 5;
BA_ "SPN" SG_ 2364727806 Module1OperationalStatus 16615;
BA_ "SigType" SG_ 2364727550 MaxChargeVLmt 1;
BA_ "SPN" SG_ 2364727550 MaxChargeVLmt 16614;
BA_ "SPN" SG_ 2364727550 ChargeEnergyCapacity 16613;
BA_ "SPN" SG_ 2364727550 DisEnergyCapacity 16612;
BA_ "SigType" SG_ 2364727294 Status1CRC 12;
BA_ "SPN" SG_ 2364727294 Status1CRC 16611;
BA_ "SigType" SG_ 2364727294 Status1Counter 11;
BA_ "SPN" SG_ 2364727294 Status1Counter 16610;
BA_ "SPN" SG_ 2364727294 OperationalStatus 16609;
BA_ "SPN" SG_ 2364727294 HVBusConnectionStatus 16608;
BA_ "SigType" SG_ 2364727294 InternalChargerStatus 5;
BA_ "SPN" SG_ 2364727294 InternalChargerStatus 16607;
BA_ "SigType" SG_ 2364727294 CellBalancingActive 4;
BA_ "SPN" SG_ 2364727294 CellBalancingActive 16606;
BA_ "SigType" SG_ 2364727294 CellBalanceStatus 4;
BA_ "SPN" SG_ 2364727294 CellBalanceStatus 16605;
BA_ "SPN" SG_ 2364727294 StOfChargeStatus 16604;
BA_ "SigType" SG_ 2364727294 InertiaSwStatus 4;
BA_ "SPN" SG_ 2364727294 InertiaSwStatus 16603;
BA_ "SigType" SG_ 2364727294 HVILStatus 4;
BA_ "SPN" SG_ 2364727294 HVILStatus 16602;
BA_ "SPN" SG_ 2364727294 HVBusPassiveIsolTestStatus 16601;
BA_ "SPN" SG_ 2364727294 HVBusActiveIsolTestStatus 16600;
BA_ "SigType" SG_ 2364727294 CenterOfPackContactorSt 4;
BA_ "SPN" SG_ 2364727294 CenterOfPackContactorSt 16599;
BA_ "SigType" SG_ 2364727294 HVBusPreChargeRelaySt 4;
BA_ "SPN" SG_ 2364727294 HVBusPreChargeRelaySt 16598;
BA_ "SPN" SG_ 2364727294 HVBusDisconnectForewarning 16597;
BA_ "SigType" SG_ 2364727294 HVBusContactorSt16596 4;
BA_ "SPN" SG_ 2364727294 HVBusContactorSt16596 16596;
BA_ "SigType" SG_ 2364727294 HVBusContactorSt 4;
BA_ "SPN" SG_ 2364727294 HVBusContactorSt 16595;
BA_ "SigType" SG_ 2364727038 Temp 1;
BA_ "SPN" SG_ 2364727038 Temp 16594;
BA_ "SigType" SG_ 2364727038 ETemp 1;
BA_ "SPN" SG_ 2364727038 ETemp 16593;
BA_ "SigType" SG_ 2364727038 OutCoolantTemp 1;
BA_ "SPN" SG_ 2364727038 OutCoolantTemp 16592;
BA_ "SigType" SG_ 2364727038 InCoolantTemp 1;
BA_ "SPN" SG_ 2364727038 InCoolantTemp 16591;
BA_ "SigType" SG_ 2364727038 IgntV 1;
BA_ "SPN" SG_ 2364727038 IgntV 16590;
BA_ "SigType" SG_ 2364727038 BusV 1;
BA_ "SPN" SG_ 2364727038 BusV 16589;
BA_ "SigType" SG_ 2364726782 HighestCellStOfCharge 1;
BA_ "SPN" SG_ 2364726782 HighestCellStOfCharge 16588;
BA_ "SigType" SG_ 2364726782 LowestCellStOfCharge 1;
BA_ "SPN" SG_ 2364726782 LowestCellStOfCharge 16587;
BA_ "SigType" SG_ 2364726782 ChargeCurLmt 1;
BA_ "GenSigStartValue" SG_ 2364726782 ChargeCurLmt 32000;
BA_ "SPN" SG_ 2364726782 ChargeCurLmt 16586;
BA_ "SigType" SG_ 2364726782 DisCurLmt 1;
BA_ "SPN" SG_ 2364726782 DisCurLmt 16585;
BA_ "SigType" SG_ 2364726526 CellBalancingCount 1;
BA_ "SPN" SG_ 2364726526 CellBalancingCount 16584;
BA_ "SigType" SG_ 2364726526 ChargeCapacity 1;
BA_ "SPN" SG_ 2364726526 ChargeCapacity 16583;
BA_ "SigType" SG_ 2364726526 DisCapacity 1;
BA_ "SPN" SG_ 2364726526 DisCapacity 16582;
BA_ "SigType" SG_ 2364726270 CellTempDiffStatus 4;
BA_ "SPN" SG_ 2364726270 CellTempDiffStatus 16581;
BA_ "SigType" SG_ 2364726270 AvgCellTemp 1;
BA_ "SPN" SG_ 2364726270 AvgCellTemp 16580;
BA_ "SigType" SG_ 2364726270 LowestCellTemp 1;
BA_ "SPN" SG_ 2364726270 LowestCellTemp 16579;
BA_ "SigType" SG_ 2364726270 HighestCellTemp 1;
BA_ "SPN" SG_ 2364726270 HighestCellTemp 16578;
BA_ "SPN" SG_ 2364726014 CellVDiffStatus 16577;
BA_ "SigType" SG_ 2364726014 LowestCellV 1;
BA_ "SPN" SG_ 2364726014 LowestCellV 16576;
BA_ "SigType" SG_ 2364726014 HighestCellV 1;
BA_ "SPN" SG_ 2364726014 HighestCellV 16575;
BA_ "SigType" SG_ 2364726014 FastUpdateStOfCharge 1;
BA_ "SPN" SG_ 2364726014 FastUpdateStOfCharge 16574;
BA_ "SigType" SG_ 2364725758 Cur 1;
BA_ "SPN" SG_ 2364725758 Cur 16573;
BA_ "SigType" SG_ 2364725758 Lvl 1;
BA_ "SPN" SG_ 2364725758 Lvl 16572;
BA_ "SigType" SG_ 2364725758 AvailableChargePwr 1;
BA_ "SPN" SG_ 2364725758 AvailableChargePwr 16571;
BA_ "SigType" SG_ 2364725758 AvailableDisPwr 1;
BA_ "SPN" SG_ 2364725758 AvailableDisPwr 16570;
BA_ "SigType" SG_ 2364725502 ChargePLDueToAnUndefinedCause 4;
BA_ "SPN" SG_ 2364725502 ChargePLDueToAnUndefinedCause 16569;
BA_ "SigType" SG_ 2364725502 ChargePLDueToBatCur 4;
BA_ "SPN" SG_ 2364725502 ChargePLDueToBatCur 16568;
BA_ "SigType" SG_ 2364725502 ChargePLDueToBatOrCellV 4;
BA_ "SPN" SG_ 2364725502 ChargePLDueToBatOrCellV 16567;
BA_ "SigType" SG_ 2364725502 ChargePLDueToBatDiagCondition 4;
BA_ "SPN" SG_ 2364725502 ChargePLDueToBatDiagCondition 16566;
BA_ "SigType" SG_ 2364725502 ChargePLDueToBatTemp 4;
BA_ "SPN" SG_ 2364725502 ChargePLDueToBatTemp 16565;
BA_ "SigType" SG_ 2364725502 ChargePLDueToStOfCharge 4;
BA_ "SPN" SG_ 2364725502 ChargePLDueToStOfCharge 16564;
BA_ "SigType" SG_ 2364725502 DisPLDueToAnUndefinedCause 4;
BA_ "SPN" SG_ 2364725502 DisPLDueToAnUndefinedCause 16563;
BA_ "SigType" SG_ 2364725502 DisPLDueToBatCur 4;
BA_ "SPN" SG_ 2364725502 DisPLDueToBatCur 16562;
BA_ "SigType" SG_ 2364725502 DisPLDueToBatOrCellV 4;
BA_ "SPN" SG_ 2364725502 DisPLDueToBatOrCellV 16561;
BA_ "SigType" SG_ 2364725502 DisPLDueToBatDiagCondition 4;
BA_ "SPN" SG_ 2364725502 DisPLDueToBatDiagCondition 16560;
BA_ "SigType" SG_ 2364725502 DisPLDueToBatTemp 4;
BA_ "SPN" SG_ 2364725502 DisPLDueToBatTemp 16559;
BA_ "SigType" SG_ 2364725502 DisPLDueToStOfCharge 4;
BA_ "SPN" SG_ 2364725502 DisPLDueToStOfCharge 16558;
BA_ "SigType" SG_ 2364725246 ActualChargeRate 1;
BA_ "SPN" SG_ 2364725246 ActualChargeRate 16530;
BA_ "SigType" SG_ 2364725246 LvlNegToChassisGroundV 1;
BA_ "SPN" SG_ 2364725246 LvlNegToChassisGroundV 16529;
BA_ "SigType" SG_ 2364725246 BusVNegToChassisGroundV 1;
BA_ "SPN" SG_ 2364725246 BusVNegToChassisGroundV 16528;
BA_ "SigType" SG_ 2364724990 HVBusPassiveIsolTestResults 1;
BA_ "SPN" SG_ 2364724990 HVBusPassiveIsolTestResults 16527;
BA_ "SigType" SG_ 2364724990 HVBusActiveIsolTestResults 1;
BA_ "SPN" SG_ 2364724990 HVBusActiveIsolTestResults 16526;
BA_ "SigType" SG_ 2364724990 LowestCellStOfChargeCellNum 1;
BA_ "SPN" SG_ 2364724990 LowestCellStOfChargeCellNum 16525;
BA_ "SigType" SG_ 2364724990 LowestCellStOfChargeModuleNum 1;
BA_ "SPN" SG_ 2364724990 LowestCellStOfChargeModuleNum 16524;
BA_ "SigType" SG_ 2364724990 HighestCellStOfChargeCellNum 1;
BA_ "SPN" SG_ 2364724990 HighestCellStOfChargeCellNum 16523;
BA_ "SigType" SG_ 2364724990 HighestCellStOfChargeModuleNum 1;
BA_ "SPN" SG_ 2364724990 HighestCellStOfChargeModuleNum 16522;
BA_ "SigType" SG_ 2364724734 Data9CRC 12;
BA_ "SPN" SG_ 2364724734 Data9CRC 23030;
BA_ "SigType" SG_ 2364724734 Data9Counter 11;
BA_ "SPN" SG_ 2364724734 Data9Counter 23029;
BA_ "SigType" SG_ 2364724734 Data9EmbeddedIntegritySupport 5;
BA_ "SPN" SG_ 2364724734 Data9EmbeddedIntegritySupport 23028;
BA_ "SigType" SG_ 2364724734 HVESS19ThermalEventDetected 4;
BA_ "SPN" SG_ 2364724734 HVESS19ThermalEventDetected 21306;
BA_ "SigType" SG_ 2364724734 LowestCellTempCellNum 1;
BA_ "SPN" SG_ 2364724734 LowestCellTempCellNum 16521;
BA_ "SigType" SG_ 2364724734 LowestCellTempModuleNum 1;
BA_ "SPN" SG_ 2364724734 LowestCellTempModuleNum 16520;
BA_ "SigType" SG_ 2364724734 HighestCellTempCellNum 1;
BA_ "SPN" SG_ 2364724734 HighestCellTempCellNum 16519;
BA_ "SigType" SG_ 2364724734 HighestCellTempModuleNum 1;
BA_ "SPN" SG_ 2364724734 HighestCellTempModuleNum 16518;
BA_ "SigType" SG_ 2364724478 AvgCellV 1;
BA_ "SPN" SG_ 2364724478 AvgCellV 16517;
BA_ "SigType" SG_ 2364724478 LowestCellVCellNum 1;
BA_ "SPN" SG_ 2364724478 LowestCellVCellNum 16516;
BA_ "SigType" SG_ 2364724478 LowestCellVModuleNum 1;
BA_ "SPN" SG_ 2364724478 LowestCellVModuleNum 16515;
BA_ "SigType" SG_ 2364724478 HighestCellVCellNum 1;
BA_ "SPN" SG_ 2364724478 HighestCellVCellNum 16514;
BA_ "SigType" SG_ 2364724478 HighestCellVModuleNum 1;
BA_ "SPN" SG_ 2364724478 HighestCellVModuleNum 16513;
BA_ "SigType" SG_ 2364724222 TMSCoolantLvl 4;
BA_ "SPN" SG_ 2364724222 TMSCoolantLvl 16512;
BA_ "SPN" SG_ 2364724222 TMSMode 16511;
BA_ "SigType" SG_ 2364724222 TMSHVILStatus 4;
BA_ "SPN" SG_ 2364724222 TMSHVILStatus 16510;
BA_ "SigType" SG_ 2364724222 TMSHtrStatus 5;
BA_ "SPN" SG_ 2364724222 TMSHtrStatus 16509;
BA_ "SigType" SG_ 2364724222 TMSRelHumidty 1;
BA_ "SPN" SG_ 2364724222 TMSRelHumidty 16508;
BA_ "SigType" SG_ 2364724222 TMSCompressorSpd 1;
BA_ "SPN" SG_ 2364724222 TMSCompressorSpd 16507;
BA_ "SigType" SG_ 2364724222 TMSHVInputPwr 1;
BA_ "SPN" SG_ 2364724222 TMSHVInputPwr 16506;
BA_ "SigType" SG_ 2364724222 TMSSLIInputPwr 1;
BA_ "SPN" SG_ 2364724222 TMSSLIInputPwr 16505;
BA_ "SigType" SG_ 2364723966 Module32OperationalStatus 5;
BA_ "SPN" SG_ 2364723966 Module32OperationalStatus 16504;
BA_ "SigType" SG_ 2364723966 Module31OperationalStatus 5;
BA_ "SPN" SG_ 2364723966 Module31OperationalStatus 16503;
BA_ "SigType" SG_ 2364723966 Module30OperationalStatus 5;
BA_ "SPN" SG_ 2364723966 Module30OperationalStatus 16502;
BA_ "SigType" SG_ 2364723966 Module29OperationalStatus 5;
BA_ "SPN" SG_ 2364723966 Module29OperationalStatus 16501;
BA_ "SigType" SG_ 2364723966 Module28OperationalStatus 5;
BA_ "SPN" SG_ 2364723966 Module28OperationalStatus 16500;
BA_ "SigType" SG_ 2364723966 Module27OperationalStatus 5;
BA_ "SPN" SG_ 2364723966 Module27OperationalStatus 16499;
BA_ "SigType" SG_ 2364723966 Module26OperationalStatus 5;
BA_ "SPN" SG_ 2364723966 Module26OperationalStatus 16498;
BA_ "SigType" SG_ 2364723966 Module25OperationalStatus 5;
BA_ "SPN" SG_ 2364723966 Module25OperationalStatus 16497;
BA_ "SigType" SG_ 2364723966 Module24OperationalStatus 5;
BA_ "SPN" SG_ 2364723966 Module24OperationalStatus 16496;
BA_ "SigType" SG_ 2364723966 Module23OperationalStatus 5;
BA_ "SPN" SG_ 2364723966 Module23OperationalStatus 16495;
BA_ "SigType" SG_ 2364723966 Module22OperationalStatus 5;
BA_ "SPN" SG_ 2364723966 Module22OperationalStatus 16494;
BA_ "SigType" SG_ 2364723966 Module21OperationalStatus 5;
BA_ "SPN" SG_ 2364723966 Module21OperationalStatus 16493;
BA_ "SigType" SG_ 2364723966 Module20OperationalStatus 5;
BA_ "SPN" SG_ 2364723966 Module20OperationalStatus 16492;
BA_ "SigType" SG_ 2364723966 Module19OperationalStatus 5;
BA_ "SPN" SG_ 2364723966 Module19OperationalStatus 16491;
BA_ "SigType" SG_ 2364723966 Module18OperationalStatus 5;
BA_ "SPN" SG_ 2364723966 Module18OperationalStatus 16490;
BA_ "SigType" SG_ 2364723966 Module17OperationalStatus 5;
BA_ "SPN" SG_ 2364723966 Module17OperationalStatus 16489;
BA_ "SigType" SG_ 2364723966 Module16OperationalStatus 5;
BA_ "SPN" SG_ 2364723966 Module16OperationalStatus 16488;
BA_ "SigType" SG_ 2364723966 Module15OperationalStatus 5;
BA_ "SPN" SG_ 2364723966 Module15OperationalStatus 16487;
BA_ "SigType" SG_ 2364723966 Module14OperationalStatus 5;
BA_ "SPN" SG_ 2364723966 Module14OperationalStatus 16486;
BA_ "SigType" SG_ 2364723966 Module13OperationalStatus 5;
BA_ "SPN" SG_ 2364723966 Module13OperationalStatus 16485;
BA_ "SigType" SG_ 2364723966 Module12OperationalStatus 5;
BA_ "SPN" SG_ 2364723966 Module12OperationalStatus 16484;
BA_ "SigType" SG_ 2364723966 Module11OperationalStatus 5;
BA_ "SPN" SG_ 2364723966 Module11OperationalStatus 16483;
BA_ "SigType" SG_ 2364723966 Module10OperationalStatus 5;
BA_ "SPN" SG_ 2364723966 Module10OperationalStatus 16482;
BA_ "SigType" SG_ 2364723966 Module9OperationalStatus 5;
BA_ "SPN" SG_ 2364723966 Module9OperationalStatus 16481;
BA_ "SigType" SG_ 2364723966 Module8OperationalStatus 5;
BA_ "SPN" SG_ 2364723966 Module8OperationalStatus 16480;
BA_ "SigType" SG_ 2364723966 Module7OperationalStatus 5;
BA_ "SPN" SG_ 2364723966 Module7OperationalStatus 16479;
BA_ "SigType" SG_ 2364723966 Module6OperationalStatus 5;
BA_ "SPN" SG_ 2364723966 Module6OperationalStatus 16478;
BA_ "SigType" SG_ 2364723966 Module5OperationalStatus 5;
BA_ "SPN" SG_ 2364723966 Module5OperationalStatus 16477;
BA_ "SigType" SG_ 2364723966 Module4OperationalStatus 5;
BA_ "SPN" SG_ 2364723966 Module4OperationalStatus 16476;
BA_ "SigType" SG_ 2364723966 Module3OperationalStatus 5;
BA_ "SPN" SG_ 2364723966 Module3OperationalStatus 16475;
BA_ "SigType" SG_ 2364723966 Module2OperationalStatus 5;
BA_ "SPN" SG_ 2364723966 Module2OperationalStatus 16474;
BA_ "SigType" SG_ 2364723966 Module1OperationalStatus 5;
BA_ "SPN" SG_ 2364723966 Module1OperationalStatus 16473;
BA_ "SigType" SG_ 2364723710 MaxChargeVLmt 1;
BA_ "SPN" SG_ 2364723710 MaxChargeVLmt 16472;
BA_ "SPN" SG_ 2364723710 ChargeEnergyCapacity 16471;
BA_ "SPN" SG_ 2364723710 DisEnergyCapacity 16470;
VAL_ 2364733182 ChargePLDueToAnUndefinedCause 3 "Not Available" 2 "Error" 1 "Power limited for this reason" 0 "No power limit for this reason" ;
VAL_ 2364733182 ChargePLDueToBatCur 3 "Not Available" 2 "Error" 1 "Power limited for this reason" 0 "No power limit for this reason" ;
VAL_ 2364733182 ChargePLDueToBatOrCellV 3 "Not Available" 2 "Error" 1 "Power limited for this reason" 0 "No power limit for this reason" ;
VAL_ 2364733182 ChargePLDueToBatDiagCondition 3 "Not Available" 2 "Error" 1 "Power limited for this reason" 0 "No power limit for this reason" ;
VAL_ 2364733182 ChargePLDueToBatTemp 3 "Not Available" 2 "Error" 1 "Power limited for this reason" 0 "No power limit for this reason" ;
VAL_ 2364733182 ChargePLDueToStOfCharge 3 "Not Available" 2 "Error" 1 "Power limited for this reason" 0 "No power limit for this reason" ;
VAL_ 2364733182 DisPLDueToAnUndefinedCause 3 "Not Available" 2 "Error" 1 "Power limited for this reason" 0 "No power limit for this reason" ;
VAL_ 2364733182 DisPLDueToBatCur 3 "Not Available" 2 "Error" 1 "Power limited for this reason" 0 "No power limit for this reason" ;
VAL_ 2364733182 DisPLDueToBatOrCellV 3 "Not Available" 2 "Error" 1 "Power limited for this reason" 0 "No power limit for this reason" ;
VAL_ 2364733182 DisPLDueToBatDiagCondition 3 "Not Available" 2 "Error" 1 "Power limited for this reason" 0 "No power limit for this reason" ;
VAL_ 2364733182 DisPLDueToBatTemp 3 "Not Available" 2 "Error" 1 "Power limited for this reason" 0 "No power limit for this reason" ;
VAL_ 2364733182 DisPLDueToStOfCharge 3 "Not Available" 2 "Error" 1 "Power limited for this reason" 0 "No power limit for this reason" ;
VAL_ 2364732414 Data9EmbeddedIntegritySupport 3 "CRC and Counter are not supported by the sender" 2 "Reserved" 1 "Protection is supported using J1939-76 SHM" 0 "Embedded CRC and Counter are supported by the sender" ;
VAL_ 2364732414 HVESS21ThermalEventDetected 3 "Not available" 2 "Error" 1 "Thermal Event Detected" 0 "No Thermal Event Detected" ;
VAL_ 2364731902 TMSCoolantLvl 3 "Not Available" 2 "Error" 1 "Coolant Level is sufficient" 0 "Coolant Level is not sufficient" ;
VAL_ 2364731902 TMSMode 15 "Not Available" 14 "Faulted" 13 "Reserved" 12 "Reserved" 11 "Reserved" 10 "Reserved" 9 "Reserved" 8 "Reserved" 7 "Reserved" 6 "Reserved" 5 "Maintaining" 4 "Drying" 3 "Heating" 2 "Cooling" 1 "Circulating" 0 "Off" ;
VAL_ 2364731902 TMSHVILStatus 3 "Not Available" 2 "Error" 1 "HVIL Open" 0 "HVIL Closed" ;
VAL_ 2364731902 TMSHtrStatus 3 "Not Available" 2 "Error" 1 "Heater On" 0 "Heater Off" ;
VAL_ 2364731646 Module32OperationalStatus 3 "Not Available" 2 "Error" 1 "Operational" 0 "Not Operational" ;
VAL_ 2364731646 Module31OperationalStatus 3 "Not Available" 2 "Error" 1 "Operational" 0 "Not Operational" ;
VAL_ 2364731646 Module30OperationalStatus 3 "Not Available" 2 "Error" 1 "Operational" 0 "Not Operational" ;
VAL_ 2364731646 Module29OperationalStatus 3 "Not Available" 2 "Error" 1 "Operational" 0 "Not Operational" ;
VAL_ 2364731646 Module28OperationalStatus 3 "Not Available" 2 "Error" 1 "Operational" 0 "Not Operational" ;
VAL_ 2364731646 Module27OperationalStatus 3 "Not Available" 2 "Error" 1 "Operational" 0 "Not Operational" ;
VAL_ 2364731646 Module26OperationalStatus 3 "Not Available" 2 "Error" 1 "Operational" 0 "Not Operational" ;
VAL_ 2364731646 Module25OperationalStatus 3 "Not Available" 2 "Error" 1 "Operational" 0 "Not Operational" ;
VAL_ 2364731646 Module24OperationalStatus 3 "Not Available" 2 "Error" 1 "Operational" 0 "Not Operational" ;
VAL_ 2364731646 Module23OperationalStatus 3 "Not Available" 2 "Error" 1 "Operational" 0 "Not Operational" ;
VAL_ 2364731646 Module22OperationalStatus 3 "Not Available" 2 "Error" 1 "Operational" 0 "Not Operational" ;
VAL_ 2364731646 Module21OperationalStatus 3 "Not Available" 2 "Error" 1 "Operational" 0 "Not Operational" ;
VAL_ 2364731646 Module20OperationalStatus 3 "Not Available" 2 "Error" 1 "Operational" 0 "Not Operational" ;
VAL_ 2364731646 Module19OperationalStatus 3 "Not Available" 2 "Error" 1 "Operational" 0 "Not Operational" ;
VAL_ 2364731646 Module18OperationalStatus 3 "Not Available" 2 "Error" 1 "Operational" 0 "Not Operational" ;
VAL_ 2364731646 Module17OperationalStatus 3 "Not Available" 2 "Error" 1 "Operational" 0 "Not Operational" ;
VAL_ 2364731646 Module16OperationalStatus 3 "Not Available" 2 "Error" 1 "Operational" 0 "Not Operational" ;
VAL_ 2364731646 Module15OperationalStatus 3 "Not Available" 2 "Error" 1 "Operational" 0 "Not Operational" ;
VAL_ 2364731646 Module14OperationalStatus 3 "Not Available" 2 "Error" 1 "Operational" 0 "Not Operational" ;
VAL_ 2364731646 Module13OperationalStatus 3 "Not Available" 2 "Error" 1 "Operational" 0 "Not Operational" ;
VAL_ 2364731646 Module12OperationalStatus 3 "Not Available" 2 "Error" 1 "Operational" 0 "Not Operational" ;
VAL_ 2364731646 Module11OperationalStatus 3 "Not Available" 2 "Error" 1 "Operational" 0 "Not Operational" ;
VAL_ 2364731646 Module10OperationalStatus 3 "Not Available" 2 "Error" 1 "Operational" 0 "Not Operational" ;
VAL_ 2364731646 Module9OperationalStatus 3 "Not Available" 2 "Error" 1 "Operational" 0 "Not Operational" ;
VAL_ 2364731646 Module8OperationalStatus 3 "Not Available" 2 "Error" 1 "Operational" 0 "Not Operational" ;
VAL_ 2364731646 Module7OperationalStatus 3 "Not Available" 2 "Error" 1 "Operational" 0 "Not Operational" ;
VAL_ 2364731646 Module6OperationalStatus 3 "Not Available" 2 "Error" 1 "Operational" 0 "Not Operational" ;
VAL_ 2364731646 Module5OperationalStatus 3 "Not Available" 2 "Error" 1 "Operational" 0 "Not Operational" ;
VAL_ 2364731646 Module4OperationalStatus 3 "Not Available" 2 "Error" 1 "Operational" 0 "Not Operational" ;
VAL_ 2364731646 Module3OperationalStatus 3 "Not Available" 2 "Error" 1 "Operational" 0 "Not Operational" ;
VAL_ 2364731646 Module2OperationalStatus 3 "Not Available" 2 "Error" 1 "Operational" 0 "Not Operational" ;
VAL_ 2364731646 Module1OperationalStatus 3 "Not Available" 2 "Error" 1 "Operational" 0 "Not Operational" ;
VAL_ 2364731134 OperationalStatus 15 "Not Available" 14 "Error" 13 "Reserved" 12 "Reserved" 11 "Reserved" 10 "Reserved" 9 "Reserved" 8 "Reserved" 7 "Reserved" 6 "Disabled by internal decision of HVES controller" 5 "Disabled by external command" 4 "Emergency Power-Down In Process" 3 "Normal Power-Down in Process" 2 "Operational." 1 "Initialization Complete" 0 "Initialization in process" ;
VAL_ 2364731134 HVBusConnectionStatus 15 "Not Available" 14 "Error" 13 "Reserved" 12 "Reserved" 11 "Reserved" 10 "Reserved" 9 "Reserved" 8 "Reserved" 7 "Reserved" 6 "Reserved" 5 "Reserved" 4 "Disconnected,  Precharge Failed" 3 "Disconnection in Process" 2 "Connection in Process" 1 "Connected" 0 "Disconnected, One or more contactors are open" ;
VAL_ 2364731134 InternalChargerStatus 3 "Not Available" 2 "Error" 1 "Charging on" 0 "Charging off" ;
VAL_ 2364731134 CellBalancingActive 3 "Not Available" 2 "Error" 1 "Cell balancing is active" 0 "Cell balancing is not active" ;
VAL_ 2364731134 CellBalanceStatus 3 "Not Available" 2 "Error" 1 "Cells are unbalanced" 0 "Cells are balanced" ;
VAL_ 2364731134 StOfChargeStatus 15 "Not  Available" 14 "Error" 13 "Reserved" 12 "Reserved" 11 "Reserved" 10 "Reserved" 9 "Reserved" 8 "Reserved" 7 "Reserved" 6 "SOC is above its recommended upper limit" 5 "SOC is at its recommended upper limit" 4 "SOC is approaching its recommended upper limit" 3 "SOC is below its recommended lower limit" 2 "SOC is at its recommended lower limit" 1 "SOC is approaching its recommended lower limit" 0 "SOC level is acceptable" ;
VAL_ 2364731134 InertiaSwStatus 3 "Not Available" 2 "Error" 1 "Impact sensed" 0 "No impact sensed" ;
VAL_ 2364731134 HVILStatus 3 "Not Available" 2 "Error" 1 "HVIL Open" 0 "HVIL Closed" ;
VAL_ 2364731134 HVBusPassiveIsolTestStatus 15 "Not available" 14 "Error" 13 "Reserved" 12 "Reserved" 11 "Reserved" 10 "Reserved" 9 "Reserved" 8 "Reserved" 7 "Reserved" 6 "Reserved" 5 "Test complete,  isolation fault" 4 "Test complete,  isolation marginal" 3 "Test complete,  isolation acceptable" 2 "Test in process" 1 "Test requested but not yet in process" 0 "No test requested / No test in process" ;
VAL_ 2364731134 HVBusActiveIsolTestStatus 15 "Not available" 14 "Error" 13 "Reserved" 12 "Reserved" 11 "Reserved" 10 "Reserved" 9 "Reserved" 8 "Reserved" 7 "Reserved" 6 "Reserved" 5 "Test complete,  isolation fault" 4 "Test complete,  isolation marginal" 3 "Test complete,  isolation acceptable" 2 "Test in process" 1 "Test requested but not yet in process" 0 "No test requested / No test in process" ;
VAL_ 2364731134 CenterOfPackContactorSt 3 "Not Available" 2 "Error" 1 "Contactor Closed" 0 "Contactor Open" ;
VAL_ 2364731134 HVBusPreChargeRelaySt 3 "Not Available" 2 "Error" 1 "Relay Closed" 0 "Relay Open" ;
VAL_ 2364731134 HVBusDisconnectForewarning 15 "Not Available" 14 "Error" 13 "Disconnect imminent" 12 "Reserved" 11 "Reserved" 10 "Reserved" 9 "Reserved" 8 "Reserved" 7 "Disconnect imminent due to battery pack current approaching maximum acceptable level" 6 "Disconnect imminent due to cell voltage approaching maximum acceptable level" 5 "Disconnect imminent due to cell voltage approaching minimum acceptable level" 4 "Disconnect imminent due to module voltage approaching maximum acceptable level" 3 "Disconnect imminent due to module voltage approaching minimum acceptable level" 2 "Disconnect imminent due to battery pack voltage approaching maximum acceptable level" 1 "Disconnect imminent due to battery pack voltage approaching minimum acceptable level" 0 "Disconnect not pending" ;
VAL_ 2364731134 HVBusContactorSt16738 3 "Not Available" 2 "Error" 1 "Contactor Closed" 0 "Contactor Open" ;
VAL_ 2364731134 HVBusContactorSt 3 "Not Available" 2 "Error" 1 "Contactor Closed" 0 "Contactor Open" ;
VAL_ 2364730110 CellTempDiffStatus 3 "Not Available" 2 "Error" 1 "Cell-to-cell temperature differential exceeds acceptable limits" 0 "Cell-to-cell temperature differential is within acceptable limits" ;
VAL_ 2364729854 CellVDiffStatus 15 "Not Available" 14 "Error" 13 "Reserved" 12 "Reserved" 11 "Reserved" 10 "Reserved" 9 "Reserved" 8 "Reserved" 7 "Reserved" 6 "Reserved" 5 "Reserved" 4 "Exceeds limits and it is not known whether balancing can restore performance" 3 "Exceeds limits and external maintenance balancing cannot restore performance" 2 "Exceeds limits and external maintenance balancing is required" 1 "Exceeds limits and can be corrected via auto-balancing" 0 "Is within acceptable limits" ;
VAL_ 2364729342 ChargePLDueToAnUndefinedCause 3 "Not Available" 2 "Error" 1 "Power limited for this reason" 0 "No power limit for this reason" ;
VAL_ 2364729342 ChargePLDueToBatCur 3 "Not Available" 2 "Error" 1 "Power limited for this reason" 0 "No power limit for this reason" ;
VAL_ 2364729342 ChargePLDueToBatOrCellV 3 "Not Available" 2 "Error" 1 "Power limited for this reason" 0 "No power limit for this reason" ;
VAL_ 2364729342 ChargePLDueToBatDiagCondition 3 "Not Available" 2 "Error" 1 "Power limited for this reason" 0 "No power limit for this reason" ;
VAL_ 2364729342 ChargePLDueToBatTemp 3 "Not Available" 2 "Error" 1 "Power limited for this reason" 0 "No power limit for this reason" ;
VAL_ 2364729342 ChargePLDueToStOfCharge 3 "Not Available" 2 "Error" 1 "Power limited for this reason" 0 "No power limit for this reason" ;
VAL_ 2364729342 DisPLDueToAnUndefinedCause 3 "Not Available" 2 "Error" 1 "Power limited for this reason" 0 "No power limit for this reason" ;
VAL_ 2364729342 DisPLDueToBatCur 3 "Not Available" 2 "Error" 1 "Power limited for this reason" 0 "No power limit for this reason" ;
VAL_ 2364729342 DisPLDueToBatOrCellV 3 "Not Available" 2 "Error" 1 "Power limited for this reason" 0 "No power limit for this reason" ;
VAL_ 2364729342 DisPLDueToBatDiagCondition 3 "Not Available" 2 "Error" 1 "Power limited for this reason" 0 "No power limit for this reason" ;
VAL_ 2364729342 DisPLDueToBatTemp 3 "Not Available" 2 "Error" 1 "Power limited for this reason" 0 "No power limit for this reason" ;
VAL_ 2364729342 DisPLDueToStOfCharge 3 "Not Available" 2 "Error" 1 "Power limited for this reason" 0 "No power limit for this reason" ;
VAL_ 2364728574 Data9EmbeddedIntegritySupport 3 "CRC and Counter are not supported by the sender" 2 "Reserved" 1 "Protection is supported using J1939-76 SHM" 0 "Embedded CRC and Counter are supported by the sender" ;
VAL_ 2364728574 HVESS20ThermalEventDetected 3 "Not available" 2 "Error" 1 "Thermal Event Detected" 0 "No Thermal Event Detected" ;
VAL_ 2364728062 TMSCoolantLvl 3 "Not Available" 2 "Error" 1 "Coolant Level is sufficient" 0 "Coolant Level is not sufficient" ;
VAL_ 2364728062 TMSMode 15 "Not Available" 14 "Faulted" 13 "Reserved" 12 "Reserved" 11 "Reserved" 10 "Reserved" 9 "Reserved" 8 "Reserved" 7 "Reserved" 6 "Reserved" 5 "Maintaining" 4 "Drying" 3 "Heating" 2 "Cooling" 1 "Circulating" 0 "Off" ;
VAL_ 2364728062 TMSHVILStatus 3 "Not Available" 2 "Error" 1 "HVIL Open" 0 "HVIL Closed" ;
VAL_ 2364728062 TMSHtrStatus 3 "Not Available" 2 "Error" 1 "Heater On" 0 "Heater Off" ;
VAL_ 2364727806 Module32OperationalStatus 3 "Not Available" 2 "Error" 1 "Operational" 0 "Not Operational" ;
VAL_ 2364727806 Module31OperationalStatus 3 "Not Available" 2 "Error" 1 "Operational" 0 "Not Operational" ;
VAL_ 2364727806 Module30OperationalStatus 3 "Not Available" 2 "Error" 1 "Operational" 0 "Not Operational" ;
VAL_ 2364727806 Module29OperationalStatus 3 "Not Available" 2 "Error" 1 "Operational" 0 "Not Operational" ;
VAL_ 2364727806 Module28OperationalStatus 3 "Not Available" 2 "Error" 1 "Operational" 0 "Not Operational" ;
VAL_ 2364727806 Module27OperationalStatus 3 "Not Available" 2 "Error" 1 "Operational" 0 "Not Operational" ;
VAL_ 2364727806 Module26OperationalStatus 3 "Not Available" 2 "Error" 1 "Operational" 0 "Not Operational" ;
VAL_ 2364727806 Module25OperationalStatus 3 "Not Available" 2 "Error" 1 "Operational" 0 "Not Operational" ;
VAL_ 2364727806 Module24OperationalStatus 3 "Not Available" 2 "Error" 1 "Operational" 0 "Not Operational" ;
VAL_ 2364727806 Module23OperationalStatus 3 "Not Available" 2 "Error" 1 "Operational" 0 "Not Operational" ;
VAL_ 2364727806 Module22OperationalStatus 3 "Not Available" 2 "Error" 1 "Operational" 0 "Not Operational" ;
VAL_ 2364727806 Module21OperationalStatus 3 "Not Available" 2 "Error" 1 "Operational" 0 "Not Operational" ;
VAL_ 2364727806 Module20OperationalStatus 3 "Not Available" 2 "Error" 1 "Operational" 0 "Not Operational" ;
VAL_ 2364727806 Module19OperationalStatus 3 "Not Available" 2 "Error" 1 "Operational" 0 "Not Operational" ;
VAL_ 2364727806 Module18OperationalStatus 3 "Not Available" 2 "Error" 1 "Operational" 0 "Not Operational" ;
VAL_ 2364727806 Module17OperationalStatus 3 "Not Available" 2 "Error" 1 "Operational" 0 "Not Operational" ;
VAL_ 2364727806 Module16OperationalStatus 3 "Not Available" 2 "Error" 1 "Operational" 0 "Not Operational" ;
VAL_ 2364727806 Module15OperationalStatus 3 "Not Available" 2 "Error" 1 "Operational" 0 "Not Operational" ;
VAL_ 2364727806 Module14OperationalStatus 3 "Not Available" 2 "Error" 1 "Operational" 0 "Not Operational" ;
VAL_ 2364727806 Module13OperationalStatus 3 "Not Available" 2 "Error" 1 "Operational" 0 "Not Operational" ;
VAL_ 2364727806 Module12OperationalStatus 3 "Not Available" 2 "Error" 1 "Operational" 0 "Not Operational" ;
VAL_ 2364727806 Module11OperationalStatus 3 "Not Available" 2 "Error" 1 "Operational" 0 "Not Operational" ;
VAL_ 2364727806 Module10OperationalStatus 3 "Not Available" 2 "Error" 1 "Operational" 0 "Not Operational" ;
VAL_ 2364727806 Module9OperationalStatus 3 "Not Available" 2 "Error" 1 "Operational" 0 "Not Operational" ;
VAL_ 2364727806 Module8OperationalStatus 3 "Not Available" 2 "Error" 1 "Operational" 0 "Not Operational" ;
VAL_ 2364727806 Module7OperationalStatus 3 "Not Available" 2 "Error" 1 "Operational" 0 "Not Operational" ;
VAL_ 2364727806 Module6OperationalStatus 3 "Not Available" 2 "Error" 1 "Operational" 0 "Not Operational" ;
VAL_ 2364727806 Module5OperationalStatus 3 "Not Available" 2 "Error" 1 "Operational" 0 "Not Operational" ;
VAL_ 2364727806 Module4OperationalStatus 3 "Not Available" 2 "Error" 1 "Operational" 0 "Not Operational" ;
VAL_ 2364727806 Module3OperationalStatus 3 "Not Available" 2 "Error" 1 "Operational" 0 "Not Operational" ;
VAL_ 2364727806 Module2OperationalStatus 3 "Not Available" 2 "Error" 1 "Operational" 0 "Not Operational" ;
VAL_ 2364727806 Module1OperationalStatus 3 "Not Available" 2 "Error" 1 "Operational" 0 "Not Operational" ;
VAL_ 2364727294 OperationalStatus 15 "Not Available" 14 "Error" 13 "Reserved" 12 "Reserved" 11 "Reserved" 10 "Reserved" 9 "Reserved" 8 "Reserved" 7 "Reserved" 6 "Disabled by internal decision of HVES controller" 5 "Disabled by external command" 4 "Emergency Power-Down In Process" 3 "Normal Power-Down in Process" 2 "Operational." 1 "Initialization Complete" 0 "Initialization in process" ;
VAL_ 2364727294 HVBusConnectionStatus 15 "Not Available" 14 "Error" 13 "Reserved" 12 "Reserved" 11 "Reserved" 10 "Reserved" 9 "Reserved" 8 "Reserved" 7 "Reserved" 6 "Reserved" 5 "Reserved" 4 "Disconnected,  Precharge Failed" 3 "Disconnection in Process" 2 "Connection in Process" 1 "Connected" 0 "Disconnected, One or more contactors are open" ;
VAL_ 2364727294 InternalChargerStatus 3 "Not Available" 2 "Error" 1 "Charging on" 0 "Charging off" ;
VAL_ 2364727294 CellBalancingActive 3 "Not Available" 2 "Error" 1 "Cell balancing is active" 0 "Cell balancing is not active" ;
VAL_ 2364727294 CellBalanceStatus 3 "Not Available" 2 "Error" 1 "Cells are unbalanced" 0 "Cells are balanced" ;
VAL_ 2364727294 StOfChargeStatus 15 "Not  Available" 14 "Error" 13 "Reserved" 12 "Reserved" 11 "Reserved" 10 "Reserved" 9 "Reserved" 8 "Reserved" 7 "Reserved" 6 "SOC is above its recommended upper limit" 5 "SOC is at its recommended upper limit" 4 "SOC is approaching its recommended upper limit" 3 "SOC is below its recommended lower limit" 2 "SOC is at its recommended lower limit" 1 "SOC is approaching its recommended lower limit" 0 "SOC level is acceptable" ;
VAL_ 2364727294 InertiaSwStatus 3 "Not Available" 2 "Error" 1 "Impact sensed" 0 "No impact sensed" ;
VAL_ 2364727294 HVILStatus 3 "Not Available" 2 "Error" 1 "HVIL Open" 0 "HVIL Closed" ;
VAL_ 2364727294 HVBusPassiveIsolTestStatus 15 "Not available" 14 "Error" 13 "Reserved" 12 "Reserved" 11 "Reserved" 10 "Reserved" 9 "Reserved" 8 "Reserved" 7 "Reserved" 6 "Reserved" 5 "Test complete,  isolation fault" 4 "Test complete,  isolation marginal" 3 "Test complete,  isolation acceptable" 2 "Test in process" 1 "Test requested but not yet in process" 0 "No test requested / No test in process" ;
VAL_ 2364727294 HVBusActiveIsolTestStatus 15 "Not available" 14 "Error" 13 "Reserved" 12 "Reserved" 11 "Reserved" 10 "Reserved" 9 "Reserved" 8 "Reserved" 7 "Reserved" 6 "Reserved" 5 "Test complete,  isolation fault" 4 "Test complete,  isolation marginal" 3 "Test complete,  isolation acceptable" 2 "Test in process" 1 "Test requested but not yet in process" 0 "No test requested / No test in process" ;
VAL_ 2364727294 CenterOfPackContactorSt 3 "Not Available" 2 "Error" 1 "Contactor Closed" 0 "Contactor Open" ;
VAL_ 2364727294 HVBusPreChargeRelaySt 3 "Not Available" 2 "Error" 1 "Relay Closed" 0 "Relay Open" ;
VAL_ 2364727294 HVBusDisconnectForewarning 15 "Not Available" 14 "Error" 13 "Disconnect imminent" 12 "Reserved" 11 "Reserved" 10 "Reserved" 9 "Reserved" 8 "Reserved" 7 "Disconnect imminent due to battery pack current approaching maximum acceptable level" 6 "Disconnect imminent due to cell voltage approaching maximum acceptable level" 5 "Disconnect imminent due to cell voltage approaching minimum acceptable level" 4 "Disconnect imminent due to module voltage approaching maximum acceptable level" 3 "Disconnect imminent due to module voltage approaching minimum acceptable level" 2 "Disconnect imminent due to battery pack voltage approaching maximum acceptable level" 1 "Disconnect imminent due to battery pack voltage approaching minimum acceptable level" 0 "Disconnect not pending" ;
VAL_ 2364727294 HVBusContactorSt16596 3 "Not Available" 2 "Error" 1 "Contactor Closed" 0 "Contactor Open" ;
VAL_ 2364727294 HVBusContactorSt 3 "Not Available" 2 "Error" 1 "Contactor Closed" 0 "Contactor Open" ;
VAL_ 2364726270 CellTempDiffStatus 3 "Not Available" 2 "Error" 1 "Cell-to-cell temperature differential exceeds acceptable limits" 0 "Cell-to-cell temperature differential is within acceptable limits" ;
VAL_ 2364726014 CellVDiffStatus 15 "Not Available" 14 "Error" 13 "Reserved" 12 "Reserved" 11 "Reserved" 10 "Reserved" 9 "Reserved" 8 "Reserved" 7 "Reserved" 6 "Reserved" 5 "Reserved" 4 "Exceeds limits and it is not known whether balancing can restore performance" 3 "Exceeds limits and external maintenance balancing cannot restore performance" 2 "Exceeds limits and external maintenance balancing is required" 1 "Exceeds limits and can be corrected via auto-balancing" 0 "Is within acceptable limits" ;
VAL_ 2364725502 ChargePLDueToAnUndefinedCause 3 "Not Available" 2 "Error" 1 "Power limited for this reason" 0 "No power limit for this reason" ;
VAL_ 2364725502 ChargePLDueToBatCur 3 "Not Available" 2 "Error" 1 "Power limited for this reason" 0 "No power limit for this reason" ;
VAL_ 2364725502 ChargePLDueToBatOrCellV 3 "Not Available" 2 "Error" 1 "Power limited for this reason" 0 "No power limit for this reason" ;
VAL_ 2364725502 ChargePLDueToBatDiagCondition 3 "Not Available" 2 "Error" 1 "Power limited for this reason" 0 "No power limit for this reason" ;
VAL_ 2364725502 ChargePLDueToBatTemp 3 "Not Available" 2 "Error" 1 "Power limited for this reason" 0 "No power limit for this reason" ;
VAL_ 2364725502 ChargePLDueToStOfCharge 3 "Not Available" 2 "Error" 1 "Power limited for this reason" 0 "No power limit for this reason" ;
VAL_ 2364725502 DisPLDueToAnUndefinedCause 3 "Not Available" 2 "Error" 1 "Power limited for this reason" 0 "No power limit for this reason" ;
VAL_ 2364725502 DisPLDueToBatCur 3 "Not Available" 2 "Error" 1 "Power limited for this reason" 0 "No power limit for this reason" ;
VAL_ 2364725502 DisPLDueToBatOrCellV 3 "Not Available" 2 "Error" 1 "Power limited for this reason" 0 "No power limit for this reason" ;
VAL_ 2364725502 DisPLDueToBatDiagCondition 3 "Not Available" 2 "Error" 1 "Power limited for this reason" 0 "No power limit for this reason" ;
VAL_ 2364725502 DisPLDueToBatTemp 3 "Not Available" 2 "Error" 1 "Power limited for this reason" 0 "No power limit for this reason" ;
VAL_ 2364725502 DisPLDueToStOfCharge 3 "Not Available" 2 "Error" 1 "Power limited for this reason" 0 "No power limit for this reason" ;
VAL_ 2364724734 Data9EmbeddedIntegritySupport 3 "CRC and Counter are not supported by the sender" 2 "Reserved" 1 "Protection is supported using J1939-76 SHM" 0 "Embedded CRC and Counter are supported by the sender" ;
VAL_ 2364724734 HVESS19ThermalEventDetected 3 "Not available" 2 "Error" 1 "Thermal Event Detected" 0 "No Thermal Event Detected" ;
VAL_ 2364724222 TMSCoolantLvl 3 "Not Available" 2 "Error" 1 "Coolant Level is sufficient" 0 "Coolant Level is not sufficient" ;
VAL_ 2364724222 TMSMode 15 "Not Available" 14 "Faulted" 13 "Reserved" 12 "Reserved" 11 "Reserved" 10 "Reserved" 9 "Reserved" 8 "Reserved" 7 "Reserved" 6 "Reserved" 5 "Maintaining" 4 "Drying" 3 "Heating" 2 "Cooling" 1 "Circulating" 0 "Off" ;
VAL_ 2364724222 TMSHVILStatus 3 "Not Available" 2 "Error" 1 "HVIL Open" 0 "HVIL Closed" ;
VAL_ 2364724222 TMSHtrStatus 3 "Not Available" 2 "Error" 1 "Heater On" 0 "Heater Off" ;
VAL_ 2364723966 Module32OperationalStatus 3 "Not Available" 2 "Error" 1 "Operational" 0 "Not Operational" ;
VAL_ 2364723966 Module31OperationalStatus 3 "Not Available" 2 "Error" 1 "Operational" 0 "Not Operational" ;
VAL_ 2364723966 Module30OperationalStatus 3 "Not Available" 2 "Error" 1 "Operational" 0 "Not Operational" ;
VAL_ 2364723966 Module29OperationalStatus 3 "Not Available" 2 "Error" 1 "Operational" 0 "Not Operational" ;
VAL_ 2364723966 Module28OperationalStatus 3 "Not Available" 2 "Error" 1 "Operational" 0 "Not Operational" ;
VAL_ 2364723966 Module27OperationalStatus 3 "Not Available" 2 "Error" 1 "Operational" 0 "Not Operational" ;
VAL_ 2364723966 Module26OperationalStatus 3 "Not Available" 2 "Error" 1 "Operational" 0 "Not Operational" ;
VAL_ 2364723966 Module25OperationalStatus 3 "Not Available" 2 "Error" 1 "Operational" 0 "Not Operational" ;
VAL_ 2364723966 Module24OperationalStatus 3 "Not Available" 2 "Error" 1 "Operational" 0 "Not Operational" ;
VAL_ 2364723966 Module23OperationalStatus 3 "Not Available" 2 "Error" 1 "Operational" 0 "Not Operational" ;
VAL_ 2364723966 Module22OperationalStatus 3 "Not Available" 2 "Error" 1 "Operational" 0 "Not Operational" ;
VAL_ 2364723966 Module21OperationalStatus 3 "Not Available" 2 "Error" 1 "Operational" 0 "Not Operational" ;
VAL_ 2364723966 Module20OperationalStatus 3 "Not Available" 2 "Error" 1 "Operational" 0 "Not Operational" ;
VAL_ 2364723966 Module19OperationalStatus 3 "Not Available" 2 "Error" 1 "Operational" 0 "Not Operational" ;
VAL_ 2364723966 Module18OperationalStatus 3 "Not Available" 2 "Error" 1 "Operational" 0 "Not Operational" ;
VAL_ 2364723966 Module17OperationalStatus 3 "Not Available" 2 "Error" 1 "Operational" 0 "Not Operational" ;
VAL_ 2364723966 Module16OperationalStatus 3 "Not Available" 2 "Error" 1 "Operational" 0 "Not Operational" ;
VAL_ 2364723966 Module15OperationalStatus 3 "Not Available" 2 "Error" 1 "Operational" 0 "Not Operational" ;
VAL_ 2364723966 Module14OperationalStatus 3 "Not Available" 2 "Error" 1 "Operational" 0 "Not Operational" ;
VAL_ 2364723966 Module13OperationalStatus 3 "Not Available" 2 "Error" 1 "Operational" 0 "Not Operational" ;
VAL_ 2364723966 Module12OperationalStatus 3 "Not Available" 2 "Error" 1 "Operational" 0 "Not Operational" ;
VAL_ 2364723966 Module11OperationalStatus 3 "Not Available" 2 "Error" 1 "Operational" 0 "Not Operational" ;
VAL_ 2364723966 Module10OperationalStatus 3 "Not Available" 2 "Error" 1 "Operational" 0 "Not Operational" ;
VAL_ 2364723966 Module9OperationalStatus 3 "Not Available" 2 "Error" 1 "Operational" 0 "Not Operational" ;
VAL_ 2364723966 Module8OperationalStatus 3 "Not Available" 2 "Error" 1 "Operational" 0 "Not Operational" ;
VAL_ 2364723966 Module7OperationalStatus 3 "Not Available" 2 "Error" 1 "Operational" 0 "Not Operational" ;
VAL_ 2364723966 Module6OperationalStatus 3 "Not Available" 2 "Error" 1 "Operational" 0 "Not Operational" ;
VAL_ 2364723966 Module5OperationalStatus 3 "Not Available" 2 "Error" 1 "Operational" 0 "Not Operational" ;
VAL_ 2364723966 Module4OperationalStatus 3 "Not Available" 2 "Error" 1 "Operational" 0 "Not Operational" ;
VAL_ 2364723966 Module3OperationalStatus 3 "Not Available" 2 "Error" 1 "Operational" 0 "Not Operational" ;
VAL_ 2364723966 Module2OperationalStatus 3 "Not Available" 2 "Error" 1 "Operational" 0 "Not Operational" ;
VAL_ 2364723966 Module1OperationalStatus 3 "Not Available" 2 "Error" 1 "Operational" 0 "Not Operational" ;
